VERSION ""

NS_ :

BS_:

BU_: VMCU TECU OBDScanT2 IC3 EMS ECUspare2 ECUspare1 DACU CIOM BBM

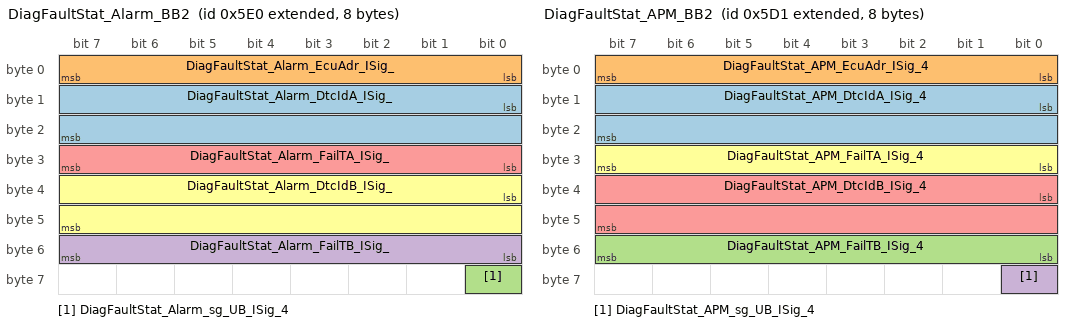
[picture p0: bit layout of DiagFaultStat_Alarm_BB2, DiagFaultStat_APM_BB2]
BO_ 2147485152 DiagFaultStat_Alarm_BB2: 8 CIOM
 SG_ DiagFaultStat_Alarm_DtcIdA_ISig_ : 8|16@1+ (1,0) [0|65535] ""  IC3
 SG_ DiagFaultStat_Alarm_EcuAdr_ISig_ : 0|8@1+ (1,0) [0|255] ""  IC3
 SG_ DiagFaultStat_Alarm_sg_UB_ISig_4 : 56|1@1+ (1,0) [0|0] ""  IC3
 SG_ DiagFaultStat_Alarm_FailTB_ISig_ : 48|8@1+ (1,0) [0|255] ""  IC3
 SG_ DiagFaultStat_Alarm_FailTA_ISig_ : 24|8@1+ (1,0) [0|255] ""  IC3
 SG_ DiagFaultStat_Alarm_DtcIdB_ISig_ : 32|16@1+ (1,0) [0|65535] ""  IC3

BO_ 2147485137 DiagFaultStat_APM_BB2: 8 VMCU
 SG_ DiagFaultStat_APM_DtcIdA_ISig_4 : 8|16@1+ (1,0) [0|65535] ""  IC3
 SG_ DiagFaultStat_APM_EcuAdr_ISig_4 : 0|8@1+ (1,0) [0|255] ""  IC3
 SG_ DiagFaultStat_APM_FailTB_ISig_4 : 48|8@1+ (1,0) [0|255] ""  IC3
 SG_ DiagFaultStat_APM_sg_UB_ISig_4 : 56|1@1+ (1,0) [0|0] ""  IC3
 SG_ DiagFaultStat_APM_DtcIdB_ISig_4 : 32|16@1+ (1,0) [0|65535] ""  IC3
 SG_ DiagFaultStat_APM_FailTA_ISig_4 : 24|8@1+ (1,0) [0|255] ""  IC3

BO_ 2147485567 Debug9_TECU_BB2: 8 TECU
 SG_ Debug_9_TECU : 0|64@1+ (1,0) [0|0] "" Vector__XXX

BO_ 2147485620 Debug9_DACU_BB2: 8 DACU
 SG_ Debug_9_DACU : 0|64@1+ (1,0) [0|0] "" Vector__XXX

BO_ 2147485566 Debug8_TECU_BB2: 8 TECU
 SG_ Debug_8_TECU : 0|64@1+ (1,0) [0|0] "" Vector__XXX

BO_ 2147485619 Debug8_DACU_BB2: 8 DACU
 SG_ Debug_8_DACU : 0|64@1+ (1,0) [0|0] "" Vector__XXX

BO_ 2147485565 Debug7_TECU_BB2: 8 TECU
 SG_ Debug_7_TECU : 0|64@1+ (1,0) [0|0] "" Vector__XXX

BO_ 2147485617 Debug7_DACU_BB2: 8 DACU
 SG_ Debug_7_DACU : 0|64@1+ (1,0) [0|0] "" Vector__XXX

BO_ 2147485618 Debug7_BBM_BB2: 8 BBM
 SG_ Debug_7_BBM : 0|64@1+ (1,0) [0|0] "" Vector__XXX

BO_ 2147485611 Debug6_VMCU_BB2: 8 VMCU
 SG_ Debug_6_VMCU : 0|64@1+ (1,0) [0|0] "" Vector__XXX

BO_ 2147485564 Debug6_TECU_BB2: 8 TECU
 SG_ Debug_6_TECU : 0|64@1+ (1,0) [0|0] "" Vector__XXX

BO_ 2147485614 Debug6_HMIIOM_BB2: 8 IC3
 SG_ Debug_6_HMIIOM : 0|64@1+ (1,0) [0|0] "" Vector__XXX

BO_ 2147485609 Debug6_EMS_BB2: 8 EMS
 SG_ Debug_6_EMS : 0|64@1+ (1,0) [0|0] "" Vector__XXX

BO_ 2147485613 Debug6_DACU_BB2: 8 DACU
 SG_ Debug_6_DACU : 0|64@1+ (1,0) [0|0] "" Vector__XXX

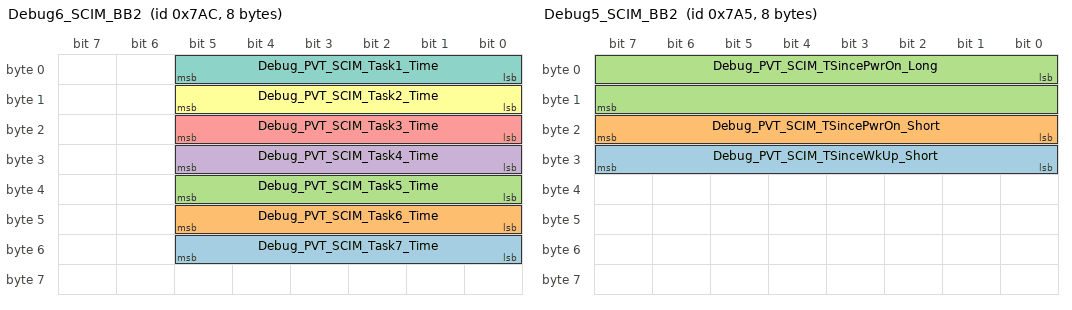
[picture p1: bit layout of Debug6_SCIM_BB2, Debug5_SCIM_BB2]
BO_ 1964 Debug6_SCIM_BB2: 8 CIOM
 SG_ Debug_PVT_SCIM_Task7_Time : 48|6@1+ (0.1,0) [0|6.3] "ms"  ECUspare1
 SG_ Debug_PVT_SCIM_Task6_Time : 40|6@1+ (0.1,0) [0|6.3] "ms"  ECUspare1
 SG_ Debug_PVT_SCIM_Task5_Time : 32|6@1+ (0.1,0) [0|6.3] "ms"  ECUspare1
 SG_ Debug_PVT_SCIM_Task4_Time : 24|6@1+ (0.1,0) [0|6.3] "ms"  ECUspare1
 SG_ Debug_PVT_SCIM_Task3_Time : 16|6@1+ (0.1,0) [0|6.3] "ms"  ECUspare1
 SG_ Debug_PVT_SCIM_Task2_Time : 8|6@1+ (0.1,0) [0|6.3] "ms"  ECUspare1
 SG_ Debug_PVT_SCIM_Task1_Time : 0|6@1+ (0.1,0) [0|6.3] "ms"  ECUspare1

BO_ 2147485615 Debug6_BBM_BB2: 8 BBM
 SG_ Debug_6_BBM : 0|64@1+ (1,0) [0|0] "" Vector__XXX

BO_ 2147485604 Debug5_VMCU_BB2: 8 VMCU
 SG_ Debug_5_VMCU : 0|64@1+ (1,0) [0|0] "" Vector__XXX

BO_ 2147485563 Debug5_TECU_BB2: 8 TECU
 SG_ Debug_5_TECU : 0|64@1+ (1,0) [0|0] "" Vector__XXX

BO_ 2147485607 Debug5_HMIIOM_BB2: 8 IC3
 SG_ Debug_5_HMIIOM : 0|64@1+ (1,0) [0|0] "" Vector__XXX

BO_ 2147485602 Debug5_EMS_BB2: 8 EMS
 SG_ Debug_5_EMS : 0|64@1+ (1,0) [0|0] "" Vector__XXX

BO_ 2147485606 Debug5_DACU_BB2: 8 DACU
 SG_ Debug_5_DACU : 0|64@1+ (1,0) [0|0] "" Vector__XXX

BO_ 1957 Debug5_SCIM_BB2: 8 CIOM
 SG_ Debug_PVT_SCIM_TSinceWkUp_Short : 24|8@1+ (20,0) [0|5100] "ms"  ECUspare1
 SG_ Debug_PVT_SCIM_TSincePwrOn_Short : 16|8@1+ (20,0) [0|5100] "ms"  ECUspare1
 SG_ Debug_PVT_SCIM_TSincePwrOn_Long : 0|16@1+ (1,0) [0|65535] "s"  ECUspare1

BO_ 2147485608 Debug5_BBM_BB2: 8 BBM
 SG_ Debug_5_BBM : 0|64@1+ (1,0) [0|0] "" Vector__XXX

BO_ 2147485597 Debug4_VMCU_BB2: 8 VMCU
 SG_ Debug_4_VMCU : 0|64@1+ (1,0) [0|0] "" Vector__XXX

BO_ 2147485562 Debug4_TECU_BB2: 8 TECU
 SG_ Debug_4_TECU : 0|64@1+ (1,0) [0|0] "" Vector__XXX

BO_ 2147485600 Debug4_HMIIOM_BB2: 8 IC3
 SG_ Debug_4_HMIIOM : 0|64@1+ (1,0) [0|0] "" Vector__XXX

BO_ 2147485595 Debug4_EMS_BB2: 8 EMS
 SG_ Debug_4_EMS : 0|64@1+ (1,0) [0|0] "" Vector__XXX

BO_ 2147485599 Debug4_DACU_BB2: 8 DACU
 SG_ Debug_4_DACU : 0|64@1+ (1,0) [0|0] "" Vector__XXX

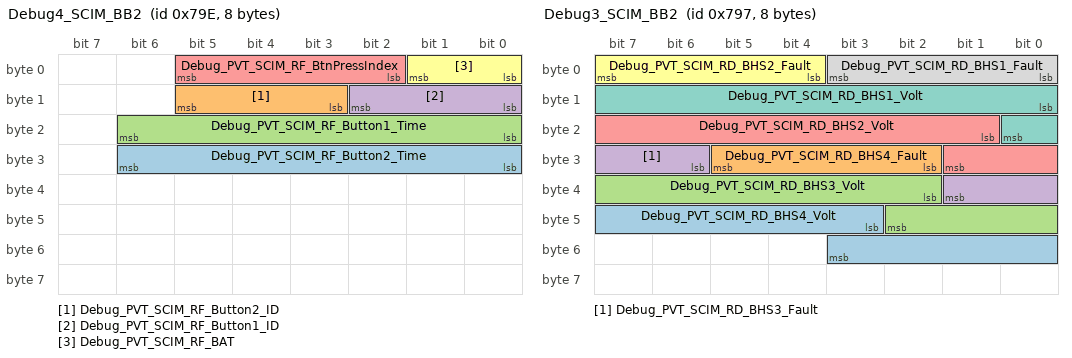
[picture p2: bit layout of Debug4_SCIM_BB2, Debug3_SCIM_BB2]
BO_ 1950 Debug4_SCIM_BB2: 8 CIOM
 SG_ Debug_PVT_SCIM_RF_Button2_Time : 24|7@1+ (1,0) [0|127] ""  ECUspare1
 SG_ Debug_PVT_SCIM_RF_Button2_ID : 11|3@1+ (1,0) [0|7] ""  ECUspare1
 SG_ Debug_PVT_SCIM_RF_Button1_Time : 16|7@1+ (1,0) [0|127] ""  ECUspare1
 SG_ Debug_PVT_SCIM_RF_Button1_ID : 8|3@1+ (1,0) [0|7] ""  ECUspare1
 SG_ Debug_PVT_SCIM_RF_BtnPressIndex : 2|4@1+ (1,0) [0|15] ""  ECUspare1
 SG_ Debug_PVT_SCIM_RF_BAT : 0|2@1+ (1,0) [0|3] ""  ECUspare1

BO_ 2147485601 Debug4_BBM_BB2: 8 BBM
 SG_ Debug_4_BBM : 0|64@1+ (1,0) [0|0] "" Vector__XXX

BO_ 2147485590 Debug3_VMCU_BB2: 8 VMCU
 SG_ Debug_3_VMCU : 0|64@1+ (1,0) [0|0] "" Vector__XXX

BO_ 2147485545 Debug3_TECU_BB2: 8 TECU
 SG_ Debug_3_TECU : 0|64@1+ (1,0) [0|0] "" Vector__XXX

BO_ 2147485593 Debug3_HMIIOM_BB2: 8 IC3
 SG_ Debug_3_HMIIOM : 0|64@1+ (1,0) [0|0] "" Vector__XXX

BO_ 2147485588 Debug3_EMS_BB2: 8 EMS
 SG_ Debug_3_EMS : 0|64@1+ (1,0) [0|0] "" Vector__XXX

BO_ 2147485592 Debug3_DACU_BB2: 8 DACU
 SG_ Debug_3_DACU : 0|64@1+ (1,0) [0|0] "" Vector__XXX

BO_ 1943 Debug3_SCIM_BB2: 8 CIOM
 SG_ Debug_PVT_SCIM_RD_BHS4_Volt : 43|9@1+ (0.1,0) [0|51] "V"  ECUspare1
 SG_ Debug_PVT_SCIM_RD_BHS4_Fault : 26|4@1+ (1,0) [0|15] "0"  ECUspare1
 SG_ Debug_PVT_SCIM_RD_BHS3_Volt : 34|9@1+ (0.1,0) [0|51] "V"  ECUspare1
 SG_ Debug_PVT_SCIM_RD_BHS3_Fault : 30|4@1+ (1,0) [0|15] "0"  ECUspare1
 SG_ Debug_PVT_SCIM_RD_BHS2_Volt : 17|9@1+ (0.1,0) [0|51] "V"  ECUspare1
 SG_ Debug_PVT_SCIM_RD_BHS2_Fault : 4|4@1+ (1,0) [0|15] "0"  ECUspare1
 SG_ Debug_PVT_SCIM_RD_BHS1_Volt : 8|9@1+ (0.1,0) [0|51] "V"  ECUspare1
 SG_ Debug_PVT_SCIM_RD_BHS1_Fault : 0|4@1+ (1,0) [0|15] "0"  ECUspare1

BO_ 2147485594 Debug3_BBM_BB2: 8 BBM
 SG_ Debug_3_BBM : 0|64@1+ (1,0) [0|0] "" Vector__XXX

BO_ 2147485583 Debug2_VMCU_BB2: 8 VMCU
 SG_ Debug_2_VMCU : 0|64@1+ (1,0) [0|0] "" Vector__XXX

BO_ 2147485544 Debug2_TECU_BB2: 8 TECU
 SG_ Debug_2_TECU : 0|64@1+ (1,0) [0|0] "" Vector__XXX

BO_ 2147485586 Debug2_HMIIOM_BB2: 8 IC3
 SG_ Debug_2_HMIIOM : 0|64@1+ (1,0) [0|0] "" Vector__XXX

BO_ 2147485581 Debug2_EMS_BB2: 8 EMS
 SG_ Debug_2_EMS : 0|64@1+ (1,0) [0|0] "" Vector__XXX

BO_ 2147485585 Debug2_DACU_BB2: 8 DACU
 SG_ Debug_2_DACU : 0|64@1+ (1,0) [0|0] "" Vector__XXX

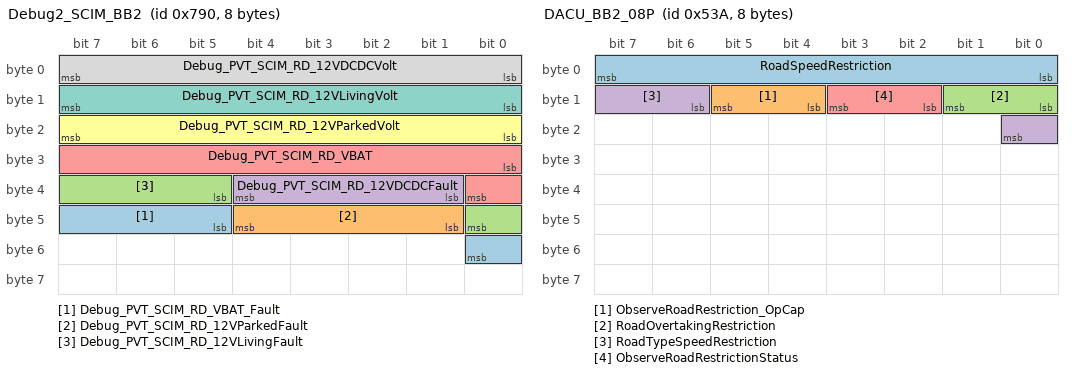
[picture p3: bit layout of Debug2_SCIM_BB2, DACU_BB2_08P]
BO_ 1936 Debug2_SCIM_BB2: 8 CIOM
 SG_ Debug_PVT_SCIM_RD_VBAT_Fault : 45|4@1+ (1,0) [0|15] ""  ECUspare1
 SG_ Debug_PVT_SCIM_RD_12VParkedFault : 41|4@1+ (1,0) [0|15] ""  ECUspare1
 SG_ Debug_PVT_SCIM_RD_12VLivingFault : 37|4@1+ (1,0) [0|15] ""  ECUspare1
 SG_ Debug_PVT_SCIM_RD_12VDCDCFault : 33|4@1+ (1,0) [0|15] ""  ECUspare1
 SG_ Debug_PVT_SCIM_RD_VBAT : 24|9@1+ (0.1,0) [0|51] "V"  ECUspare1
 SG_ Debug_PVT_SCIM_RD_12VParkedVolt : 16|8@1+ (0.25,0) [0|63] "V"  ECUspare1
 SG_ Debug_PVT_SCIM_RD_12VLivingVolt : 8|8@1+ (0.25,0) [0|63] "V"  ECUspare1
 SG_ Debug_PVT_SCIM_RD_12VDCDCVolt : 0|8@1+ (0.25,0) [0|63] "V"  ECUspare1

BO_ 2147485587 Debug2_BBM_BB2: 8 BBM
 SG_ Debug_2_BBM : 0|64@1+ (1,0) [0|0] "" Vector__XXX

BO_ 2147485616 Debug21_TECU_BB2: 8 TECU
 SG_ Debug_21_TECU : 0|64@1+ (1,0) [0|0] "" Vector__XXX

BO_ 2147485610 Debug20_TECU_BB2: 8 TECU
 SG_ Debug_20_TECU : 0|64@1+ (1,0) [0|0] "" Vector__XXX

BO_ 2147485576 Debug1_VMCU_BB2: 8 Vector__XXX
 SG_ Debug_1_VMCU : 0|64@1+ (1,0) [0|0] ""  VMCU

BO_ 2147485575 Debug1_TECU_BB2: 8 Vector__XXX
 SG_ Debug_1_TECU : 0|64@1+ (1,0) [0|0] ""  TECU

BO_ 2147485579 Debug1_HMIIOM_BB2: 8 Vector__XXX
 SG_ Debug_1_HMIIOM : 0|64@1+ (1,0) [0|0] ""  IC3

BO_ 2147485574 Debug1_EMS_BB2: 8 Vector__XXX
 SG_ Debug_1_EMS : 0|64@1+ (1,0) [0|0] ""  EMS

BO_ 2147485578 Debug1_DACU_BB2: 8 Vector__XXX
 SG_ Debug_1_DACU : 0|64@1+ (1,0) [0|0] ""  DACU

BO_ 1929 Debug1_CIOM_BB2: 8 ECUspare1
 SG_ Debug_1_CIOM : 16|64@1+ (1,0) [0|0] "" Vector__XXX

BO_ 2147485580 Debug1_BBM_BB2: 8 Vector__XXX
 SG_ Debug_1_BBM : 0|64@1+ (1,0) [0|0] ""  BBM

BO_ 2147485603 Debug19_TECU_BB2: 8 TECU
 SG_ Debug_19_TECU : 0|64@1+ (1,0) [0|0] "" Vector__XXX

BO_ 2147485596 Debug18_TECU_BB2: 8 TECU
 SG_ Debug_18_TECU : 0|64@1+ (1,0) [0|0] "" Vector__XXX

BO_ 2147485589 Debug17_TECU_BB2: 8 TECU
 SG_ Debug_17_TECU : 0|64@1+ (1,0) [0|0] "" Vector__XXX

BO_ 2147485582 Debug16_TECU_BB2: 8 TECU
 SG_ Debug_16_TECU : 0|64@1+ (1,0) [0|0] "" Vector__XXX

BO_ 2147485573 Debug15_TECU_BB2: 8 TECU
 SG_ Debug_15_TECU : 0|64@1+ (1,0) [0|0] "" Vector__XXX

BO_ 2147485572 Debug14_TECU_BB2: 8 TECU
 SG_ Debug_14_TECU : 0|64@1+ (1,0) [0|0] "" Vector__XXX

BO_ 2147485571 Debug13_TECU_BB2: 8 TECU
 SG_ Debug_13_TECU : 0|64@1+ (1,0) [0|0] "" Vector__XXX

BO_ 2147485570 Debug12_TECU_BB2: 8 TECU
 SG_ Debug_12_TECU : 0|64@1+ (1,0) [0|0] "" Vector__XXX

BO_ 2147485569 Debug11_TECU_BB2: 8 TECU
 SG_ Debug_11_TECU : 0|64@1+ (1,0) [0|0] "" Vector__XXX

BO_ 2147485622 Debug11_DACU_BB2: 8 DACU
 SG_ Debug_11_DACU : 0|64@1+ (1,0) [0|0] "" Vector__XXX

BO_ 2634017304 Debug10_TECU_BB2: 8 TECU
 SG_ Debug_10_TECU : 0|64@1+ (1,0) [0|0] "" Vector__XXX

BO_ 2634021456 Debug10_DACU_BB2: 8 DACU
 SG_ Debug_10_DACU : 0|64@1+ (1,0) [0|0] "" Vector__XXX

BO_ 1338 DACU_BB2_08P: 8 DACU
 SG_ RoadSpeedRestriction : 0|8@1+ (1,0) [0|255] "NotApplicable"  IC3
 SG_ ObserveRoadRestriction_OpCap : 12|2@1+ (1,0) [0|0] ""  IC3
 SG_ RoadOvertakingRestriction : 8|2@1+ (1,0) [0|0] ""  IC3
 SG_ RoadTypeSpeedRestriction : 14|3@1+ (1,0) [0|0] ""  IC3
 SG_ ObserveRoadRestrictionStatus : 10|2@1+ (1,0) [0|0] ""  IC3

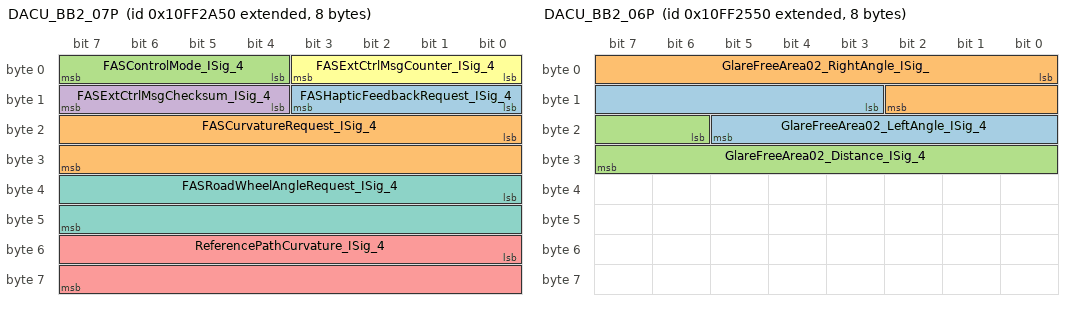
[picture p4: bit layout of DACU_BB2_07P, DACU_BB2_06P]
BO_ 2432641616 DACU_BB2_07P: 8 DACU
 SG_ FASHapticFeedbackRequest_ISig_4 : 8|4@1+ (1,0) [0|0] ""  VMCU
 SG_ FASCurvatureRequest_ISig_4 : 16|16@1+ (7.62939E-006,-0.2472) [-0.2472|0.25279207365] "per_meter"  VMCU
 SG_ FASControlMode_ISig_4 : 4|4@1+ (0.1,0) [0|1.5] ""  VMCU
 SG_ FASExtCtrlMsgChecksum_ISig_4 : 12|4@1+ (1,0) [0|0] ""  VMCU
 SG_ ReferencePathCurvature_ISig_4 : 48|16@1+ (7.62939E-006,-0.2472) [-0.2472|0.25279207365] "per_meter"  VMCU
 SG_ FASExtCtrlMsgCounter_ISig_4 : 0|4@1+ (1,0) [0|0] ""  VMCU
 SG_ FASRoadWheelAngleRequest_ISig_4 : 32|16@1+ (5E-005,-1.6) [-1.6|1.67675] "rad"  VMCU

BO_ 2432640336 DACU_BB2_06P: 8 DACU
 SG_ GlareFreeArea02_LeftAngle_ISig_4 : 11|11@1+ (0.0494,-31.65) [-31.65|69.4718] "deg"  VMCU
 SG_ GlareFreeArea02_RightAngle_ISig_ : 0|11@1+ (0.0494,-31.65) [-31.65|69.4718] "deg"  VMCU
 SG_ GlareFreeArea02_Distance_ISig_4 : 22|10@1+ (0.5,0) [0|511.5] "m"  VMCU

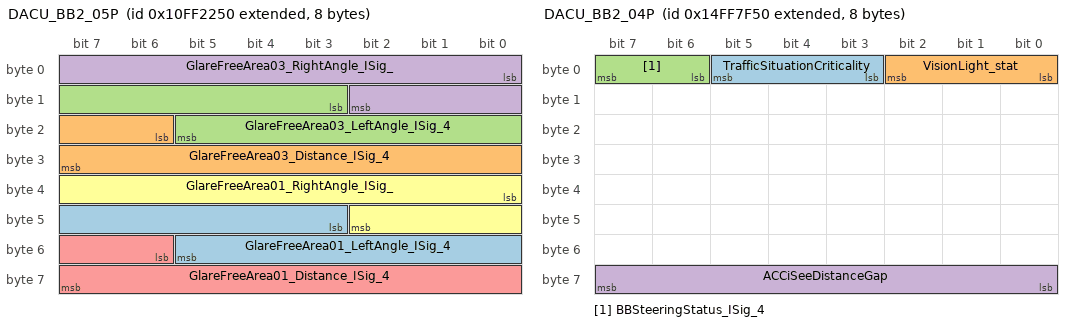
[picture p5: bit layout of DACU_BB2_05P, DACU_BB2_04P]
BO_ 2432639568 DACU_BB2_05P: 8 DACU
 SG_ GlareFreeArea01_LeftAngle_ISig_4 : 43|11@1+ (0.0494,-31.65) [-31.65|69.4718] "deg"  VMCU
 SG_ GlareFreeArea03_Distance_ISig_4 : 22|10@1+ (0.5,0) [0|511.5] "m"  VMCU
 SG_ GlareFreeArea03_LeftAngle_ISig_4 : 11|11@1+ (0.0494,-31.65) [-31.65|69.4718] "deg"  VMCU
 SG_ GlareFreeArea03_RightAngle_ISig_ : 0|11@1+ (0.0494,-31.65) [-31.65|69.4718] "deg"  VMCU
 SG_ GlareFreeArea01_Distance_ISig_4 : 54|10@1+ (0.5,0) [0|511.5] "m"  VMCU
 SG_ GlareFreeArea01_RightAngle_ISig_ : 32|11@1+ (0.0494,-31.65) [-31.65|69.4718] "deg"  VMCU

BO_ 2499772240 DACU_BB2_04P: 8 DACU
 SG_ TrafficSituationCriticality : 3|3@1+ (1,0) [0|7] ""  IC3
 SG_ VisionLight_stat : 0|3@1+ (1,0) [0|0] ""  VMCU
 SG_ BBSteeringStatus_ISig_4 : 6|2@1+ (1,0) [0|0] ""  BBM
 SG_ ACCiSeeDistanceGap : 56|8@1+ (1,-127) [-127|128] "m"  TECU

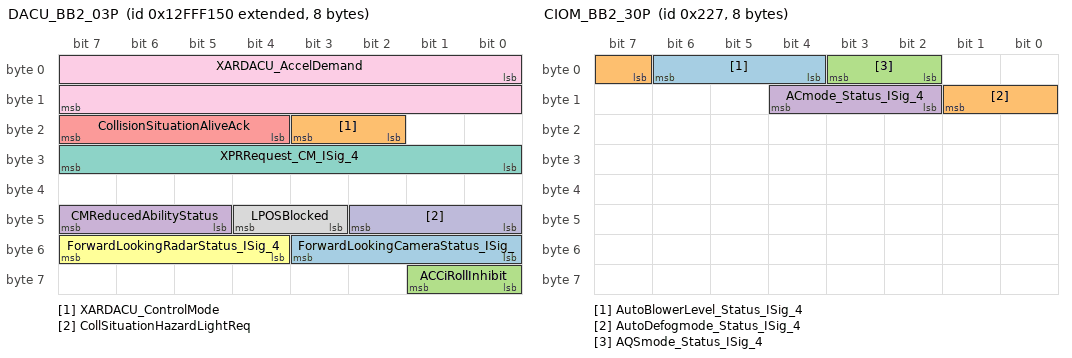
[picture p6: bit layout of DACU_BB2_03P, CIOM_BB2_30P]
BO_ 2466246992 DACU_BB2_03P: 8 DACU
 SG_ ForwardLookingCameraStatus_ISig_ : 48|4@1+ (1,0) [0|0] ""  IC3
 SG_ XARDACU_ControlMode : 18|2@1+ (1,0) [0|0] ""  EMS,TECU
 SG_ ACCiRollInhibit : 56|2@1+ (1,0) [0|0] ""  TECU
 SG_ CMReducedAbilityStatus : 45|3@1+ (1,0) [0|0] ""  IC3
 SG_ CollisionSituationAliveAck : 20|4@1+ (1,0) [0|15] "Count"  VMCU
 SG_ ForwardLookingRadarStatus_ISig_4 : 52|4@1+ (1,0) [0|0] ""  IC3
 SG_ XPRRequest_CM_ISig_4 : 24|8@1+ (1,0) [0|255] "NotApplicable"  VMCU
 SG_ LPOSBlocked : 43|2@1+ (1,0) [0|0] ""  IC3
 SG_ XARDACU_AccelDemand : 0|16@1+ (0.00048828125,-15.687) [-15.687|16.31251171875] "m_per_s_squared"  EMS,TECU
 SG_ CollSituationHazardLightReq : 40|3@1+ (1,0) [0|0] ""  VMCU

BO_ 2432690512 DACU_BB2_02P: 8 DACU
 SG_ PathDeviationDriverAlert : 24|3@1+ (1,0) [0|0] ""  IC3,VMCU
 SG_ CM_DisengageDrivelineRequest : 51|2@1+ (1,0) [0|0] ""  TECU
 SG_ ACCBrakeRequestStatus : 30|2@1+ (1,0) [0|0] ""  VMCU
 SG_ FrontalCollisionDriverAlert_ISig : 19|3@1+ (1,0) [0|0] ""  IC3,VMCU
 SG_ ACC_SGOFaultCondStat_SeatBelt : 59|1@1+ (1,0) [0|0] ""  IC3
 SG_ CM_Status_ISig_4 : 43|3@1+ (1,0) [0|0] ""  CIOM,VMCU,IC3
 SG_ DASApplicationStatus : 40|3@1+ (1,0) [0|0] ""  IC3,VMCU,CIOM
 SG_ ACC_Status : 16|3@1+ (1,0) [0|0] ""  VMCU,IC3,TECU
 SG_ LKSApplicationStatus : 27|3@1+ (1,0) [0|0] ""  CIOM,VMCU,IC3
 SG_ LCSSystemStatus : 48|3@1+ (1,0) [0|0] ""  IC3,CIOM
 SG_ ACC_SGOFaultCondStat_SigStat : 60|1@1+ (1,0) [0|0] ""  IC3
 SG_ ACC_SGOFaultCondStat_Target : 58|1@1+ (1,0) [0|0] ""  IC3
 SG_ FCW_Status : 46|2@1+ (1,0) [0|0] ""  IC3,CIOM,VMCU
 SG_ DriverImpairedDriverAlert : 32|3@1+ (1,0) [0|0] ""  IC3,VMCU
 SG_ DriverVigilanceLevel : 35|3@1+ (1,0) [0|0] ""  IC3,VMCU
 SG_ ACCForwardVehicleSpeed_ISig_4 : 8|8@1+ (1,0) [0|255] "Km_per_h"  TECU,IC3
 SG_ ACC_SGOFaultCondStat_Door : 57|1@1+ (1,0) [0|0] ""  IC3
 SG_ ACCTargetDetected : 22|2@1+ (1,0) [0|0] ""  IC3
 SG_ ACCForwardVehicleDistance_ISig_4 : 0|8@1+ (1,0) [0|255] "m"  IC3,TECU
 SG_ LKSCorrectiveSteeringStatus : 61|3@1+ (1,0) [0|0] ""  CIOM
 SG_ ACC_SGOFaultCondStat_Other : 55|1@1+ (1,0) [0|0] ""  IC3
 SG_ LCSSoundSettingStatus : 53|2@1+ (1,0) [0|0] ""  IC3
 SG_ ACC_SGOFaultCondStat_Speed : 56|1@1+ (1,0) [0|0] ""  IC3

BO_ 936 CIOM_BB2_32S_FCM: 8 TECU
 SG_ CIOM_BB2_32S_FCS : 0|64@1+ (1,0) [0|0] ""  CIOM

BO_ 935 CIOM_BB2_32S: 16 CIOM
 SG_ EncryptedGBUnlockAuth_stat : 0|128@1+ (1,0) [0|0] ""  TECU

BO_ 1369 CIOM_BB2_31S: 8 CIOM
 SG_ ParkClimTimerStat_Tue_ISig_4 : 15|1@1+ (1,0) [0|0] ""  IC3
 SG_ ParkClimTimerStat_Mon_ISig_4 : 17|1@1+ (1,0) [0|0] ""  IC3
 SG_ ParkClimTimerStat_Hrs_ISig_4 : 31|8@1+ (1,0) [0|255] "h"  IC3
 SG_ ParkClimTimerStat_TotalNoTimers_ : 23|8@1+ (1,0) [0|0] ""  IC3
 SG_ ParkClimTimerStat_Thu_ISig_4 : 16|1@1+ (1,0) [0|0] ""  IC3
 SG_ ParkClimTimerStat_MinRes_ISig_4 : 7|3@1+ (1,0) [0|0] ""  IC3
 SG_ ParkClimTimerStat_Status_ISig_4 : 13|2@1+ (1,0) [0|0] ""  IC3
 SG_ ParkClimTimerStat_Sun_ISig_4 : 20|1@1+ (1,0) [0|0] ""  IC3
 SG_ ParkClimTimerStat_sg_UB_ISig_4 : 63|1@1+ (1,0) [0|0] ""  IC3
 SG_ ParkClimTimerStat_TimerNr_ISig_4 : 39|8@1+ (1,0) [0|0] ""  IC3
 SG_ ParkClimTimerStat_Rec_ISig_4 : 19|1@1+ (1,0) [0|0] ""  IC3
 SG_ ParkClimTimerStat_Wed_ISig_4 : 22|1@1+ (1,0) [0|0] ""  IC3
 SG_ ParkClimTimerStat_Min_ISig_4 : 55|8@1+ (1,0) [0|255] "min"  IC3
 SG_ ParkClimTimerStat_Type_ISig_4 : 10|3@1+ (1,0) [0|0] ""  IC3
 SG_ ParkClimTimerStat_Sat_ISig_4 : 21|1@1+ (1,0) [0|0] ""  IC3
 SG_ ParkClimTimerStat_Temp_ISig_4 : 47|8@1+ (0.5,0) [0|127.5] "DegreeC"  IC3
 SG_ ParkClimTimerStat_Dur_ISig_4 : 0|7@1+ (1,0) [0|127] "min"  IC3
 SG_ ParkClimTimerStat_Fri_ISig_4 : 18|1@1+ (1,0) [0|0] ""  IC3

BO_ 551 CIOM_BB2_30P: 8 CIOM
 SG_ AutoBlowerLevel_Status_ISig_4 : 4|3@1+ (1,0) [0|0] ""  IC3
 SG_ AutoDefogmode_Status_ISig_4 : 7|3@1+ (1,0) [0|0] ""  IC3
 SG_ AQSmode_Status_ISig_4 : 2|2@1+ (1,0) [0|0] ""  IC3
 SG_ ACmode_Status_ISig_4 : 10|3@1+ (1,0) [0|0] ""  IC3

BO_ 2432685120 CIOM_BB2_29P: 8 CIOM
 SG_ LKSCSEnableSwitch_rqst : 0|2@1+ (1,0) [0|0] ""  DACU

BO_ 2566078272 CIOM_BB2_28P: 8 CIOM
 SG_ TrafficAccidentHazardLightRqst_I : 4|2@1+ (1,0) [0|0] ""  VMCU
 SG_ GearboxUnlockAuth_stat : 6|3@1+ (1,0) [0|0] ""  TECU

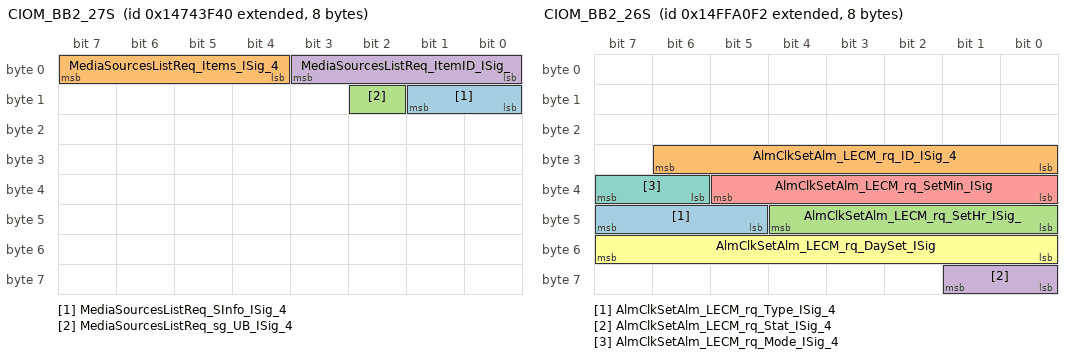
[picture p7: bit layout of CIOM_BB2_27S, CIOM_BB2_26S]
BO_ 2490646336 CIOM_BB2_27S: 8 CIOM
 SG_ MediaSourcesListReq_SInfo_ISig_4 : 8|2@1+ (1,0) [0|0] ""  IC3
 SG_ MediaSourcesListReq_Items_ISig_4 : 4|4@1+ (1,0) [0|0] ""  IC3
 SG_ MediaSourcesListReq_sg_UB_ISig_4 : 10|1@1+ (1,0) [0|0] ""  IC3
 SG_ MediaSourcesListReq_ItemID_ISig_ : 0|4@1+ (1,0) [0|0] ""  IC3

BO_ 2499780850 CIOM_BB2_26S: 8 CIOM
 SG_ AlmClkSetAlm_LECM_rq_Type_ISig_4 : 45|3@1+ (1,0) [0|0] ""  VMCU
 SG_ AlmClkSetAlm_LECM_rq_ID_ISig_4 : 24|7@1+ (1,0) [0|0] ""  VMCU
 SG_ AlmClkSetAlm_LECM_rq_SetHr_ISig_ : 40|5@1+ (1,0) [0|31] "h"  VMCU
 SG_ AlmClkSetAlm_LECM_rq_Stat_ISig_4 : 56|2@1+ (1,0) [0|0] ""  VMCU
 SG_ AlmClkSetAlm_LECM_rq_SetMin_ISig : 32|6@1+ (1,0) [0|63] "min"  VMCU
 SG_ AlmClkSetAlm_LECM_rq_DaySet_ISig : 48|8@1+ (1,0) [0|255] ""  VMCU
 SG_ AlmClkSetAlm_LECM_rq_Mode_ISig_4 : 38|2@1+ (1,0) [0|0] ""  VMCU

BO_ 2482978624 CIOM_BB2_25P: 8 CIOM
 SG_ TipperTailGateRequest_UB_ISig_4 : 23|1@1+ (1,0) [0|0] ""  BBM
 SG_ ExtraHeating_status_ISig_4 : 32|2@1+ (1,0) [0|0] ""  IC3
 SG_ FrontalCollisionAccidentStatus_I : 39|2@1+ (1,0) [0|0] ""  DACU
 SG_ LoadDistributionRequested_UB_ISi : 36|1@1+ (1,0) [0|0] ""  VMCU
 SG_ TipperUpDownRequest_ISig_4 : 17|3@1+ (1,0) [0|0] ""  BBM
 SG_ TipperTarpaulinRequest_UB_ISig_4 : 27|1@1+ (1,0) [0|0] ""  BBM
 SG_ LoadDistributionRequested_ISig_4 : 28|4@1+ (1,0) [0|0] ""  VMCU
 SG_ TipperShakerRequest_UB_ISig_4 : 21|1@1+ (1,0) [0|0] ""  BBM
 SG_ TailLiftMotionRequest_UB_ISig_4 : 20|1@1+ (1,0) [0|0] ""  BBM
 SG_ TipperTailGateRequest_ISig_4 : 8|3@1+ (1,0) [0|0] ""  BBM
 SG_ TipperTippingBodySelection_ISig_ : 6|2@1+ (1,0) [0|0] ""  BBM
 SG_ TipperEmergencyStop_ISig_4 : 0|2@1+ (1,0) [0|0] ""  BBM
 SG_ TipperTippingBodySelection_UB_IS : 26|1@1+ (1,0) [0|0] ""  BBM
 SG_ ExtraBbWrcWatchdog_ISig_4 : 2|2@1+ (1,0) [0|0] ""  BBM
 SG_ TipperEmergencyStop_UB_ISig_4 : 25|1@1+ (1,0) [0|0] ""  BBM
 SG_ AutoFrontWheelDriveDrvReq : 37|2@1+ (1,0) [0|0] ""  VMCU
 SG_ ShortStopHeater_cmd_ISig_4 : 34|2@1+ (1,0) [0|0] ""  VMCU
 SG_ TipperUpDownRequest_UB_ISig_4 : 24|1@1+ (1,0) [0|0] ""  BBM
 SG_ TailLiftMotionRequest_ISig_4 : 14|3@1+ (1,0) [0|0] ""  BBM
 SG_ TipperShakerRequest_ISig_4 : 4|2@1+ (1,0) [0|0] ""  BBM
 SG_ TipperTarpaulinRequest_ISig_4 : 11|3@1+ (1,0) [0|0] ""  BBM
 SG_ ExtraBbWrcWatchdog_UB_ISig_4 : 22|1@1+ (1,0) [0|0] ""  BBM
 SG_ ABSInhibitRqstDenied : 41|2@1+ (1,0) [0|0] ""  IC3

BO_ 2516513011 CIOM_BB2_21S: 8 CIOM
 SG_ DynamicCode_value : 0|32@1+ (1,0) [0|4294967295] "NotApplicable"  IC3

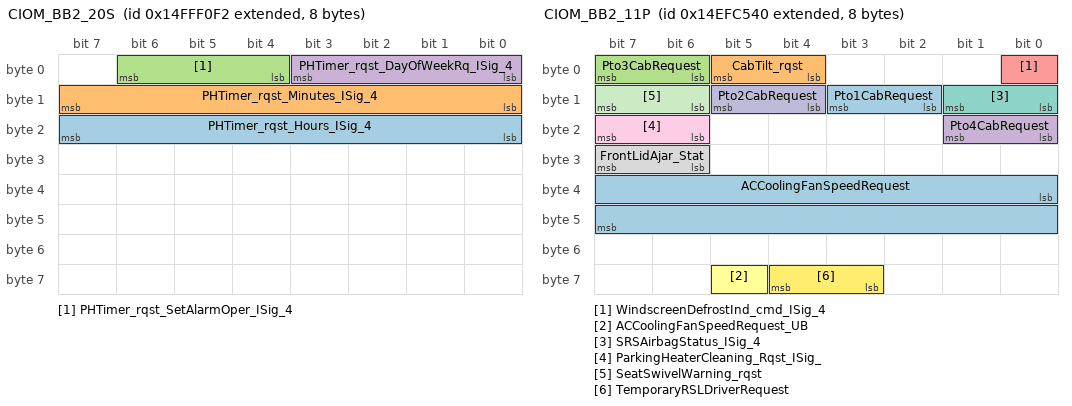
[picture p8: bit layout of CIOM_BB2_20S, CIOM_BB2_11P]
BO_ 2499801330 CIOM_BB2_20S: 8 CIOM
 SG_ PHTimer_rqst_Hours_ISig_4 : 16|8@1+ (1,0) [0|255] "h"  VMCU
 SG_ PHTimer_rqst_Minutes_ISig_4 : 8|8@1+ (1,0) [0|255] "min"  VMCU
 SG_ PHTimer_rqst_SetAlarmOper_ISig_4 : 4|3@1+ (1,0) [0|0] ""  VMCU
 SG_ PHTimer_rqst_DayOfWeekRq_ISig_4 : 0|4@1+ (1,0) [0|0] ""  VMCU

BO_ 2499764033 CIOM_BB2_13S_FCM: 8 EMS
 SG_ CIOM_BB2_13S_FCS : 0|64@1+ (1,0) [0|0] ""  CIOM

BO_ 2499764032 CIOM_BB2_13S: 16 CIOM
 SG_ EngineStartAuth_stat : 0|128@1+ (1,0) [0|0] ""  EMS

BO_ 2499747649 CIOM_BB2_12S_FCM: 8 VMCU
 SG_ CIOM_BB2_12S_FCS : 0|64@1+ (1,0) [0|0] ""  CIOM

BO_ 2499747648 CIOM_BB2_12S: 16 CIOM
 SG_ KeyAuthEncrypted_stat : 0|128@1+ (1,0) [0|0] ""  VMCU

BO_ 2498741568 CIOM_BB2_11P: 8 CIOM
 SG_ ACCoolingFanSpeedRequest : 32|16@1+ (1,0) [0|65535] "rpm"  EMS
 SG_ CabTilt_rqst : 4|2@1+ (1,0) [0|0] ""  VMCU
 SG_ Pto3CabRequest : 6|2@1+ (1,0) [0|0] ""  BBM,VMCU
 SG_ Pto4CabRequest : 16|2@1+ (1,0) [0|0] ""  VMCU,BBM
 SG_ WindscreenDefrostInd_cmd_ISig_4 : 0|1@1+ (1,0) [0|0] ""  BBM
 SG_ ACCoolingFanSpeedRequest_UB : 61|1@1+ (1,0) [0|0] ""  EMS
 SG_ SRSAirbagStatus_ISig_4 : 8|2@1+ (1,0) [0|0] ""  IC3,VMCU
 SG_ FrontLidAjar_Stat : 30|2@1+ (1,0) [0|0] ""  VMCU
 SG_ ParkingHeaterCleaning_Rqst_ISig_ : 22|2@1+ (1,0) [0|0] ""  IC3
 SG_ Pto2CabRequest : 12|2@1+ (1,0) [0|0] ""  BBM,VMCU
 SG_ SeatSwivelWarning_rqst : 14|2@1+ (1,0) [0|0] ""  IC3
 SG_ TemporaryRSLDriverRequest : 59|2@1+ (1,0) [0|0] ""  VMCU
 SG_ Pto1CabRequest : 10|2@1+ (1,0) [0|0] ""  VMCU,BBM

BO_ 2483023936 CIOM_BB2_10P: 8 CIOM
 SG_ LCS_EnableSwitch_rqst : 40|2@1+ (1,0) [0|0] ""  DACU
 SG_ EscCrossCountryActivation_rqst : 52|2@1+ (1,0) [0|0] ""  VMCU
 SG_ StaticCornerLightMode : 54|2@1+ (1,0) [0|0] ""  VMCU
 SG_ SplitBoxDifflockActvnDrvrRqst_IS : 48|2@1+ (1,0) [0|0] ""  EMS,VMCU,TECU
 SG_ ATCFrontWheelDriveRequest : 61|2@1+ (1,0) [0|0] ""  VMCU
 SG_ ConstructionSwitch_stat : 50|2@1+ (1,0) [0|0] ""  TECU
 SG_ EscCabActionRequest : 8|3@1+ (1,0) [0|0] ""  VMCU
 SG_ AdjustRequestForIdle : 58|3@1+ (1,0) [0|0] ""  VMCU
 SG_ SCL_LogicPowerOutput_stat : 36|2@1+ (1,0) [0|0] ""  VMCU
 SG_ PinCode_validity_time : 0|8@1+ (1,1) [1|256] "h"  IC3
 SG_ StatTrailerBrakeSwitchStatus : 14|2@1+ (1,0) [0|0] ""  VMCU
 SG_ SplitBoxDifflockActvnDrvrRqst_UB : 32|1@1+ (1,0) [0|0] ""  EMS,TECU,VMCU,IC3
 SG_ RoofHatch_HMI_rqst : 16|3@1+ (1,0) [0|0] ""  VMCU
 SG_ EscCabEnable : 38|2@1+ (1,0) [0|0] ""  VMCU
 SG_ ExtraSideMarkers_Rqst : 19|2@1+ (1,0) [0|0] ""  VMCU
 SG_ LevelingThumbwheel_stat : 24|5@1+ (1,0) [0|0] ""  VMCU
 SG_ DASActivation_rqst : 44|2@1+ (1,0) [0|0] ""  DACU
 SG_ DriverSeatBeltSwitch_ISig_4 : 22|2@1+ (1,0) [0|0] ""  VMCU,DACU,BBM,IC3
 SG_ PinCode_stat : 29|3@1+ (1,0) [0|0] ""  IC3
 SG_ WarmUp_Request : 56|2@1+ (1,0) [0|0] ""  EMS
 SG_ LKSEnableSwitch_rqst : 46|2@1+ (1,0) [0|0] ""  DACU

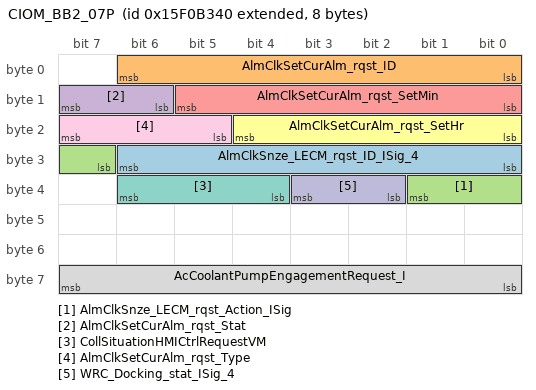
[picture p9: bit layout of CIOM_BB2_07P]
BO_ 2515579712 CIOM_BB2_07P: 8 CIOM
 SG_ AlmClkSnze_LECM_rqst_ID_ISig_4 : 24|7@1+ (1,0) [0|0] ""  VMCU
 SG_ AlmClkSetCurAlm_rqst_ID : 0|7@1+ (1,0) [0|0] ""  VMCU
 SG_ AlmClkSnze_LECM_rqst_Action_ISig : 31|3@1+ (1,0) [0|0] ""  VMCU
 SG_ AlmClkSetCurAlm_rqst_Stat : 14|2@1+ (1,0) [0|0] ""  VMCU
 SG_ AlmClkSetCurAlm_rqst_SetMin : 8|6@1+ (1,0) [0|63] "min"  VMCU
 SG_ AlmClkSetCurAlm_rqst_SetHr : 16|5@1+ (1,0) [0|31] "h"  VMCU
 SG_ CollSituationHMICtrlRequestVM : 36|3@1+ (1,0) [0|0] ""  IC3
 SG_ AcCoolantPumpEngagementRequest_I : 56|8@1+ (0.4,0) [0|102] "Percent"  EMS
 SG_ AlmClkSetCurAlm_rqst_Type : 21|3@1+ (1,0) [0|0] ""  VMCU
 SG_ WRC_Docking_stat_ISig_4 : 34|2@1+ (1,0) [0|0] ""  IC3

BO_ 2482995008 CIOM_BB2_06P: 8 CIOM
 SG_ LiftAxle1DirectControl_UB_ISig_4 : 59|1@1+ (1,0) [0|0] ""  VMCU
 SG_ MirrorSelectRightMainBtn_stat_IS : 30|2@1+ (1,0) [0|0] ""  IC3
 SG_ WRCEngineStopRequest_ISig_4 : 38|2@1+ (1,0) [0|0] ""  BBM
 SG_ LiftAxle1DirectControl_ISig_4 : 56|3@1+ (1,0) [0|0] ""  VMCU
 SG_ MirrorSelectRightWideBtn_stat_IS : 6|2@1+ (1,0) [0|0] ""  IC3
 SG_ PanicAlarmFromKeyfob_rqst : 2|2@1+ (1,0) [0|0] ""  VMCU
 SG_ ParkingClimate_IndicationCmd_ISi : 51|3@1+ (1,0) [0|0] ""  IC3
 SG_ MirrorSelectLeftWideBtn_stat_ISi : 4|2@1+ (1,0) [0|0] ""  IC3
 SG_ WRCEngineStartRequest_ISig_4 : 36|2@1+ (1,0) [0|0] ""  BBM
 SG_ PW_Left_DS_SwStatus_ISig_4 : 19|3@1+ (1,0) [0|0] ""  IC3
 SG_ RegenerationSwitchStatus : 48|3@1+ (1,0) [0|0] ""  IC3
 SG_ PW_Right_DS_SwStatus_ISig_4 : 24|3@1+ (1,0) [0|0] ""  IC3
 SG_ DoorLock_stat_ISig_4 : 8|4@1+ (1,0) [0|0] ""  BBM,IC3
 SG_ WRCEngineStartRequest_UB_ISig_4 : 40|1@1+ (1,0) [0|0] ""  BBM
 SG_ LuggageAjar_stat : 32|3@1+ (1,0) [0|0] ""  IC3
 SG_ AlarmStatus_stat_ISig_4 : 44|4@1+ (1,0) [0|0] ""  IC3
 SG_ AlarmTriggeringCause_stat_ISig_4 : 12|4@1+ (1,0) [0|0] ""  BBM,IC3
 SG_ DoorsAjar_stat_UB_ISig_4 : 35|1@1+ (1,0) [0|0] ""  DACU,VMCU,IC3,BBM
 SG_ DoorsAjar_stat_ISig_4 : 16|3@1+ (1,0) [0|0] ""  IC3,VMCU,DACU,BBM
 SG_ WRCEngineStopRequest_UB_ISig_4 : 41|1@1+ (1,0) [0|0] ""  BBM
 SG_ DoorAutoFunction_rqst : 22|2@1+ (1,0) [0|0] ""  VMCU
 SG_ MirrorSelectLeftMainBtn_stat_ISi : 0|2@1+ (1,0) [0|0] ""  IC3

CM_ SG_ 2466246992 XARDACU_AccelDemand "65024 - 65279 Error ; 65280 - 65535 Not available";
CM_ SG_ 2432690512 ACCForwardVehicleSpeed_ISig_4 "254 Error ; 255 Not available";
CM_ SG_ 2432690512 ACCForwardVehicleDistance_ISig_4 "254 Error ; 255 Not Available";
CM_ SG_ 2499780850 AlmClkSetAlm_LECM_rq_SetHr_ISig_ "30 Error ; 31 Not Available";
CM_ SG_ 2499780850 AlmClkSetAlm_LECM_rq_SetMin_ISig "62 Error ; 63 Not Available";
CM_ SG_ 2499801330 PHTimer_rqst_Hours_ISig_4 "254 Error ; 255 Not available";
CM_ SG_ 2499801330 PHTimer_rqst_Minutes_ISig_4 "254 Error ; 255 Not available";
CM_ SG_ 2498741568 ACCoolingFanSpeedRequest "65024 - 65279 Error ; 65280 - 65535 Not available";
BA_DEF_ BO_  "GenMsgStartDelayTime" INT 0 0;
BA_DEF_ BO_  "GenMsgDelayTime" INT 0 0;
BA_DEF_ BO_  "GenMsgCycleTime" INT 0 0;
BA_DEF_ BO_  "GenMsgSendType" ENUM  "Cyclic","NotUsed","NotUsed","NotUsed","NotUsed","NotUsed","NotUsed","IfActive","NoMsgSendType","NotUsed";
BA_DEF_ SG_  "GenSigStartValue" INT 0 0;
BA_DEF_ SG_  "GenSigCycleTimeActive" INT 0 0;
BA_DEF_ SG_  "GenSigCycleTime" INT 0 0;
BA_DEF_ SG_  "GenSigSendType" ENUM  "Cyclic","OnWrite","OnWriteWithRepetition","OnChange","OnChangeWithRepetition","IfActive","IfActiveWithRepetition","NoSigSendType","NotUsed","NotUsed","NotUsed","NotUsed","NotUsed";
BA_DEF_ BO_  "VFrameFormat" ENUM  "StandardCAN","ExtendedCAN","reserved","J1939PG";
BA_DEF_ SG_  "SigType" ENUM  "Default","Range","RangeSigned","ASCII","Discrete","Control","ReferencePGN","DTC","StringDelimiter","StringLength","StringLengthControl";
BA_DEF_ SG_  "SeToolVersion_SIGNAL" STRING ;
BA_DEF_ SG_  "SeToolUniqueID_SIGNAL" STRING ;
BA_DEF_ SG_  "SeToolOwnerSigGroup_SIGNAL" STRING ;
BA_DEF_ SG_  "SeToolOwnerSigGroupID_SIGNAL" STRING ;
BA_DEF_ SG_  "SeToolName_SIGNAL" STRING ;
BA_DEF_ SG_  "SeToolItemID_SIGNAL" STRING ;
BA_DEF_ SG_  "SeToolAncestorID_SIGNAL" STRING ;
BA_DEF_ SG_  "Platform_VMCU1_Sig" ENUM  "No","Yes";
BA_DEF_ BO_  "NmAsrMessage" ENUM  "No","Yes";
BA_DEF_ SG_  "NeedsUpdateBit" ENUM  "No","Yes";
BA_DEF_ SG_  "MmAnSignal" ENUM  "No","Yes";
BA_DEF_ SG_  "GenSigMaxLatency" INT 0 65535;
BA_DEF_ SG_  "GenSigILSupport" ENUM  "Yes","No";
BA_DEF_ BO_  "GenMsgRequestable" INT 0 1;
BA_DEF_ BO_  "GenMsgILSupport" ENUM  "No","Yes";
BA_DEF_ BO_  "DiagUUDTResponse" ENUM  "No","Yes";
BA_DEF_ BO_  "DiagState" ENUM  "No","Yes";
BA_DEF_ BO_  "DiagResponse" ENUM  "No","Yes";
BA_DEF_ BO_  "DiagRequest" ENUM  "No","Yes";
BA_DEF_ BO_  "DiagConnection" HEX 0 65535;
BA_DEF_ BO_  "CanTpSTmin" INT 0 255;
BA_DEF_ BO_  "CanTpFcFrameId" HEX 0 2147483647;
BA_DEF_ BO_  "CanTpBs" INT 0 255;
BA_DEF_ SG_  "SystemSignalLongSymbol" STRING ;
BA_DEF_REL_ BU_SG_REL_  "GenSigTimeoutTime" INT 0 65535;
BA_DEF_REL_ BU_SG_REL_  "GenSigFirstTimeoutTime" INT 0 65535;
BA_DEF_DEF_  "GenMsgStartDelayTime" 0;
BA_DEF_DEF_  "GenMsgDelayTime" 0;
BA_DEF_DEF_  "GenMsgCycleTime" 0;
BA_DEF_DEF_  "GenMsgSendType" "Cyclic";
BA_DEF_DEF_  "GenSigStartValue" 0;
BA_DEF_DEF_  "GenSigCycleTimeActive" 0;
BA_DEF_DEF_  "GenSigCycleTime" 0;
BA_DEF_DEF_  "GenSigSendType" "Cyclic";
BA_DEF_DEF_  "VFrameFormat" "ExtendedCAN";
BA_DEF_DEF_  "SigType" "Default";
BA_DEF_DEF_  "SeToolVersion_SIGNAL" "";
BA_DEF_DEF_  "SeToolUniqueID_SIGNAL" "";
BA_DEF_DEF_  "SeToolOwnerSigGroup_SIGNAL" "";
BA_DEF_DEF_  "SeToolOwnerSigGroupID_SIGNAL" "";
BA_DEF_DEF_  "SeToolName_SIGNAL" "";
BA_DEF_DEF_  "SeToolItemID_SIGNAL" "";
BA_DEF_DEF_  "SeToolAncestorID_SIGNAL" "";
BA_DEF_DEF_  "Platform_VMCU1_Sig" "No";
BA_DEF_DEF_  "NmAsrMessage" "No";
BA_DEF_DEF_  "NeedsUpdateBit" "No";
BA_DEF_DEF_  "MmAnSignal" "No";
BA_DEF_DEF_  "GenSigMaxLatency" 0;
BA_DEF_DEF_  "GenSigILSupport" "Yes";
BA_DEF_DEF_  "GenMsgRequestable" 1;
BA_DEF_DEF_  "GenMsgILSupport" "Yes";
BA_DEF_DEF_  "DiagUUDTResponse" "No";
BA_DEF_DEF_  "DiagState" "No";
BA_DEF_DEF_  "DiagResponse" "No";
BA_DEF_DEF_  "DiagRequest" "No";
BA_DEF_DEF_  "DiagConnection" 0;
BA_DEF_DEF_  "CanTpSTmin" 0;
BA_DEF_DEF_  "CanTpFcFrameId" 2147483647;
BA_DEF_DEF_  "CanTpBs" 255;
BA_DEF_DEF_REL_ "GenSigTimeoutTime" 0;
BA_DEF_DEF_REL_ "GenSigFirstTimeoutTime" 0;
BA_DEF_DEF_  "SystemSignalLongSymbol" "";
BA_ "GenMsgSendType" BO_ 2147485152 8;
BA_ "GenMsgDelayTime" BO_ 2147485152 75;
BA_ "GenMsgSendType" BO_ 2147485137 8;
BA_ "GenMsgDelayTime" BO_ 2147485137 75;
BA_ "GenMsgSendType" BO_ 2147485567 8;
BA_ "GenMsgDelayTime" BO_ 2147485567 15;
BA_ "GenMsgStartDelayTime" BO_ 2147485567 50;
BA_ "GenMsgSendType" BO_ 2147485620 8;
BA_ "GenMsgDelayTime" BO_ 2147485620 20;
BA_ "GenMsgStartDelayTime" BO_ 2147485620 50;
BA_ "GenMsgSendType" BO_ 2147485566 8;
BA_ "GenMsgDelayTime" BO_ 2147485566 15;
BA_ "GenMsgStartDelayTime" BO_ 2147485566 50;
BA_ "GenMsgSendType" BO_ 2147485619 8;
BA_ "GenMsgDelayTime" BO_ 2147485619 20;
BA_ "GenMsgStartDelayTime" BO_ 2147485619 50;
BA_ "GenMsgSendType" BO_ 2147485565 8;
BA_ "GenMsgDelayTime" BO_ 2147485565 15;
BA_ "GenMsgStartDelayTime" BO_ 2147485565 50;
BA_ "GenMsgSendType" BO_ 2147485617 8;
BA_ "GenMsgDelayTime" BO_ 2147485617 20;
BA_ "GenMsgStartDelayTime" BO_ 2147485617 50;
BA_ "GenMsgSendType" BO_ 2147485618 8;
BA_ "GenMsgDelayTime" BO_ 2147485618 50;
BA_ "GenMsgSendType" BO_ 2147485611 8;
BA_ "GenMsgDelayTime" BO_ 2147485611 40;
BA_ "GenMsgStartDelayTime" BO_ 2147485611 50;
BA_ "GenMsgSendType" BO_ 2147485564 8;
BA_ "GenMsgDelayTime" BO_ 2147485564 15;
BA_ "GenMsgStartDelayTime" BO_ 2147485564 50;
BA_ "GenMsgSendType" BO_ 2147485614 8;
BA_ "GenMsgDelayTime" BO_ 2147485614 40;
BA_ "GenMsgStartDelayTime" BO_ 2147485614 50;
BA_ "GenMsgSendType" BO_ 2147485609 8;
BA_ "GenMsgDelayTime" BO_ 2147485609 40;
BA_ "GenMsgStartDelayTime" BO_ 2147485609 50;
BA_ "GenMsgSendType" BO_ 2147485613 8;
BA_ "GenMsgDelayTime" BO_ 2147485613 20;
BA_ "GenMsgStartDelayTime" BO_ 2147485613 50;
BA_ "GenMsgCycleTime" BO_ 1964 20;
BA_ "VFrameFormat" BO_ 1964 0;
BA_ "GenMsgDelayTime" BO_ 1964 50;
BA_ "GenMsgStartDelayTime" BO_ 1964 50;
BA_ "GenMsgSendType" BO_ 2147485615 8;
BA_ "GenMsgDelayTime" BO_ 2147485615 50;
BA_ "GenMsgStartDelayTime" BO_ 2147485615 50;
BA_ "GenMsgSendType" BO_ 2147485604 8;
BA_ "GenMsgDelayTime" BO_ 2147485604 40;
BA_ "GenMsgStartDelayTime" BO_ 2147485604 50;
BA_ "GenMsgSendType" BO_ 2147485563 8;
BA_ "GenMsgDelayTime" BO_ 2147485563 15;
BA_ "GenMsgStartDelayTime" BO_ 2147485563 50;
BA_ "GenMsgSendType" BO_ 2147485607 8;
BA_ "GenMsgDelayTime" BO_ 2147485607 40;
BA_ "GenMsgStartDelayTime" BO_ 2147485607 50;
BA_ "GenMsgSendType" BO_ 2147485602 8;
BA_ "GenMsgDelayTime" BO_ 2147485602 40;
BA_ "GenMsgStartDelayTime" BO_ 2147485602 50;
BA_ "GenMsgSendType" BO_ 2147485606 8;
BA_ "GenMsgDelayTime" BO_ 2147485606 20;
BA_ "GenMsgStartDelayTime" BO_ 2147485606 50;
BA_ "GenMsgCycleTime" BO_ 1957 20;
BA_ "VFrameFormat" BO_ 1957 0;
BA_ "GenMsgDelayTime" BO_ 1957 50;
BA_ "GenMsgStartDelayTime" BO_ 1957 50;
BA_ "GenMsgSendType" BO_ 2147485608 8;
BA_ "GenMsgDelayTime" BO_ 2147485608 50;
BA_ "GenMsgStartDelayTime" BO_ 2147485608 50;
BA_ "GenMsgSendType" BO_ 2147485597 8;
BA_ "GenMsgDelayTime" BO_ 2147485597 40;
BA_ "GenMsgStartDelayTime" BO_ 2147485597 50;
BA_ "GenMsgSendType" BO_ 2147485562 8;
BA_ "GenMsgDelayTime" BO_ 2147485562 15;
BA_ "GenMsgStartDelayTime" BO_ 2147485562 50;
BA_ "GenMsgSendType" BO_ 2147485600 8;
BA_ "GenMsgDelayTime" BO_ 2147485600 40;
BA_ "GenMsgStartDelayTime" BO_ 2147485600 50;
BA_ "GenMsgSendType" BO_ 2147485595 8;
BA_ "GenMsgDelayTime" BO_ 2147485595 40;
BA_ "GenMsgStartDelayTime" BO_ 2147485595 50;
BA_ "GenMsgSendType" BO_ 2147485599 8;
BA_ "GenMsgDelayTime" BO_ 2147485599 20;
BA_ "GenMsgStartDelayTime" BO_ 2147485599 50;
BA_ "GenMsgCycleTime" BO_ 1950 20;
BA_ "VFrameFormat" BO_ 1950 0;
BA_ "GenMsgDelayTime" BO_ 1950 50;
BA_ "GenMsgStartDelayTime" BO_ 1950 50;
BA_ "GenMsgSendType" BO_ 2147485601 8;
BA_ "GenMsgDelayTime" BO_ 2147485601 50;
BA_ "GenMsgStartDelayTime" BO_ 2147485601 50;
BA_ "GenMsgSendType" BO_ 2147485590 8;
BA_ "GenMsgDelayTime" BO_ 2147485590 40;
BA_ "GenMsgStartDelayTime" BO_ 2147485590 50;
BA_ "GenMsgSendType" BO_ 2147485545 8;
BA_ "GenMsgDelayTime" BO_ 2147485545 15;
BA_ "GenMsgStartDelayTime" BO_ 2147485545 50;
BA_ "GenMsgSendType" BO_ 2147485593 8;
BA_ "GenMsgDelayTime" BO_ 2147485593 40;
BA_ "GenMsgStartDelayTime" BO_ 2147485593 50;
BA_ "GenMsgSendType" BO_ 2147485588 8;
BA_ "GenMsgDelayTime" BO_ 2147485588 50;
BA_ "GenMsgStartDelayTime" BO_ 2147485588 50;
BA_ "GenMsgSendType" BO_ 2147485592 8;
BA_ "GenMsgDelayTime" BO_ 2147485592 10;
BA_ "GenMsgCycleTime" BO_ 1943 20;
BA_ "VFrameFormat" BO_ 1943 0;
BA_ "GenMsgDelayTime" BO_ 1943 50;
BA_ "GenMsgStartDelayTime" BO_ 1943 50;
BA_ "GenMsgSendType" BO_ 2147485594 8;
BA_ "GenMsgDelayTime" BO_ 2147485594 50;
BA_ "GenMsgStartDelayTime" BO_ 2147485594 50;
BA_ "GenMsgSendType" BO_ 2147485583 8;
BA_ "GenMsgDelayTime" BO_ 2147485583 40;
BA_ "GenMsgStartDelayTime" BO_ 2147485583 50;
BA_ "GenMsgSendType" BO_ 2147485544 8;
BA_ "GenMsgDelayTime" BO_ 2147485544 15;
BA_ "GenMsgStartDelayTime" BO_ 2147485544 50;
BA_ "GenMsgSendType" BO_ 2147485586 8;
BA_ "GenMsgDelayTime" BO_ 2147485586 40;
BA_ "GenMsgStartDelayTime" BO_ 2147485586 50;
BA_ "GenMsgSendType" BO_ 2147485581 8;
BA_ "GenMsgDelayTime" BO_ 2147485581 50;
BA_ "GenMsgStartDelayTime" BO_ 2147485581 50;
BA_ "GenMsgSendType" BO_ 2147485585 8;
BA_ "GenMsgDelayTime" BO_ 2147485585 10;
BA_ "GenMsgCycleTime" BO_ 1936 20;
BA_ "VFrameFormat" BO_ 1936 0;
BA_ "GenMsgDelayTime" BO_ 1936 50;
BA_ "GenMsgStartDelayTime" BO_ 1936 50;
BA_ "GenMsgSendType" BO_ 2147485587 8;
BA_ "GenMsgDelayTime" BO_ 2147485587 50;
BA_ "GenMsgStartDelayTime" BO_ 2147485587 50;
BA_ "GenMsgSendType" BO_ 2147485616 8;
BA_ "GenMsgDelayTime" BO_ 2147485616 15;
BA_ "GenMsgStartDelayTime" BO_ 2147485616 50;
BA_ "GenMsgSendType" BO_ 2147485610 8;
BA_ "GenMsgDelayTime" BO_ 2147485610 15;
BA_ "GenMsgStartDelayTime" BO_ 2147485610 50;
BA_ "VFrameFormat" BO_ 1929 0;
BA_ "GenMsgSendType" BO_ 2147485603 8;
BA_ "GenMsgDelayTime" BO_ 2147485603 4995;
BA_ "GenMsgStartDelayTime" BO_ 2147485603 50;
BA_ "GenMsgSendType" BO_ 2147485596 8;
BA_ "GenMsgDelayTime" BO_ 2147485596 995;
BA_ "GenMsgStartDelayTime" BO_ 2147485596 50;
BA_ "GenMsgSendType" BO_ 2147485589 8;
BA_ "GenMsgDelayTime" BO_ 2147485589 195;
BA_ "GenMsgStartDelayTime" BO_ 2147485589 50;
BA_ "GenMsgSendType" BO_ 2147485582 8;
BA_ "GenMsgDelayTime" BO_ 2147485582 195;
BA_ "GenMsgStartDelayTime" BO_ 2147485582 50;
BA_ "GenMsgSendType" BO_ 2147485573 8;
BA_ "GenMsgDelayTime" BO_ 2147485573 195;
BA_ "GenMsgStartDelayTime" BO_ 2147485573 50;
BA_ "GenMsgSendType" BO_ 2147485572 8;
BA_ "GenMsgDelayTime" BO_ 2147485572 195;
BA_ "GenMsgStartDelayTime" BO_ 2147485572 50;
BA_ "GenMsgSendType" BO_ 2147485571 8;
BA_ "GenMsgDelayTime" BO_ 2147485571 195;
BA_ "GenMsgStartDelayTime" BO_ 2147485571 50;
BA_ "GenMsgSendType" BO_ 2147485570 8;
BA_ "GenMsgDelayTime" BO_ 2147485570 195;
BA_ "GenMsgStartDelayTime" BO_ 2147485570 50;
BA_ "GenMsgSendType" BO_ 2147485569 8;
BA_ "GenMsgDelayTime" BO_ 2147485569 195;
BA_ "GenMsgStartDelayTime" BO_ 2147485569 50;
BA_ "GenMsgSendType" BO_ 2147485622 8;
BA_ "GenMsgDelayTime" BO_ 2147485622 20;
BA_ "GenMsgStartDelayTime" BO_ 2147485622 50;
BA_ "GenMsgSendType" BO_ 2634017304 8;
BA_ "GenMsgDelayTime" BO_ 2634017304 15;
BA_ "GenMsgStartDelayTime" BO_ 2634017304 50;
BA_ "GenMsgSendType" BO_ 2634021456 8;
BA_ "GenMsgDelayTime" BO_ 2634021456 20;
BA_ "GenMsgStartDelayTime" BO_ 2634021456 50;
BA_ "VFrameFormat" BO_ 1338 0;
BA_ "GenMsgCycleTime" BO_ 1338 500;
BA_ "GenMsgStartDelayTime" BO_ 1338 35;
BA_ "GenMsgCycleTime" BO_ 2432641616 20;
BA_ "GenMsgStartDelayTime" BO_ 2432641616 5;
BA_ "GenMsgCycleTime" BO_ 2432640336 20;
BA_ "GenMsgStartDelayTime" BO_ 2432640336 10;
BA_ "GenMsgCycleTime" BO_ 2432639568 20;
BA_ "GenMsgStartDelayTime" BO_ 2432639568 10;
BA_ "GenMsgCycleTime" BO_ 2499772240 100;
BA_ "GenMsgStartDelayTime" BO_ 2499772240 15;
BA_ "GenMsgCycleTime" BO_ 2466246992 40;
BA_ "GenMsgStartDelayTime" BO_ 2466246992 5;
BA_ "GenMsgCycleTime" BO_ 2432690512 20;
BA_ "GenMsgILSupport" BO_ 936 0;
BA_ "VFrameFormat" BO_ 936 0;
BA_ "GenMsgSendType" BO_ 936 8;
BA_ "CanTpFcFrameId" BO_ 935 936;
BA_ "VFrameFormat" BO_ 935 0;
BA_ "GenMsgSendType" BO_ 935 8;
BA_ "GenMsgDelayTime" BO_ 935 20;
BA_ "VFrameFormat" BO_ 1369 0;
BA_ "GenMsgSendType" BO_ 1369 8;
BA_ "GenMsgDelayTime" BO_ 1369 20;
BA_ "GenMsgStartDelayTime" BO_ 1369 20;
BA_ "VFrameFormat" BO_ 551 0;
BA_ "GenMsgCycleTime" BO_ 551 40;
BA_ "GenMsgStartDelayTime" BO_ 551 30;
BA_ "GenMsgCycleTime" BO_ 2432685120 40;
BA_ "GenMsgStartDelayTime" BO_ 2432685120 10;
BA_ "GenMsgCycleTime" BO_ 2566078272 100;
BA_ "GenMsgStartDelayTime" BO_ 2566078272 50;
BA_ "GenMsgSendType" BO_ 2490646336 8;
BA_ "GenMsgDelayTime" BO_ 2490646336 50;
BA_ "GenMsgSendType" BO_ 2499780850 8;
BA_ "GenMsgDelayTime" BO_ 2499780850 75;
BA_ "GenMsgCycleTime" BO_ 2482978624 50;
BA_ "GenMsgStartDelayTime" BO_ 2482978624 50;
BA_ "GenMsgSendType" BO_ 2516513011 8;
BA_ "GenMsgDelayTime" BO_ 2516513011 100;
BA_ "GenMsgStartDelayTime" BO_ 2516513011 15;
BA_ "GenMsgSendType" BO_ 2499801330 8;
BA_ "GenMsgDelayTime" BO_ 2499801330 75;
BA_ "GenMsgILSupport" BO_ 2499764033 0;
BA_ "GenMsgSendType" BO_ 2499764033 8;
BA_ "CanTpFcFrameId" BO_ 2499764032 943;
BA_ "GenMsgSendType" BO_ 2499764032 8;
BA_ "GenMsgDelayTime" BO_ 2499764032 20;
BA_ "GenMsgILSupport" BO_ 2499747649 0;
BA_ "GenMsgSendType" BO_ 2499747649 8;
BA_ "CanTpFcFrameId" BO_ 2499747648 937;
BA_ "GenMsgSendType" BO_ 2499747648 8;
BA_ "GenMsgDelayTime" BO_ 2499747648 20;
BA_ "GenMsgCycleTime" BO_ 2498741568 95;
BA_ "GenMsgStartDelayTime" BO_ 2498741568 40;
BA_ "GenMsgCycleTime" BO_ 2483023936 55;
BA_ "GenMsgStartDelayTime" BO_ 2483023936 10;
BA_ "GenMsgCycleTime" BO_ 2515579712 100;
BA_ "GenMsgStartDelayTime" BO_ 2515579712 15;
BA_ "GenMsgCycleTime" BO_ 2482995008 50;
BA_ "GenMsgStartDelayTime" BO_ 2482995008 25;
BA_ "GenSigSendType" SG_ 2147485152 DiagFaultStat_Alarm_DtcIdA_ISig_ 1;
BA_ "NeedsUpdateBit" SG_ 2147485152 DiagFaultStat_Alarm_DtcIdA_ISig_ 1;
BA_ "Platform_VMCU1_Sig" SG_ 2147485152 DiagFaultStat_Alarm_DtcIdA_ISig_ 1;
BA_ "SystemSignalLongSymbol" SG_ 2147485152 DiagFaultStat_Alarm_DtcIdA_ISig_ "DiagFaultStat_Alarm_DtcIdA_ISig_4";
BA_ "GenSigSendType" SG_ 2147485152 DiagFaultStat_Alarm_EcuAdr_ISig_ 1;
BA_ "GenSigStartValue" SG_ 2147485152 DiagFaultStat_Alarm_EcuAdr_ISig_ 255;
BA_ "NeedsUpdateBit" SG_ 2147485152 DiagFaultStat_Alarm_EcuAdr_ISig_ 1;
BA_ "Platform_VMCU1_Sig" SG_ 2147485152 DiagFaultStat_Alarm_EcuAdr_ISig_ 1;
BA_ "SystemSignalLongSymbol" SG_ 2147485152 DiagFaultStat_Alarm_EcuAdr_ISig_ "DiagFaultStat_Alarm_EcuAdr_ISig_4";
BA_ "GenSigSendType" SG_ 2147485152 DiagFaultStat_Alarm_sg_UB_ISig_4 7;
BA_ "Platform_VMCU1_Sig" SG_ 2147485152 DiagFaultStat_Alarm_sg_UB_ISig_4 1;
BA_ "GenSigSendType" SG_ 2147485152 DiagFaultStat_Alarm_FailTB_ISig_ 1;
BA_ "NeedsUpdateBit" SG_ 2147485152 DiagFaultStat_Alarm_FailTB_ISig_ 1;
BA_ "Platform_VMCU1_Sig" SG_ 2147485152 DiagFaultStat_Alarm_FailTB_ISig_ 1;
BA_ "SystemSignalLongSymbol" SG_ 2147485152 DiagFaultStat_Alarm_FailTB_ISig_ "DiagFaultStat_Alarm_FailTB_ISig_4";
BA_ "GenSigSendType" SG_ 2147485152 DiagFaultStat_Alarm_FailTA_ISig_ 1;
BA_ "NeedsUpdateBit" SG_ 2147485152 DiagFaultStat_Alarm_FailTA_ISig_ 1;
BA_ "Platform_VMCU1_Sig" SG_ 2147485152 DiagFaultStat_Alarm_FailTA_ISig_ 1;
BA_ "SystemSignalLongSymbol" SG_ 2147485152 DiagFaultStat_Alarm_FailTA_ISig_ "DiagFaultStat_Alarm_FailTA_ISig_4";
BA_ "GenSigSendType" SG_ 2147485152 DiagFaultStat_Alarm_DtcIdB_ISig_ 1;
BA_ "NeedsUpdateBit" SG_ 2147485152 DiagFaultStat_Alarm_DtcIdB_ISig_ 1;
BA_ "Platform_VMCU1_Sig" SG_ 2147485152 DiagFaultStat_Alarm_DtcIdB_ISig_ 1;
BA_ "SystemSignalLongSymbol" SG_ 2147485152 DiagFaultStat_Alarm_DtcIdB_ISig_ "DiagFaultStat_Alarm_DtcIdB_ISig_4";
BA_ "GenSigSendType" SG_ 2147485137 DiagFaultStat_APM_DtcIdA_ISig_4 1;
BA_ "NeedsUpdateBit" SG_ 2147485137 DiagFaultStat_APM_DtcIdA_ISig_4 1;
BA_ "Platform_VMCU1_Sig" SG_ 2147485137 DiagFaultStat_APM_DtcIdA_ISig_4 1;
BA_ "GenSigSendType" SG_ 2147485137 DiagFaultStat_APM_EcuAdr_ISig_4 1;
BA_ "GenSigStartValue" SG_ 2147485137 DiagFaultStat_APM_EcuAdr_ISig_4 255;
BA_ "NeedsUpdateBit" SG_ 2147485137 DiagFaultStat_APM_EcuAdr_ISig_4 1;
BA_ "Platform_VMCU1_Sig" SG_ 2147485137 DiagFaultStat_APM_EcuAdr_ISig_4 1;
BA_ "GenSigSendType" SG_ 2147485137 DiagFaultStat_APM_FailTB_ISig_4 1;
BA_ "NeedsUpdateBit" SG_ 2147485137 DiagFaultStat_APM_FailTB_ISig_4 1;
BA_ "Platform_VMCU1_Sig" SG_ 2147485137 DiagFaultStat_APM_FailTB_ISig_4 1;
BA_ "GenSigSendType" SG_ 2147485137 DiagFaultStat_APM_sg_UB_ISig_4 7;
BA_ "Platform_VMCU1_Sig" SG_ 2147485137 DiagFaultStat_APM_sg_UB_ISig_4 1;
BA_ "GenSigSendType" SG_ 2147485137 DiagFaultStat_APM_DtcIdB_ISig_4 1;
BA_ "NeedsUpdateBit" SG_ 2147485137 DiagFaultStat_APM_DtcIdB_ISig_4 1;
BA_ "Platform_VMCU1_Sig" SG_ 2147485137 DiagFaultStat_APM_DtcIdB_ISig_4 1;
BA_ "GenSigSendType" SG_ 2147485137 DiagFaultStat_APM_FailTA_ISig_4 1;
BA_ "NeedsUpdateBit" SG_ 2147485137 DiagFaultStat_APM_FailTA_ISig_4 1;
BA_ "Platform_VMCU1_Sig" SG_ 2147485137 DiagFaultStat_APM_FailTA_ISig_4 1;
BA_ "GenSigSendType" SG_ 2147485567 Debug_9_TECU 1;
BA_ "GenSigMaxLatency" SG_ 2147485567 Debug_9_TECU 55;
BA_ "Platform_VMCU1_Sig" SG_ 2147485567 Debug_9_TECU 1;
BA_ "GenSigSendType" SG_ 2147485620 Debug_9_DACU 1;
BA_ "GenSigMaxLatency" SG_ 2147485620 Debug_9_DACU 25;
BA_ "Platform_VMCU1_Sig" SG_ 2147485620 Debug_9_DACU 1;
BA_ "GenSigSendType" SG_ 2147485566 Debug_8_TECU 1;
BA_ "GenSigMaxLatency" SG_ 2147485566 Debug_8_TECU 55;
BA_ "Platform_VMCU1_Sig" SG_ 2147485566 Debug_8_TECU 1;
BA_ "GenSigSendType" SG_ 2147485619 Debug_8_DACU 1;
BA_ "GenSigMaxLatency" SG_ 2147485619 Debug_8_DACU 25;
BA_ "Platform_VMCU1_Sig" SG_ 2147485619 Debug_8_DACU 1;
BA_ "GenSigSendType" SG_ 2147485565 Debug_7_TECU 1;
BA_ "GenSigMaxLatency" SG_ 2147485565 Debug_7_TECU 55;
BA_ "Platform_VMCU1_Sig" SG_ 2147485565 Debug_7_TECU 1;
BA_ "GenSigSendType" SG_ 2147485617 Debug_7_DACU 1;
BA_ "GenSigMaxLatency" SG_ 2147485617 Debug_7_DACU 25;
BA_ "Platform_VMCU1_Sig" SG_ 2147485617 Debug_7_DACU 1;
BA_ "GenSigSendType" SG_ 2147485618 Debug_7_BBM 1;
BA_ "Platform_VMCU1_Sig" SG_ 2147485618 Debug_7_BBM 1;
BA_ "GenSigSendType" SG_ 2147485611 Debug_6_VMCU 1;
BA_ "GenSigMaxLatency" SG_ 2147485611 Debug_6_VMCU 55;
BA_ "Platform_VMCU1_Sig" SG_ 2147485611 Debug_6_VMCU 1;
BA_ "GenSigSendType" SG_ 2147485564 Debug_6_TECU 1;
BA_ "GenSigMaxLatency" SG_ 2147485564 Debug_6_TECU 55;
BA_ "Platform_VMCU1_Sig" SG_ 2147485564 Debug_6_TECU 1;
BA_ "GenSigSendType" SG_ 2147485614 Debug_6_HMIIOM 1;
BA_ "GenSigMaxLatency" SG_ 2147485614 Debug_6_HMIIOM 55;
BA_ "Platform_VMCU1_Sig" SG_ 2147485614 Debug_6_HMIIOM 1;
BA_ "GenSigSendType" SG_ 2147485609 Debug_6_EMS 1;
BA_ "GenSigMaxLatency" SG_ 2147485609 Debug_6_EMS 55;
BA_ "Platform_VMCU1_Sig" SG_ 2147485609 Debug_6_EMS 1;
BA_ "GenSigSendType" SG_ 2147485613 Debug_6_DACU 1;
BA_ "GenSigMaxLatency" SG_ 2147485613 Debug_6_DACU 25;
BA_ "Platform_VMCU1_Sig" SG_ 2147485613 Debug_6_DACU 1;
BA_ "GenSigCycleTimeActive" SG_ 1964 Debug_PVT_SCIM_Task7_Time 100;
BA_ "GenSigCycleTime" SG_ 1964 Debug_PVT_SCIM_Task7_Time 100;
BA_ "GenSigCycleTimeActive" SG_ 1964 Debug_PVT_SCIM_Task6_Time 100;
BA_ "GenSigCycleTime" SG_ 1964 Debug_PVT_SCIM_Task6_Time 100;
BA_ "GenSigCycleTimeActive" SG_ 1964 Debug_PVT_SCIM_Task5_Time 100;
BA_ "GenSigCycleTime" SG_ 1964 Debug_PVT_SCIM_Task5_Time 100;
BA_ "GenSigCycleTimeActive" SG_ 1964 Debug_PVT_SCIM_Task4_Time 100;
BA_ "GenSigCycleTime" SG_ 1964 Debug_PVT_SCIM_Task4_Time 100;
BA_ "GenSigCycleTimeActive" SG_ 1964 Debug_PVT_SCIM_Task3_Time 100;
BA_ "GenSigCycleTime" SG_ 1964 Debug_PVT_SCIM_Task3_Time 100;
BA_ "GenSigCycleTimeActive" SG_ 1964 Debug_PVT_SCIM_Task2_Time 100;
BA_ "GenSigCycleTime" SG_ 1964 Debug_PVT_SCIM_Task2_Time 100;
BA_ "GenSigCycleTimeActive" SG_ 1964 Debug_PVT_SCIM_Task1_Time 100;
BA_ "GenSigCycleTime" SG_ 1964 Debug_PVT_SCIM_Task1_Time 100;
BA_ "GenSigSendType" SG_ 2147485615 Debug_6_BBM 1;
BA_ "GenSigMaxLatency" SG_ 2147485615 Debug_6_BBM 59;
BA_ "Platform_VMCU1_Sig" SG_ 2147485615 Debug_6_BBM 1;
BA_ "GenSigSendType" SG_ 2147485604 Debug_5_VMCU 1;
BA_ "GenSigMaxLatency" SG_ 2147485604 Debug_5_VMCU 55;
BA_ "Platform_VMCU1_Sig" SG_ 2147485604 Debug_5_VMCU 1;
BA_ "GenSigSendType" SG_ 2147485563 Debug_5_TECU 1;
BA_ "GenSigMaxLatency" SG_ 2147485563 Debug_5_TECU 55;
BA_ "Platform_VMCU1_Sig" SG_ 2147485563 Debug_5_TECU 1;
BA_ "GenSigSendType" SG_ 2147485607 Debug_5_HMIIOM 1;
BA_ "GenSigMaxLatency" SG_ 2147485607 Debug_5_HMIIOM 55;
BA_ "Platform_VMCU1_Sig" SG_ 2147485607 Debug_5_HMIIOM 1;
BA_ "GenSigSendType" SG_ 2147485602 Debug_5_EMS 1;
BA_ "GenSigMaxLatency" SG_ 2147485602 Debug_5_EMS 55;
BA_ "Platform_VMCU1_Sig" SG_ 2147485602 Debug_5_EMS 1;
BA_ "GenSigSendType" SG_ 2147485606 Debug_5_DACU 1;
BA_ "GenSigMaxLatency" SG_ 2147485606 Debug_5_DACU 25;
BA_ "Platform_VMCU1_Sig" SG_ 2147485606 Debug_5_DACU 1;
BA_ "GenSigCycleTimeActive" SG_ 1957 Debug_PVT_SCIM_TSinceWkUp_Short 100;
BA_ "GenSigCycleTime" SG_ 1957 Debug_PVT_SCIM_TSinceWkUp_Short 100;
BA_ "GenSigCycleTimeActive" SG_ 1957 Debug_PVT_SCIM_TSincePwrOn_Short 100;
BA_ "GenSigCycleTime" SG_ 1957 Debug_PVT_SCIM_TSincePwrOn_Short 100;
BA_ "GenSigCycleTimeActive" SG_ 1957 Debug_PVT_SCIM_TSincePwrOn_Long 100;
BA_ "GenSigCycleTime" SG_ 1957 Debug_PVT_SCIM_TSincePwrOn_Long 100;
BA_ "GenSigSendType" SG_ 2147485608 Debug_5_BBM 1;
BA_ "GenSigMaxLatency" SG_ 2147485608 Debug_5_BBM 59;
BA_ "Platform_VMCU1_Sig" SG_ 2147485608 Debug_5_BBM 1;
BA_ "GenSigSendType" SG_ 2147485597 Debug_4_VMCU 1;
BA_ "GenSigMaxLatency" SG_ 2147485597 Debug_4_VMCU 55;
BA_ "Platform_VMCU1_Sig" SG_ 2147485597 Debug_4_VMCU 1;
BA_ "GenSigSendType" SG_ 2147485562 Debug_4_TECU 1;
BA_ "GenSigMaxLatency" SG_ 2147485562 Debug_4_TECU 55;
BA_ "Platform_VMCU1_Sig" SG_ 2147485562 Debug_4_TECU 1;
BA_ "GenSigSendType" SG_ 2147485600 Debug_4_HMIIOM 1;
BA_ "GenSigMaxLatency" SG_ 2147485600 Debug_4_HMIIOM 55;
BA_ "Platform_VMCU1_Sig" SG_ 2147485600 Debug_4_HMIIOM 1;
BA_ "GenSigSendType" SG_ 2147485595 Debug_4_EMS 1;
BA_ "GenSigMaxLatency" SG_ 2147485595 Debug_4_EMS 55;
BA_ "Platform_VMCU1_Sig" SG_ 2147485595 Debug_4_EMS 1;
BA_ "GenSigSendType" SG_ 2147485599 Debug_4_DACU 1;
BA_ "GenSigMaxLatency" SG_ 2147485599 Debug_4_DACU 25;
BA_ "Platform_VMCU1_Sig" SG_ 2147485599 Debug_4_DACU 1;
BA_ "GenSigCycleTimeActive" SG_ 1950 Debug_PVT_SCIM_RF_Button2_Time 100;
BA_ "GenSigCycleTime" SG_ 1950 Debug_PVT_SCIM_RF_Button2_Time 100;
BA_ "GenSigCycleTimeActive" SG_ 1950 Debug_PVT_SCIM_RF_Button2_ID 100;
BA_ "GenSigCycleTime" SG_ 1950 Debug_PVT_SCIM_RF_Button2_ID 100;
BA_ "GenSigCycleTimeActive" SG_ 1950 Debug_PVT_SCIM_RF_Button1_Time 100;
BA_ "GenSigCycleTime" SG_ 1950 Debug_PVT_SCIM_RF_Button1_Time 100;
BA_ "GenSigCycleTimeActive" SG_ 1950 Debug_PVT_SCIM_RF_Button1_ID 100;
BA_ "GenSigCycleTime" SG_ 1950 Debug_PVT_SCIM_RF_Button1_ID 100;
BA_ "GenSigCycleTimeActive" SG_ 1950 Debug_PVT_SCIM_RF_BtnPressIndex 100;
BA_ "GenSigCycleTime" SG_ 1950 Debug_PVT_SCIM_RF_BtnPressIndex 100;
BA_ "GenSigCycleTimeActive" SG_ 1950 Debug_PVT_SCIM_RF_BAT 100;
BA_ "GenSigCycleTime" SG_ 1950 Debug_PVT_SCIM_RF_BAT 100;
BA_ "GenSigSendType" SG_ 2147485601 Debug_4_BBM 1;
BA_ "GenSigMaxLatency" SG_ 2147485601 Debug_4_BBM 59;
BA_ "Platform_VMCU1_Sig" SG_ 2147485601 Debug_4_BBM 1;
BA_ "GenSigSendType" SG_ 2147485590 Debug_3_VMCU 1;
BA_ "GenSigMaxLatency" SG_ 2147485590 Debug_3_VMCU 55;
BA_ "Platform_VMCU1_Sig" SG_ 2147485590 Debug_3_VMCU 1;
BA_ "GenSigSendType" SG_ 2147485545 Debug_3_TECU 1;
BA_ "GenSigMaxLatency" SG_ 2147485545 Debug_3_TECU 55;
BA_ "Platform_VMCU1_Sig" SG_ 2147485545 Debug_3_TECU 1;
BA_ "GenSigSendType" SG_ 2147485593 Debug_3_HMIIOM 1;
BA_ "GenSigMaxLatency" SG_ 2147485593 Debug_3_HMIIOM 55;
BA_ "Platform_VMCU1_Sig" SG_ 2147485593 Debug_3_HMIIOM 1;
BA_ "GenSigSendType" SG_ 2147485588 Debug_3_EMS 1;
BA_ "GenSigMaxLatency" SG_ 2147485588 Debug_3_EMS 55;
BA_ "Platform_VMCU1_Sig" SG_ 2147485588 Debug_3_EMS 1;
BA_ "GenSigSendType" SG_ 2147485592 Debug_3_DACU 1;
BA_ "GenSigMaxLatency" SG_ 2147485592 Debug_3_DACU 25;
BA_ "Platform_VMCU1_Sig" SG_ 2147485592 Debug_3_DACU 1;
BA_ "GenSigCycleTime" SG_ 1943 Debug_PVT_SCIM_RD_BHS4_Volt 100;
BA_ "GenSigCycleTimeActive" SG_ 1943 Debug_PVT_SCIM_RD_BHS4_Volt 100;
BA_ "GenSigCycleTime" SG_ 1943 Debug_PVT_SCIM_RD_BHS4_Fault 100;
BA_ "GenSigCycleTimeActive" SG_ 1943 Debug_PVT_SCIM_RD_BHS4_Fault 100;
BA_ "GenSigCycleTime" SG_ 1943 Debug_PVT_SCIM_RD_BHS3_Volt 100;
BA_ "GenSigCycleTimeActive" SG_ 1943 Debug_PVT_SCIM_RD_BHS3_Volt 100;
BA_ "GenSigCycleTime" SG_ 1943 Debug_PVT_SCIM_RD_BHS3_Fault 100;
BA_ "GenSigCycleTimeActive" SG_ 1943 Debug_PVT_SCIM_RD_BHS3_Fault 100;
BA_ "GenSigCycleTime" SG_ 1943 Debug_PVT_SCIM_RD_BHS2_Volt 100;
BA_ "GenSigCycleTimeActive" SG_ 1943 Debug_PVT_SCIM_RD_BHS2_Volt 100;
BA_ "GenSigCycleTime" SG_ 1943 Debug_PVT_SCIM_RD_BHS2_Fault 100;
BA_ "GenSigCycleTimeActive" SG_ 1943 Debug_PVT_SCIM_RD_BHS2_Fault 100;
BA_ "GenSigCycleTime" SG_ 1943 Debug_PVT_SCIM_RD_BHS1_Volt 100;
BA_ "GenSigCycleTimeActive" SG_ 1943 Debug_PVT_SCIM_RD_BHS1_Volt 100;
BA_ "GenSigCycleTime" SG_ 1943 Debug_PVT_SCIM_RD_BHS1_Fault 100;
BA_ "GenSigCycleTimeActive" SG_ 1943 Debug_PVT_SCIM_RD_BHS1_Fault 100;
BA_ "GenSigSendType" SG_ 2147485594 Debug_3_BBM 1;
BA_ "GenSigMaxLatency" SG_ 2147485594 Debug_3_BBM 59;
BA_ "Platform_VMCU1_Sig" SG_ 2147485594 Debug_3_BBM 1;
BA_ "GenSigSendType" SG_ 2147485583 Debug_2_VMCU 1;
BA_ "GenSigMaxLatency" SG_ 2147485583 Debug_2_VMCU 55;
BA_ "Platform_VMCU1_Sig" SG_ 2147485583 Debug_2_VMCU 1;
BA_ "GenSigSendType" SG_ 2147485544 Debug_2_TECU 1;
BA_ "GenSigMaxLatency" SG_ 2147485544 Debug_2_TECU 55;
BA_ "Platform_VMCU1_Sig" SG_ 2147485544 Debug_2_TECU 1;
BA_ "GenSigSendType" SG_ 2147485586 Debug_2_HMIIOM 1;
BA_ "GenSigMaxLatency" SG_ 2147485586 Debug_2_HMIIOM 55;
BA_ "Platform_VMCU1_Sig" SG_ 2147485586 Debug_2_HMIIOM 1;
BA_ "GenSigSendType" SG_ 2147485581 Debug_2_EMS 1;
BA_ "GenSigMaxLatency" SG_ 2147485581 Debug_2_EMS 55;
BA_ "Platform_VMCU1_Sig" SG_ 2147485581 Debug_2_EMS 1;
BA_ "GenSigSendType" SG_ 2147485585 Debug_2_DACU 1;
BA_ "GenSigMaxLatency" SG_ 2147485585 Debug_2_DACU 25;
BA_ "Platform_VMCU1_Sig" SG_ 2147485585 Debug_2_DACU 1;
BA_ "GenSigCycleTime" SG_ 1936 Debug_PVT_SCIM_RD_VBAT_Fault 100;
BA_ "GenSigCycleTimeActive" SG_ 1936 Debug_PVT_SCIM_RD_VBAT_Fault 100;
BA_ "GenSigCycleTimeActive" SG_ 1936 Debug_PVT_SCIM_RD_12VParkedFault 100;
BA_ "GenSigCycleTime" SG_ 1936 Debug_PVT_SCIM_RD_12VParkedFault 100;
BA_ "GenSigCycleTimeActive" SG_ 1936 Debug_PVT_SCIM_RD_12VLivingFault 100;
BA_ "GenSigCycleTime" SG_ 1936 Debug_PVT_SCIM_RD_12VLivingFault 100;
BA_ "GenSigCycleTimeActive" SG_ 1936 Debug_PVT_SCIM_RD_12VDCDCFault 100;
BA_ "GenSigCycleTime" SG_ 1936 Debug_PVT_SCIM_RD_12VDCDCFault 100;
BA_ "GenSigCycleTime" SG_ 1936 Debug_PVT_SCIM_RD_VBAT 100;
BA_ "GenSigCycleTimeActive" SG_ 1936 Debug_PVT_SCIM_RD_VBAT 100;
BA_ "GenSigCycleTimeActive" SG_ 1936 Debug_PVT_SCIM_RD_12VParkedVolt 100;
BA_ "GenSigCycleTime" SG_ 1936 Debug_PVT_SCIM_RD_12VParkedVolt 100;
BA_ "GenSigCycleTimeActive" SG_ 1936 Debug_PVT_SCIM_RD_12VLivingVolt 100;
BA_ "GenSigCycleTime" SG_ 1936 Debug_PVT_SCIM_RD_12VLivingVolt 100;
BA_ "GenSigCycleTimeActive" SG_ 1936 Debug_PVT_SCIM_RD_12VDCDCVolt 100;
BA_ "GenSigCycleTime" SG_ 1936 Debug_PVT_SCIM_RD_12VDCDCVolt 100;
BA_ "GenSigSendType" SG_ 2147485587 Debug_2_BBM 1;
BA_ "GenSigMaxLatency" SG_ 2147485587 Debug_2_BBM 59;
BA_ "Platform_VMCU1_Sig" SG_ 2147485587 Debug_2_BBM 1;
BA_ "GenSigSendType" SG_ 2147485616 Debug_21_TECU 1;
BA_ "Platform_VMCU1_Sig" SG_ 2147485616 Debug_21_TECU 1;
BA_ "GenSigSendType" SG_ 2147485610 Debug_20_TECU 1;
BA_ "Platform_VMCU1_Sig" SG_ 2147485610 Debug_20_TECU 1;
BA_ "GenSigSendType" SG_ 2147485576 Debug_1_VMCU 1;
BA_ "Platform_VMCU1_Sig" SG_ 2147485576 Debug_1_VMCU 1;
BA_ "GenSigSendType" SG_ 2147485575 Debug_1_TECU 1;
BA_ "Platform_VMCU1_Sig" SG_ 2147485575 Debug_1_TECU 1;
BA_ "GenSigSendType" SG_ 2147485579 Debug_1_HMIIOM 1;
BA_ "Platform_VMCU1_Sig" SG_ 2147485579 Debug_1_HMIIOM 1;
BA_ "GenSigSendType" SG_ 2147485574 Debug_1_EMS 1;
BA_ "Platform_VMCU1_Sig" SG_ 2147485574 Debug_1_EMS 1;
BA_ "GenSigSendType" SG_ 2147485578 Debug_1_DACU 1;
BA_ "Platform_VMCU1_Sig" SG_ 2147485578 Debug_1_DACU 1;
BA_ "GenSigSendType" SG_ 1929 Debug_1_CIOM 1;
BA_ "Platform_VMCU1_Sig" SG_ 1929 Debug_1_CIOM 1;
BA_ "GenSigSendType" SG_ 2147485580 Debug_1_BBM 1;
BA_ "Platform_VMCU1_Sig" SG_ 2147485580 Debug_1_BBM 1;
BA_ "GenSigSendType" SG_ 2147485603 Debug_19_TECU 1;
BA_ "Platform_VMCU1_Sig" SG_ 2147485603 Debug_19_TECU 1;
BA_ "GenSigSendType" SG_ 2147485596 Debug_18_TECU 1;
BA_ "Platform_VMCU1_Sig" SG_ 2147485596 Debug_18_TECU 1;
BA_ "GenSigSendType" SG_ 2147485589 Debug_17_TECU 1;
BA_ "Platform_VMCU1_Sig" SG_ 2147485589 Debug_17_TECU 1;
BA_ "GenSigSendType" SG_ 2147485582 Debug_16_TECU 1;
BA_ "Platform_VMCU1_Sig" SG_ 2147485582 Debug_16_TECU 1;
BA_ "GenSigSendType" SG_ 2147485573 Debug_15_TECU 1;
BA_ "Platform_VMCU1_Sig" SG_ 2147485573 Debug_15_TECU 1;
BA_ "GenSigSendType" SG_ 2147485572 Debug_14_TECU 1;
BA_ "Platform_VMCU1_Sig" SG_ 2147485572 Debug_14_TECU 1;
BA_ "GenSigSendType" SG_ 2147485571 Debug_13_TECU 1;
BA_ "GenSigMaxLatency" SG_ 2147485571 Debug_13_TECU 55;
BA_ "Platform_VMCU1_Sig" SG_ 2147485571 Debug_13_TECU 1;
BA_ "GenSigSendType" SG_ 2147485570 Debug_12_TECU 1;
BA_ "GenSigMaxLatency" SG_ 2147485570 Debug_12_TECU 55;
BA_ "Platform_VMCU1_Sig" SG_ 2147485570 Debug_12_TECU 1;
BA_ "GenSigSendType" SG_ 2147485569 Debug_11_TECU 1;
BA_ "GenSigMaxLatency" SG_ 2147485569 Debug_11_TECU 55;
BA_ "Platform_VMCU1_Sig" SG_ 2147485569 Debug_11_TECU 1;
BA_ "GenSigSendType" SG_ 2147485622 Debug_11_DACU 1;
BA_ "GenSigCycleTime" SG_ 2147485622 Debug_11_DACU 100;
BA_ "GenSigCycleTimeActive" SG_ 2147485622 Debug_11_DACU 100;
BA_ "Platform_VMCU1_Sig" SG_ 2147485622 Debug_11_DACU 1;
BA_ "GenSigSendType" SG_ 2634017304 Debug_10_TECU 1;
BA_ "GenSigMaxLatency" SG_ 2634017304 Debug_10_TECU 55;
BA_ "Platform_VMCU1_Sig" SG_ 2634017304 Debug_10_TECU 1;
BA_ "GenSigSendType" SG_ 2634021456 Debug_10_DACU 1;
BA_ "GenSigMaxLatency" SG_ 2634021456 Debug_10_DACU 25;
BA_ "Platform_VMCU1_Sig" SG_ 2634021456 Debug_10_DACU 1;
BA_ "GenSigCycleTime" SG_ 1338 RoadSpeedRestriction 100;
BA_ "GenSigCycleTimeActive" SG_ 1338 RoadSpeedRestriction 100;
BA_ "GenSigStartValue" SG_ 1338 RoadSpeedRestriction 255;
BA_ "GenSigCycleTime" SG_ 1338 ObserveRoadRestriction_OpCap 100;
BA_ "GenSigCycleTimeActive" SG_ 1338 ObserveRoadRestriction_OpCap 100;
BA_ "GenSigStartValue" SG_ 1338 ObserveRoadRestriction_OpCap 3;
BA_ "GenSigCycleTime" SG_ 1338 RoadOvertakingRestriction 100;
BA_ "GenSigCycleTimeActive" SG_ 1338 RoadOvertakingRestriction 100;
BA_ "GenSigStartValue" SG_ 1338 RoadOvertakingRestriction 3;
BA_ "GenSigCycleTime" SG_ 1338 RoadTypeSpeedRestriction 100;
BA_ "GenSigCycleTimeActive" SG_ 1338 RoadTypeSpeedRestriction 100;
BA_ "GenSigStartValue" SG_ 1338 RoadTypeSpeedRestriction 7;
BA_ "GenSigCycleTime" SG_ 1338 ObserveRoadRestrictionStatus 100;
BA_ "GenSigCycleTimeActive" SG_ 1338 ObserveRoadRestrictionStatus 100;
BA_ "GenSigStartValue" SG_ 1338 ObserveRoadRestrictionStatus 3;
BA_ "GenSigCycleTime" SG_ 2432641616 FASHapticFeedbackRequest_ISig_4 100;
BA_ "GenSigCycleTimeActive" SG_ 2432641616 FASHapticFeedbackRequest_ISig_4 100;
BA_ "GenSigStartValue" SG_ 2432641616 FASHapticFeedbackRequest_ISig_4 15;
BA_ "GenSigMaxLatency" SG_ 2432641616 FASHapticFeedbackRequest_ISig_4 25;
BA_ "GenSigCycleTime" SG_ 2432641616 FASCurvatureRequest_ISig_4 100;
BA_ "GenSigCycleTimeActive" SG_ 2432641616 FASCurvatureRequest_ISig_4 100;
BA_ "GenSigStartValue" SG_ 2432641616 FASCurvatureRequest_ISig_4 65535;
BA_ "GenSigMaxLatency" SG_ 2432641616 FASCurvatureRequest_ISig_4 25;
BA_ "GenSigCycleTime" SG_ 2432641616 FASControlMode_ISig_4 100;
BA_ "GenSigCycleTimeActive" SG_ 2432641616 FASControlMode_ISig_4 100;
BA_ "GenSigStartValue" SG_ 2432641616 FASControlMode_ISig_4 15;
BA_ "GenSigMaxLatency" SG_ 2432641616 FASControlMode_ISig_4 25;
BA_ "GenSigCycleTime" SG_ 2432641616 FASExtCtrlMsgChecksum_ISig_4 100;
BA_ "GenSigCycleTimeActive" SG_ 2432641616 FASExtCtrlMsgChecksum_ISig_4 100;
BA_ "GenSigMaxLatency" SG_ 2432641616 FASExtCtrlMsgChecksum_ISig_4 25;
BA_ "GenSigCycleTime" SG_ 2432641616 ReferencePathCurvature_ISig_4 100;
BA_ "GenSigCycleTimeActive" SG_ 2432641616 ReferencePathCurvature_ISig_4 100;
BA_ "GenSigStartValue" SG_ 2432641616 ReferencePathCurvature_ISig_4 65535;
BA_ "GenSigMaxLatency" SG_ 2432641616 ReferencePathCurvature_ISig_4 25;
BA_ "GenSigCycleTime" SG_ 2432641616 FASExtCtrlMsgCounter_ISig_4 100;
BA_ "GenSigCycleTimeActive" SG_ 2432641616 FASExtCtrlMsgCounter_ISig_4 100;
BA_ "GenSigMaxLatency" SG_ 2432641616 FASExtCtrlMsgCounter_ISig_4 25;
BA_ "GenSigCycleTime" SG_ 2432641616 FASRoadWheelAngleRequest_ISig_4 100;
BA_ "GenSigCycleTimeActive" SG_ 2432641616 FASRoadWheelAngleRequest_ISig_4 100;
BA_ "GenSigStartValue" SG_ 2432641616 FASRoadWheelAngleRequest_ISig_4 65535;
BA_ "GenSigMaxLatency" SG_ 2432641616 FASRoadWheelAngleRequest_ISig_4 25;
BA_ "GenSigCycleTime" SG_ 2432640336 GlareFreeArea02_LeftAngle_ISig_4 100;
BA_ "GenSigCycleTimeActive" SG_ 2432640336 GlareFreeArea02_LeftAngle_ISig_4 100;
BA_ "GenSigStartValue" SG_ 2432640336 GlareFreeArea02_LeftAngle_ISig_4 2047;
BA_ "GenSigMaxLatency" SG_ 2432640336 GlareFreeArea02_LeftAngle_ISig_4 26;
BA_ "Platform_VMCU1_Sig" SG_ 2432640336 GlareFreeArea02_LeftAngle_ISig_4 1;
BA_ "GenSigCycleTime" SG_ 2432640336 GlareFreeArea02_RightAngle_ISig_ 100;
BA_ "GenSigCycleTimeActive" SG_ 2432640336 GlareFreeArea02_RightAngle_ISig_ 100;
BA_ "GenSigStartValue" SG_ 2432640336 GlareFreeArea02_RightAngle_ISig_ 2047;
BA_ "GenSigMaxLatency" SG_ 2432640336 GlareFreeArea02_RightAngle_ISig_ 26;
BA_ "Platform_VMCU1_Sig" SG_ 2432640336 GlareFreeArea02_RightAngle_ISig_ 1;
BA_ "SystemSignalLongSymbol" SG_ 2432640336 GlareFreeArea02_RightAngle_ISig_ "GlareFreeArea02_RightAngle_ISig_4";
BA_ "GenSigCycleTime" SG_ 2432640336 GlareFreeArea02_Distance_ISig_4 100;
BA_ "GenSigCycleTimeActive" SG_ 2432640336 GlareFreeArea02_Distance_ISig_4 100;
BA_ "GenSigStartValue" SG_ 2432640336 GlareFreeArea02_Distance_ISig_4 1023;
BA_ "GenSigMaxLatency" SG_ 2432640336 GlareFreeArea02_Distance_ISig_4 26;
BA_ "Platform_VMCU1_Sig" SG_ 2432640336 GlareFreeArea02_Distance_ISig_4 1;
BA_ "GenSigCycleTime" SG_ 2432639568 GlareFreeArea01_LeftAngle_ISig_4 100;
BA_ "GenSigCycleTimeActive" SG_ 2432639568 GlareFreeArea01_LeftAngle_ISig_4 100;
BA_ "GenSigStartValue" SG_ 2432639568 GlareFreeArea01_LeftAngle_ISig_4 2047;
BA_ "GenSigMaxLatency" SG_ 2432639568 GlareFreeArea01_LeftAngle_ISig_4 25;
BA_ "Platform_VMCU1_Sig" SG_ 2432639568 GlareFreeArea01_LeftAngle_ISig_4 1;
BA_ "GenSigCycleTime" SG_ 2432639568 GlareFreeArea03_Distance_ISig_4 100;
BA_ "GenSigCycleTimeActive" SG_ 2432639568 GlareFreeArea03_Distance_ISig_4 100;
BA_ "GenSigStartValue" SG_ 2432639568 GlareFreeArea03_Distance_ISig_4 1023;
BA_ "GenSigMaxLatency" SG_ 2432639568 GlareFreeArea03_Distance_ISig_4 25;
BA_ "Platform_VMCU1_Sig" SG_ 2432639568 GlareFreeArea03_Distance_ISig_4 1;
BA_ "GenSigCycleTime" SG_ 2432639568 GlareFreeArea03_LeftAngle_ISig_4 100;
BA_ "GenSigCycleTimeActive" SG_ 2432639568 GlareFreeArea03_LeftAngle_ISig_4 100;
BA_ "GenSigStartValue" SG_ 2432639568 GlareFreeArea03_LeftAngle_ISig_4 2047;
BA_ "GenSigMaxLatency" SG_ 2432639568 GlareFreeArea03_LeftAngle_ISig_4 25;
BA_ "Platform_VMCU1_Sig" SG_ 2432639568 GlareFreeArea03_LeftAngle_ISig_4 1;
BA_ "GenSigCycleTime" SG_ 2432639568 GlareFreeArea03_RightAngle_ISig_ 100;
BA_ "GenSigCycleTimeActive" SG_ 2432639568 GlareFreeArea03_RightAngle_ISig_ 100;
BA_ "GenSigStartValue" SG_ 2432639568 GlareFreeArea03_RightAngle_ISig_ 2047;
BA_ "GenSigMaxLatency" SG_ 2432639568 GlareFreeArea03_RightAngle_ISig_ 25;
BA_ "Platform_VMCU1_Sig" SG_ 2432639568 GlareFreeArea03_RightAngle_ISig_ 1;
BA_ "SystemSignalLongSymbol" SG_ 2432639568 GlareFreeArea03_RightAngle_ISig_ "GlareFreeArea03_RightAngle_ISig_4";
BA_ "GenSigCycleTime" SG_ 2432639568 GlareFreeArea01_Distance_ISig_4 100;
BA_ "GenSigCycleTimeActive" SG_ 2432639568 GlareFreeArea01_Distance_ISig_4 100;
BA_ "GenSigStartValue" SG_ 2432639568 GlareFreeArea01_Distance_ISig_4 1023;
BA_ "GenSigMaxLatency" SG_ 2432639568 GlareFreeArea01_Distance_ISig_4 25;
BA_ "Platform_VMCU1_Sig" SG_ 2432639568 GlareFreeArea01_Distance_ISig_4 1;
BA_ "GenSigCycleTime" SG_ 2432639568 GlareFreeArea01_RightAngle_ISig_ 100;
BA_ "GenSigCycleTimeActive" SG_ 2432639568 GlareFreeArea01_RightAngle_ISig_ 100;
BA_ "GenSigStartValue" SG_ 2432639568 GlareFreeArea01_RightAngle_ISig_ 2047;
BA_ "GenSigMaxLatency" SG_ 2432639568 GlareFreeArea01_RightAngle_ISig_ 25;
BA_ "Platform_VMCU1_Sig" SG_ 2432639568 GlareFreeArea01_RightAngle_ISig_ 1;
BA_ "SystemSignalLongSymbol" SG_ 2432639568 GlareFreeArea01_RightAngle_ISig_ "GlareFreeArea01_RightAngle_ISig_4";
BA_ "GenSigCycleTime" SG_ 2499772240 TrafficSituationCriticality 100;
BA_ "GenSigCycleTimeActive" SG_ 2499772240 TrafficSituationCriticality 100;
BA_ "GenSigStartValue" SG_ 2499772240 TrafficSituationCriticality 7;
BA_ "GenSigCycleTime" SG_ 2499772240 VisionLight_stat 100;
BA_ "GenSigCycleTimeActive" SG_ 2499772240 VisionLight_stat 100;
BA_ "GenSigStartValue" SG_ 2499772240 VisionLight_stat 7;
BA_ "Platform_VMCU1_Sig" SG_ 2499772240 VisionLight_stat 1;
BA_ "GenSigCycleTime" SG_ 2499772240 BBSteeringStatus_ISig_4 100;
BA_ "GenSigCycleTimeActive" SG_ 2499772240 BBSteeringStatus_ISig_4 100;
BA_ "GenSigStartValue" SG_ 2499772240 BBSteeringStatus_ISig_4 3;
BA_ "GenSigCycleTime" SG_ 2499772240 ACCiSeeDistanceGap 100;
BA_ "GenSigCycleTimeActive" SG_ 2499772240 ACCiSeeDistanceGap 100;
BA_ "GenSigStartValue" SG_ 2499772240 ACCiSeeDistanceGap 255;
BA_ "Platform_VMCU1_Sig" SG_ 2499772240 ACCiSeeDistanceGap 1;
BA_ "GenSigCycleTime" SG_ 2466246992 ForwardLookingCameraStatus_ISig_ 100;
BA_ "GenSigCycleTimeActive" SG_ 2466246992 ForwardLookingCameraStatus_ISig_ 100;
BA_ "GenSigStartValue" SG_ 2466246992 ForwardLookingCameraStatus_ISig_ 15;
BA_ "GenSigMaxLatency" SG_ 2466246992 ForwardLookingCameraStatus_ISig_ 40;
BA_ "Platform_VMCU1_Sig" SG_ 2466246992 ForwardLookingCameraStatus_ISig_ 1;
BA_ "SystemSignalLongSymbol" SG_ 2466246992 ForwardLookingCameraStatus_ISig_ "ForwardLookingCameraStatus_ISig_4";
BA_ "GenSigCycleTime" SG_ 2466246992 XARDACU_ControlMode 100;
BA_ "GenSigCycleTimeActive" SG_ 2466246992 XARDACU_ControlMode 100;
BA_ "GenSigStartValue" SG_ 2466246992 XARDACU_ControlMode 3;
BA_ "GenSigMaxLatency" SG_ 2466246992 XARDACU_ControlMode 50;
BA_ "Platform_VMCU1_Sig" SG_ 2466246992 XARDACU_ControlMode 1;
BA_ "SeToolAncestorID_SIGNAL" SG_ 2466246992 XARDACU_ControlMode "x0000001D0425403E";
BA_ "SeToolItemID_SIGNAL" SG_ 2466246992 XARDACU_ControlMode "x0000001D0425403E";
BA_ "SeToolName_SIGNAL" SG_ 2466246992 XARDACU_ControlMode "ControlMode";
BA_ "SeToolOwnerSigGroupID_SIGNAL" SG_ 2466246992 XARDACU_ControlMode "x0000001D043FB722";
BA_ "SeToolOwnerSigGroup_SIGNAL" SG_ 2466246992 XARDACU_ControlMode "XARDACU";
BA_ "SeToolVersion_SIGNAL" SG_ 2466246992 XARDACU_ControlMode "1";
BA_ "GenSigCycleTime" SG_ 2466246992 ACCiRollInhibit 100;
BA_ "GenSigCycleTimeActive" SG_ 2466246992 ACCiRollInhibit 100;
BA_ "GenSigStartValue" SG_ 2466246992 ACCiRollInhibit 3;
BA_ "Platform_VMCU1_Sig" SG_ 2466246992 ACCiRollInhibit 1;
BA_ "GenSigCycleTime" SG_ 2466246992 CMReducedAbilityStatus 100;
BA_ "GenSigCycleTimeActive" SG_ 2466246992 CMReducedAbilityStatus 100;
BA_ "GenSigStartValue" SG_ 2466246992 CMReducedAbilityStatus 7;
BA_ "Platform_VMCU1_Sig" SG_ 2466246992 CMReducedAbilityStatus 1;
BA_ "GenSigCycleTime" SG_ 2466246992 CollisionSituationAliveAck 100;
BA_ "GenSigCycleTimeActive" SG_ 2466246992 CollisionSituationAliveAck 100;
BA_ "GenSigStartValue" SG_ 2466246992 CollisionSituationAliveAck 15;
BA_ "Platform_VMCU1_Sig" SG_ 2466246992 CollisionSituationAliveAck 1;
BA_ "GenSigCycleTime" SG_ 2466246992 ForwardLookingRadarStatus_ISig_4 100;
BA_ "GenSigCycleTimeActive" SG_ 2466246992 ForwardLookingRadarStatus_ISig_4 100;
BA_ "GenSigStartValue" SG_ 2466246992 ForwardLookingRadarStatus_ISig_4 15;
BA_ "GenSigMaxLatency" SG_ 2466246992 ForwardLookingRadarStatus_ISig_4 40;
BA_ "Platform_VMCU1_Sig" SG_ 2466246992 ForwardLookingRadarStatus_ISig_4 1;
BA_ "GenSigCycleTime" SG_ 2466246992 XPRRequest_CM_ISig_4 100;
BA_ "GenSigCycleTimeActive" SG_ 2466246992 XPRRequest_CM_ISig_4 100;
BA_ "GenSigStartValue" SG_ 2466246992 XPRRequest_CM_ISig_4 255;
BA_ "Platform_VMCU1_Sig" SG_ 2466246992 XPRRequest_CM_ISig_4 1;
BA_ "GenSigCycleTime" SG_ 2466246992 LPOSBlocked 100;
BA_ "GenSigCycleTimeActive" SG_ 2466246992 LPOSBlocked 100;
BA_ "GenSigStartValue" SG_ 2466246992 LPOSBlocked 3;
BA_ "GenSigCycleTime" SG_ 2466246992 XARDACU_AccelDemand 100;
BA_ "GenSigCycleTimeActive" SG_ 2466246992 XARDACU_AccelDemand 100;
BA_ "GenSigStartValue" SG_ 2466246992 XARDACU_AccelDemand 65535;
BA_ "GenSigMaxLatency" SG_ 2466246992 XARDACU_AccelDemand 50;
BA_ "Platform_VMCU1_Sig" SG_ 2466246992 XARDACU_AccelDemand 1;
BA_ "SeToolAncestorID_SIGNAL" SG_ 2466246992 XARDACU_AccelDemand "x0000001D04254042";
BA_ "SeToolItemID_SIGNAL" SG_ 2466246992 XARDACU_AccelDemand "x0000001D04254042";
BA_ "SeToolName_SIGNAL" SG_ 2466246992 XARDACU_AccelDemand "AccelDemand";
BA_ "SeToolOwnerSigGroupID_SIGNAL" SG_ 2466246992 XARDACU_AccelDemand "x0000001D043FB722";
BA_ "SeToolOwnerSigGroup_SIGNAL" SG_ 2466246992 XARDACU_AccelDemand "XARDACU";
BA_ "SeToolVersion_SIGNAL" SG_ 2466246992 XARDACU_AccelDemand "1";
BA_ "GenSigCycleTime" SG_ 2466246992 CollSituationHazardLightReq 100;
BA_ "GenSigCycleTimeActive" SG_ 2466246992 CollSituationHazardLightReq 100;
BA_ "GenSigStartValue" SG_ 2466246992 CollSituationHazardLightReq 7;
BA_ "Platform_VMCU1_Sig" SG_ 2466246992 CollSituationHazardLightReq 1;
BA_ "GenSigCycleTime" SG_ 2432690512 PathDeviationDriverAlert 100;
BA_ "GenSigCycleTimeActive" SG_ 2432690512 PathDeviationDriverAlert 100;
BA_ "GenSigStartValue" SG_ 2432690512 PathDeviationDriverAlert 7;
BA_ "GenSigMaxLatency" SG_ 2432690512 PathDeviationDriverAlert 48;
BA_ "Platform_VMCU1_Sig" SG_ 2432690512 PathDeviationDriverAlert 1;
BA_ "SeToolAncestorID_SIGNAL" SG_ 2432690512 PathDeviationDriverAlert "x0000001D04168B9E";
BA_ "SeToolItemID_SIGNAL" SG_ 2432690512 PathDeviationDriverAlert "x0000001D043EF492";
BA_ "SeToolName_SIGNAL" SG_ 2432690512 PathDeviationDriverAlert "LKSDepartureWarningStatus";
BA_ "SeToolVersion_SIGNAL" SG_ 2432690512 PathDeviationDriverAlert "2";
BA_ "GenSigCycleTime" SG_ 2432690512 CM_DisengageDrivelineRequest 100;
BA_ "GenSigCycleTimeActive" SG_ 2432690512 CM_DisengageDrivelineRequest 100;
BA_ "GenSigStartValue" SG_ 2432690512 CM_DisengageDrivelineRequest 3;
BA_ "GenSigMaxLatency" SG_ 2432690512 CM_DisengageDrivelineRequest 48;
BA_ "Platform_VMCU1_Sig" SG_ 2432690512 CM_DisengageDrivelineRequest 1;
BA_ "SeToolAncestorID_SIGNAL" SG_ 2432690512 CM_DisengageDrivelineRequest "x0000001D0417E893";
BA_ "SeToolItemID_SIGNAL" SG_ 2432690512 CM_DisengageDrivelineRequest "x0000001D0435A0FF";
BA_ "SeToolName_SIGNAL" SG_ 2432690512 CM_DisengageDrivelineRequest "CM_DisengageDrivelineRequest";
BA_ "SeToolVersion_SIGNAL" SG_ 2432690512 CM_DisengageDrivelineRequest "2";
BA_ "GenSigCycleTime" SG_ 2432690512 ACCBrakeRequestStatus 100;
BA_ "GenSigCycleTimeActive" SG_ 2432690512 ACCBrakeRequestStatus 100;
BA_ "GenSigStartValue" SG_ 2432690512 ACCBrakeRequestStatus 3;
BA_ "GenSigMaxLatency" SG_ 2432690512 ACCBrakeRequestStatus 48;
BA_ "Platform_VMCU1_Sig" SG_ 2432690512 ACCBrakeRequestStatus 1;
BA_ "GenSigCycleTime" SG_ 2432690512 FrontalCollisionDriverAlert_ISig 100;
BA_ "GenSigCycleTimeActive" SG_ 2432690512 FrontalCollisionDriverAlert_ISig 100;
BA_ "GenSigStartValue" SG_ 2432690512 FrontalCollisionDriverAlert_ISig 7;
BA_ "GenSigMaxLatency" SG_ 2432690512 FrontalCollisionDriverAlert_ISig 48;
BA_ "Platform_VMCU1_Sig" SG_ 2432690512 FrontalCollisionDriverAlert_ISig 1;
BA_ "SeToolAncestorID_SIGNAL" SG_ 2432690512 FrontalCollisionDriverAlert_ISig "x0000001D0416642E";
BA_ "SeToolItemID_SIGNAL" SG_ 2432690512 FrontalCollisionDriverAlert_ISig "x0000001D0428BE70";
BA_ "SeToolName_SIGNAL" SG_ 2432690512 FrontalCollisionDriverAlert_ISig "FCW_Warning";
BA_ "SeToolVersion_SIGNAL" SG_ 2432690512 FrontalCollisionDriverAlert_ISig "2";
BA_ "SystemSignalLongSymbol" SG_ 2432690512 FrontalCollisionDriverAlert_ISig "FrontalCollisionDriverAlert_ISig_4";
BA_ "GenSigCycleTime" SG_ 2432690512 ACC_SGOFaultCondStat_SeatBelt 100;
BA_ "GenSigCycleTimeActive" SG_ 2432690512 ACC_SGOFaultCondStat_SeatBelt 100;
BA_ "Platform_VMCU1_Sig" SG_ 2432690512 ACC_SGOFaultCondStat_SeatBelt 1;
BA_ "GenSigCycleTime" SG_ 2432690512 CM_Status_ISig_4 100;
BA_ "GenSigCycleTimeActive" SG_ 2432690512 CM_Status_ISig_4 100;
BA_ "GenSigStartValue" SG_ 2432690512 CM_Status_ISig_4 7;
BA_ "GenSigMaxLatency" SG_ 2432690512 CM_Status_ISig_4 48;
BA_ "Platform_VMCU1_Sig" SG_ 2432690512 CM_Status_ISig_4 1;
BA_ "SeToolAncestorID_SIGNAL" SG_ 2432690512 CM_Status_ISig_4 "x0000001D0417D4DA";
BA_ "SeToolItemID_SIGNAL" SG_ 2432690512 CM_Status_ISig_4 "x0000001D0428BE35";
BA_ "SeToolName_SIGNAL" SG_ 2432690512 CM_Status_ISig_4 "CM_Status";
BA_ "SeToolVersion_SIGNAL" SG_ 2432690512 CM_Status_ISig_4 "2";
BA_ "GenSigCycleTime" SG_ 2432690512 DASApplicationStatus 100;
BA_ "GenSigCycleTimeActive" SG_ 2432690512 DASApplicationStatus 100;
BA_ "GenSigStartValue" SG_ 2432690512 DASApplicationStatus 7;
BA_ "GenSigMaxLatency" SG_ 2432690512 DASApplicationStatus 48;
BA_ "Platform_VMCU1_Sig" SG_ 2432690512 DASApplicationStatus 1;
BA_ "SeToolAncestorID_SIGNAL" SG_ 2432690512 DASApplicationStatus "x0000001D04169A83";
BA_ "SeToolItemID_SIGNAL" SG_ 2432690512 DASApplicationStatus "x0000001D04253A46";
BA_ "SeToolName_SIGNAL" SG_ 2432690512 DASApplicationStatus "DASSystemStatus";
BA_ "SeToolVersion_SIGNAL" SG_ 2432690512 DASApplicationStatus "2";
BA_ "GenSigCycleTime" SG_ 2432690512 ACC_Status 100;
BA_ "GenSigCycleTimeActive" SG_ 2432690512 ACC_Status 100;
BA_ "GenSigStartValue" SG_ 2432690512 ACC_Status 7;
BA_ "GenSigMaxLatency" SG_ 2432690512 ACC_Status 48;
BA_ "Platform_VMCU1_Sig" SG_ 2432690512 ACC_Status 1;
BA_ "SeToolAncestorID_SIGNAL" SG_ 2432690512 ACC_Status "x0000001D041F8BDE";
BA_ "SeToolItemID_SIGNAL" SG_ 2432690512 ACC_Status "x0000001D0427537B";
BA_ "SeToolName_SIGNAL" SG_ 2432690512 ACC_Status "ACC_Status";
BA_ "SeToolVersion_SIGNAL" SG_ 2432690512 ACC_Status "2";
BA_ "GenSigCycleTime" SG_ 2432690512 LKSApplicationStatus 100;
BA_ "GenSigCycleTimeActive" SG_ 2432690512 LKSApplicationStatus 100;
BA_ "GenSigStartValue" SG_ 2432690512 LKSApplicationStatus 7;
BA_ "GenSigMaxLatency" SG_ 2432690512 LKSApplicationStatus 48;
BA_ "Platform_VMCU1_Sig" SG_ 2432690512 LKSApplicationStatus 1;
BA_ "SeToolAncestorID_SIGNAL" SG_ 2432690512 LKSApplicationStatus "x0000001D04168BAE";
BA_ "SeToolItemID_SIGNAL" SG_ 2432690512 LKSApplicationStatus "x0000001D043BCC5C";
BA_ "SeToolName_SIGNAL" SG_ 2432690512 LKSApplicationStatus "LKSStatus";
BA_ "SeToolVersion_SIGNAL" SG_ 2432690512 LKSApplicationStatus "3";
BA_ "GenSigCycleTime" SG_ 2432690512 LCSSystemStatus 100;
BA_ "GenSigCycleTimeActive" SG_ 2432690512 LCSSystemStatus 100;
BA_ "GenSigStartValue" SG_ 2432690512 LCSSystemStatus 7;
BA_ "GenSigMaxLatency" SG_ 2432690512 LCSSystemStatus 48;
BA_ "Platform_VMCU1_Sig" SG_ 2432690512 LCSSystemStatus 1;
BA_ "SeToolAncestorID_SIGNAL" SG_ 2432690512 LCSSystemStatus "x0000001D043A89E4";
BA_ "SeToolItemID_SIGNAL" SG_ 2432690512 LCSSystemStatus "x0000001D043A89E4";
BA_ "SeToolName_SIGNAL" SG_ 2432690512 LCSSystemStatus "LCSSystemStatus";
BA_ "SeToolVersion_SIGNAL" SG_ 2432690512 LCSSystemStatus "1";
BA_ "GenSigCycleTime" SG_ 2432690512 ACC_SGOFaultCondStat_SigStat 100;
BA_ "GenSigCycleTimeActive" SG_ 2432690512 ACC_SGOFaultCondStat_SigStat 100;
BA_ "Platform_VMCU1_Sig" SG_ 2432690512 ACC_SGOFaultCondStat_SigStat 1;
BA_ "GenSigCycleTime" SG_ 2432690512 ACC_SGOFaultCondStat_Target 100;
BA_ "GenSigCycleTimeActive" SG_ 2432690512 ACC_SGOFaultCondStat_Target 100;
BA_ "Platform_VMCU1_Sig" SG_ 2432690512 ACC_SGOFaultCondStat_Target 1;
BA_ "GenSigCycleTime" SG_ 2432690512 FCW_Status 100;
BA_ "GenSigCycleTimeActive" SG_ 2432690512 FCW_Status 100;
BA_ "GenSigStartValue" SG_ 2432690512 FCW_Status 3;
BA_ "GenSigMaxLatency" SG_ 2432690512 FCW_Status 48;
BA_ "Platform_VMCU1_Sig" SG_ 2432690512 FCW_Status 1;
BA_ "SeToolAncestorID_SIGNAL" SG_ 2432690512 FCW_Status "x0000001D04166451";
BA_ "SeToolItemID_SIGNAL" SG_ 2432690512 FCW_Status "x0000001D04166451";
BA_ "SeToolName_SIGNAL" SG_ 2432690512 FCW_Status "FCW_Status";
BA_ "SeToolVersion_SIGNAL" SG_ 2432690512 FCW_Status "1";
BA_ "GenSigCycleTime" SG_ 2432690512 DriverImpairedDriverAlert 100;
BA_ "GenSigCycleTimeActive" SG_ 2432690512 DriverImpairedDriverAlert 100;
BA_ "GenSigStartValue" SG_ 2432690512 DriverImpairedDriverAlert 7;
BA_ "GenSigMaxLatency" SG_ 2432690512 DriverImpairedDriverAlert 48;
BA_ "Platform_VMCU1_Sig" SG_ 2432690512 DriverImpairedDriverAlert 1;
BA_ "SeToolAncestorID_SIGNAL" SG_ 2432690512 DriverImpairedDriverAlert "x0000001D04169AB3";
BA_ "SeToolItemID_SIGNAL" SG_ 2432690512 DriverImpairedDriverAlert "x0000001D04169AB3";
BA_ "SeToolName_SIGNAL" SG_ 2432690512 DriverImpairedDriverAlert "DASImpairmentWarningStatus";
BA_ "SeToolVersion_SIGNAL" SG_ 2432690512 DriverImpairedDriverAlert "1";
BA_ "GenSigCycleTime" SG_ 2432690512 DriverVigilanceLevel 100;
BA_ "GenSigCycleTimeActive" SG_ 2432690512 DriverVigilanceLevel 100;
BA_ "GenSigStartValue" SG_ 2432690512 DriverVigilanceLevel 7;
BA_ "GenSigMaxLatency" SG_ 2432690512 DriverVigilanceLevel 48;
BA_ "Platform_VMCU1_Sig" SG_ 2432690512 DriverVigilanceLevel 1;
BA_ "SeToolAncestorID_SIGNAL" SG_ 2432690512 DriverVigilanceLevel "x0000001D04169ABA";
BA_ "SeToolItemID_SIGNAL" SG_ 2432690512 DriverVigilanceLevel "x0000001D043EBF2F";
BA_ "SeToolName_SIGNAL" SG_ 2432690512 DriverVigilanceLevel "DASVigilanceLevelStatus";
BA_ "SeToolVersion_SIGNAL" SG_ 2432690512 DriverVigilanceLevel "2";
BA_ "GenSigCycleTime" SG_ 2432690512 ACCForwardVehicleSpeed_ISig_4 100;
BA_ "GenSigCycleTimeActive" SG_ 2432690512 ACCForwardVehicleSpeed_ISig_4 100;
BA_ "GenSigStartValue" SG_ 2432690512 ACCForwardVehicleSpeed_ISig_4 255;
BA_ "GenSigMaxLatency" SG_ 2432690512 ACCForwardVehicleSpeed_ISig_4 48;
BA_ "Platform_VMCU1_Sig" SG_ 2432690512 ACCForwardVehicleSpeed_ISig_4 1;
BA_ "SeToolAncestorID_SIGNAL" SG_ 2432690512 ACCForwardVehicleSpeed_ISig_4 "x0000001D04147192";
BA_ "SeToolItemID_SIGNAL" SG_ 2432690512 ACCForwardVehicleSpeed_ISig_4 "x0000001D04147192";
BA_ "SeToolName_SIGNAL" SG_ 2432690512 ACCForwardVehicleSpeed_ISig_4 "ACCForwardVehicleSpeed";
BA_ "SeToolVersion_SIGNAL" SG_ 2432690512 ACCForwardVehicleSpeed_ISig_4 "1";
BA_ "GenSigCycleTime" SG_ 2432690512 ACC_SGOFaultCondStat_Door 100;
BA_ "GenSigCycleTimeActive" SG_ 2432690512 ACC_SGOFaultCondStat_Door 100;
BA_ "Platform_VMCU1_Sig" SG_ 2432690512 ACC_SGOFaultCondStat_Door 1;
BA_ "GenSigCycleTime" SG_ 2432690512 ACCTargetDetected 100;
BA_ "GenSigCycleTimeActive" SG_ 2432690512 ACCTargetDetected 100;
BA_ "GenSigStartValue" SG_ 2432690512 ACCTargetDetected 3;
BA_ "GenSigMaxLatency" SG_ 2432690512 ACCTargetDetected 48;
BA_ "Platform_VMCU1_Sig" SG_ 2432690512 ACCTargetDetected 1;
BA_ "SeToolAncestorID_SIGNAL" SG_ 2432690512 ACCTargetDetected "x0000001D04146FC9";
BA_ "SeToolItemID_SIGNAL" SG_ 2432690512 ACCTargetDetected "x0000001D04146FC9";
BA_ "SeToolName_SIGNAL" SG_ 2432690512 ACCTargetDetected "ACCTargetDetected";
BA_ "SeToolVersion_SIGNAL" SG_ 2432690512 ACCTargetDetected "1";
BA_ "GenSigCycleTime" SG_ 2432690512 ACCForwardVehicleDistance_ISig_4 100;
BA_ "GenSigCycleTimeActive" SG_ 2432690512 ACCForwardVehicleDistance_ISig_4 100;
BA_ "GenSigStartValue" SG_ 2432690512 ACCForwardVehicleDistance_ISig_4 255;
BA_ "GenSigMaxLatency" SG_ 2432690512 ACCForwardVehicleDistance_ISig_4 48;
BA_ "Platform_VMCU1_Sig" SG_ 2432690512 ACCForwardVehicleDistance_ISig_4 1;
BA_ "SeToolAncestorID_SIGNAL" SG_ 2432690512 ACCForwardVehicleDistance_ISig_4 "x0000001D04147189";
BA_ "SeToolItemID_SIGNAL" SG_ 2432690512 ACCForwardVehicleDistance_ISig_4 "x0000001D04147189";
BA_ "SeToolName_SIGNAL" SG_ 2432690512 ACCForwardVehicleDistance_ISig_4 "ACCForwardVehicleDistance";
BA_ "SeToolVersion_SIGNAL" SG_ 2432690512 ACCForwardVehicleDistance_ISig_4 "1";
BA_ "GenSigCycleTime" SG_ 2432690512 LKSCorrectiveSteeringStatus 100;
BA_ "GenSigCycleTimeActive" SG_ 2432690512 LKSCorrectiveSteeringStatus 100;
BA_ "GenSigStartValue" SG_ 2432690512 LKSCorrectiveSteeringStatus 7;
BA_ "GenSigMaxLatency" SG_ 2432690512 LKSCorrectiveSteeringStatus 48;
BA_ "GenSigCycleTime" SG_ 2432690512 ACC_SGOFaultCondStat_Other 100;
BA_ "GenSigCycleTimeActive" SG_ 2432690512 ACC_SGOFaultCondStat_Other 100;
BA_ "Platform_VMCU1_Sig" SG_ 2432690512 ACC_SGOFaultCondStat_Other 1;
BA_ "GenSigCycleTime" SG_ 2432690512 LCSSoundSettingStatus 100;
BA_ "GenSigCycleTimeActive" SG_ 2432690512 LCSSoundSettingStatus 100;
BA_ "GenSigStartValue" SG_ 2432690512 LCSSoundSettingStatus 3;
BA_ "Platform_VMCU1_Sig" SG_ 2432690512 LCSSoundSettingStatus 1;
BA_ "GenSigCycleTime" SG_ 2432690512 ACC_SGOFaultCondStat_Speed 100;
BA_ "GenSigCycleTimeActive" SG_ 2432690512 ACC_SGOFaultCondStat_Speed 100;
BA_ "Platform_VMCU1_Sig" SG_ 2432690512 ACC_SGOFaultCondStat_Speed 1;
BA_ "GenSigSendType" SG_ 936 CIOM_BB2_32S_FCS 7;
BA_ "GenSigSendType" SG_ 935 EncryptedGBUnlockAuth_stat 1;
BA_ "GenSigMaxLatency" SG_ 935 EncryptedGBUnlockAuth_stat 1000;
BA_ "GenSigSendType" SG_ 1369 ParkClimTimerStat_Tue_ISig_4 1;
BA_ "NeedsUpdateBit" SG_ 1369 ParkClimTimerStat_Tue_ISig_4 1;
BA_ "GenSigSendType" SG_ 1369 ParkClimTimerStat_Mon_ISig_4 1;
BA_ "NeedsUpdateBit" SG_ 1369 ParkClimTimerStat_Mon_ISig_4 1;
BA_ "GenSigSendType" SG_ 1369 ParkClimTimerStat_Hrs_ISig_4 1;
BA_ "GenSigStartValue" SG_ 1369 ParkClimTimerStat_Hrs_ISig_4 255;
BA_ "NeedsUpdateBit" SG_ 1369 ParkClimTimerStat_Hrs_ISig_4 1;
BA_ "GenSigSendType" SG_ 1369 ParkClimTimerStat_TotalNoTimers_ 1;
BA_ "GenSigStartValue" SG_ 1369 ParkClimTimerStat_TotalNoTimers_ 255;
BA_ "NeedsUpdateBit" SG_ 1369 ParkClimTimerStat_TotalNoTimers_ 1;
BA_ "SystemSignalLongSymbol" SG_ 1369 ParkClimTimerStat_TotalNoTimers_ "ParkClimTimerStat_TotalNoTimers_ISig_4";
BA_ "GenSigSendType" SG_ 1369 ParkClimTimerStat_Thu_ISig_4 1;
BA_ "NeedsUpdateBit" SG_ 1369 ParkClimTimerStat_Thu_ISig_4 1;
BA_ "GenSigSendType" SG_ 1369 ParkClimTimerStat_MinRes_ISig_4 1;
BA_ "GenSigStartValue" SG_ 1369 ParkClimTimerStat_MinRes_ISig_4 7;
BA_ "NeedsUpdateBit" SG_ 1369 ParkClimTimerStat_MinRes_ISig_4 1;
BA_ "GenSigSendType" SG_ 1369 ParkClimTimerStat_Status_ISig_4 1;
BA_ "GenSigStartValue" SG_ 1369 ParkClimTimerStat_Status_ISig_4 3;
BA_ "NeedsUpdateBit" SG_ 1369 ParkClimTimerStat_Status_ISig_4 1;
BA_ "GenSigSendType" SG_ 1369 ParkClimTimerStat_Sun_ISig_4 1;
BA_ "NeedsUpdateBit" SG_ 1369 ParkClimTimerStat_Sun_ISig_4 1;
BA_ "GenSigSendType" SG_ 1369 ParkClimTimerStat_sg_UB_ISig_4 7;
BA_ "GenSigSendType" SG_ 1369 ParkClimTimerStat_TimerNr_ISig_4 1;
BA_ "GenSigStartValue" SG_ 1369 ParkClimTimerStat_TimerNr_ISig_4 255;
BA_ "NeedsUpdateBit" SG_ 1369 ParkClimTimerStat_TimerNr_ISig_4 1;
BA_ "GenSigSendType" SG_ 1369 ParkClimTimerStat_Rec_ISig_4 1;
BA_ "NeedsUpdateBit" SG_ 1369 ParkClimTimerStat_Rec_ISig_4 1;
BA_ "GenSigSendType" SG_ 1369 ParkClimTimerStat_Wed_ISig_4 1;
BA_ "NeedsUpdateBit" SG_ 1369 ParkClimTimerStat_Wed_ISig_4 1;
BA_ "GenSigSendType" SG_ 1369 ParkClimTimerStat_Min_ISig_4 1;
BA_ "GenSigStartValue" SG_ 1369 ParkClimTimerStat_Min_ISig_4 255;
BA_ "NeedsUpdateBit" SG_ 1369 ParkClimTimerStat_Min_ISig_4 1;
BA_ "GenSigSendType" SG_ 1369 ParkClimTimerStat_Type_ISig_4 1;
BA_ "GenSigStartValue" SG_ 1369 ParkClimTimerStat_Type_ISig_4 7;
BA_ "NeedsUpdateBit" SG_ 1369 ParkClimTimerStat_Type_ISig_4 1;
BA_ "GenSigSendType" SG_ 1369 ParkClimTimerStat_Sat_ISig_4 1;
BA_ "NeedsUpdateBit" SG_ 1369 ParkClimTimerStat_Sat_ISig_4 1;
BA_ "GenSigSendType" SG_ 1369 ParkClimTimerStat_Temp_ISig_4 1;
BA_ "GenSigStartValue" SG_ 1369 ParkClimTimerStat_Temp_ISig_4 255;
BA_ "NeedsUpdateBit" SG_ 1369 ParkClimTimerStat_Temp_ISig_4 1;
BA_ "GenSigSendType" SG_ 1369 ParkClimTimerStat_Dur_ISig_4 1;
BA_ "GenSigStartValue" SG_ 1369 ParkClimTimerStat_Dur_ISig_4 127;
BA_ "NeedsUpdateBit" SG_ 1369 ParkClimTimerStat_Dur_ISig_4 1;
BA_ "GenSigSendType" SG_ 1369 ParkClimTimerStat_Fri_ISig_4 1;
BA_ "NeedsUpdateBit" SG_ 1369 ParkClimTimerStat_Fri_ISig_4 1;
BA_ "GenSigCycleTime" SG_ 551 AutoBlowerLevel_Status_ISig_4 100;
BA_ "GenSigCycleTimeActive" SG_ 551 AutoBlowerLevel_Status_ISig_4 100;
BA_ "GenSigStartValue" SG_ 551 AutoBlowerLevel_Status_ISig_4 7;
BA_ "GenSigCycleTime" SG_ 551 AutoDefogmode_Status_ISig_4 100;
BA_ "GenSigCycleTimeActive" SG_ 551 AutoDefogmode_Status_ISig_4 100;
BA_ "GenSigStartValue" SG_ 551 AutoDefogmode_Status_ISig_4 7;
BA_ "GenSigCycleTime" SG_ 551 AQSmode_Status_ISig_4 100;
BA_ "GenSigCycleTimeActive" SG_ 551 AQSmode_Status_ISig_4 100;
BA_ "GenSigStartValue" SG_ 551 AQSmode_Status_ISig_4 3;
BA_ "GenSigCycleTime" SG_ 551 ACmode_Status_ISig_4 100;
BA_ "GenSigCycleTimeActive" SG_ 551 ACmode_Status_ISig_4 100;
BA_ "GenSigStartValue" SG_ 551 ACmode_Status_ISig_4 7;
BA_ "GenSigCycleTime" SG_ 2432685120 LKSCSEnableSwitch_rqst 100;
BA_ "GenSigCycleTimeActive" SG_ 2432685120 LKSCSEnableSwitch_rqst 100;
BA_ "GenSigStartValue" SG_ 2432685120 LKSCSEnableSwitch_rqst 3;
BA_ "GenSigMaxLatency" SG_ 2432685120 LKSCSEnableSwitch_rqst 48;
BA_ "GenSigCycleTime" SG_ 2566078272 TrafficAccidentHazardLightRqst_I 100;
BA_ "GenSigCycleTimeActive" SG_ 2566078272 TrafficAccidentHazardLightRqst_I 100;
BA_ "GenSigStartValue" SG_ 2566078272 TrafficAccidentHazardLightRqst_I 3;
BA_ "SystemSignalLongSymbol" SG_ 2566078272 TrafficAccidentHazardLightRqst_I "TrafficAccidentHazardLightRqst_ISig_4";
BA_ "GenSigCycleTime" SG_ 2566078272 GearboxUnlockAuth_stat 100;
BA_ "GenSigCycleTimeActive" SG_ 2566078272 GearboxUnlockAuth_stat 100;
BA_ "GenSigStartValue" SG_ 2566078272 GearboxUnlockAuth_stat 7;
BA_ "GenSigSendType" SG_ 2490646336 MediaSourcesListReq_SInfo_ISig_4 1;
BA_ "GenSigStartValue" SG_ 2490646336 MediaSourcesListReq_SInfo_ISig_4 3;
BA_ "GenSigMaxLatency" SG_ 2490646336 MediaSourcesListReq_SInfo_ISig_4 50;
BA_ "NeedsUpdateBit" SG_ 2490646336 MediaSourcesListReq_SInfo_ISig_4 1;
BA_ "Platform_VMCU1_Sig" SG_ 2490646336 MediaSourcesListReq_SInfo_ISig_4 1;
BA_ "GenSigSendType" SG_ 2490646336 MediaSourcesListReq_Items_ISig_4 1;
BA_ "GenSigMaxLatency" SG_ 2490646336 MediaSourcesListReq_Items_ISig_4 50;
BA_ "NeedsUpdateBit" SG_ 2490646336 MediaSourcesListReq_Items_ISig_4 1;
BA_ "Platform_VMCU1_Sig" SG_ 2490646336 MediaSourcesListReq_Items_ISig_4 1;
BA_ "GenSigSendType" SG_ 2490646336 MediaSourcesListReq_sg_UB_ISig_4 7;
BA_ "Platform_VMCU1_Sig" SG_ 2490646336 MediaSourcesListReq_sg_UB_ISig_4 1;
BA_ "GenSigSendType" SG_ 2490646336 MediaSourcesListReq_ItemID_ISig_ 1;
BA_ "GenSigMaxLatency" SG_ 2490646336 MediaSourcesListReq_ItemID_ISig_ 50;
BA_ "NeedsUpdateBit" SG_ 2490646336 MediaSourcesListReq_ItemID_ISig_ 1;
BA_ "Platform_VMCU1_Sig" SG_ 2490646336 MediaSourcesListReq_ItemID_ISig_ 1;
BA_ "SystemSignalLongSymbol" SG_ 2490646336 MediaSourcesListReq_ItemID_ISig_ "MediaSourcesListReq_ItemID_ISig_4";
BA_ "GenSigSendType" SG_ 2499780850 AlmClkSetAlm_LECM_rq_Type_ISig_4 1;
BA_ "GenSigStartValue" SG_ 2499780850 AlmClkSetAlm_LECM_rq_Type_ISig_4 7;
BA_ "GenSigMaxLatency" SG_ 2499780850 AlmClkSetAlm_LECM_rq_Type_ISig_4 126;
BA_ "Platform_VMCU1_Sig" SG_ 2499780850 AlmClkSetAlm_LECM_rq_Type_ISig_4 1;
BA_ "GenSigSendType" SG_ 2499780850 AlmClkSetAlm_LECM_rq_ID_ISig_4 1;
BA_ "GenSigStartValue" SG_ 2499780850 AlmClkSetAlm_LECM_rq_ID_ISig_4 127;
BA_ "GenSigMaxLatency" SG_ 2499780850 AlmClkSetAlm_LECM_rq_ID_ISig_4 126;
BA_ "Platform_VMCU1_Sig" SG_ 2499780850 AlmClkSetAlm_LECM_rq_ID_ISig_4 1;
BA_ "GenSigSendType" SG_ 2499780850 AlmClkSetAlm_LECM_rq_SetHr_ISig_ 1;
BA_ "GenSigStartValue" SG_ 2499780850 AlmClkSetAlm_LECM_rq_SetHr_ISig_ 31;
BA_ "GenSigMaxLatency" SG_ 2499780850 AlmClkSetAlm_LECM_rq_SetHr_ISig_ 126;
BA_ "Platform_VMCU1_Sig" SG_ 2499780850 AlmClkSetAlm_LECM_rq_SetHr_ISig_ 1;
BA_ "SystemSignalLongSymbol" SG_ 2499780850 AlmClkSetAlm_LECM_rq_SetHr_ISig_ "AlmClkSetAlm_LECM_rq_SetHr_ISig_4";
BA_ "GenSigSendType" SG_ 2499780850 AlmClkSetAlm_LECM_rq_Stat_ISig_4 1;
BA_ "GenSigMaxLatency" SG_ 2499780850 AlmClkSetAlm_LECM_rq_Stat_ISig_4 126;
BA_ "Platform_VMCU1_Sig" SG_ 2499780850 AlmClkSetAlm_LECM_rq_Stat_ISig_4 1;
BA_ "GenSigSendType" SG_ 2499780850 AlmClkSetAlm_LECM_rq_SetMin_ISig 1;
BA_ "GenSigStartValue" SG_ 2499780850 AlmClkSetAlm_LECM_rq_SetMin_ISig 63;
BA_ "GenSigMaxLatency" SG_ 2499780850 AlmClkSetAlm_LECM_rq_SetMin_ISig 126;
BA_ "Platform_VMCU1_Sig" SG_ 2499780850 AlmClkSetAlm_LECM_rq_SetMin_ISig 1;
BA_ "SystemSignalLongSymbol" SG_ 2499780850 AlmClkSetAlm_LECM_rq_SetMin_ISig "AlmClkSetAlm_LECM_rq_SetMin_ISig_4";
BA_ "GenSigSendType" SG_ 2499780850 AlmClkSetAlm_LECM_rq_DaySet_ISig 1;
BA_ "GenSigMaxLatency" SG_ 2499780850 AlmClkSetAlm_LECM_rq_DaySet_ISig 126;
BA_ "Platform_VMCU1_Sig" SG_ 2499780850 AlmClkSetAlm_LECM_rq_DaySet_ISig 1;
BA_ "SystemSignalLongSymbol" SG_ 2499780850 AlmClkSetAlm_LECM_rq_DaySet_ISig "AlmClkSetAlm_LECM_rq_DaySet_ISig_4";
BA_ "GenSigSendType" SG_ 2499780850 AlmClkSetAlm_LECM_rq_Mode_ISig_4 1;
BA_ "GenSigMaxLatency" SG_ 2499780850 AlmClkSetAlm_LECM_rq_Mode_ISig_4 126;
BA_ "Platform_VMCU1_Sig" SG_ 2499780850 AlmClkSetAlm_LECM_rq_Mode_ISig_4 1;
BA_ "GenSigSendType" SG_ 2482978624 TipperTailGateRequest_UB_ISig_4 7;
BA_ "Platform_VMCU1_Sig" SG_ 2482978624 TipperTailGateRequest_UB_ISig_4 1;
BA_ "GenSigCycleTime" SG_ 2482978624 ExtraHeating_status_ISig_4 100;
BA_ "GenSigCycleTimeActive" SG_ 2482978624 ExtraHeating_status_ISig_4 100;
BA_ "GenSigStartValue" SG_ 2482978624 ExtraHeating_status_ISig_4 3;
BA_ "GenSigCycleTime" SG_ 2482978624 FrontalCollisionAccidentStatus_I 100;
BA_ "GenSigCycleTimeActive" SG_ 2482978624 FrontalCollisionAccidentStatus_I 100;
BA_ "GenSigStartValue" SG_ 2482978624 FrontalCollisionAccidentStatus_I 3;
BA_ "SystemSignalLongSymbol" SG_ 2482978624 FrontalCollisionAccidentStatus_I "FrontalCollisionAccidentStatus_ISig_4";
BA_ "GenSigSendType" SG_ 2482978624 LoadDistributionRequested_UB_ISi 7;
BA_ "Platform_VMCU1_Sig" SG_ 2482978624 LoadDistributionRequested_UB_ISi 1;
BA_ "SystemSignalLongSymbol" SG_ 2482978624 LoadDistributionRequested_UB_ISi "LoadDistributionRequested_UB_ISig_4";
BA_ "GenSigCycleTime" SG_ 2482978624 TipperUpDownRequest_ISig_4 100;
BA_ "GenSigCycleTimeActive" SG_ 2482978624 TipperUpDownRequest_ISig_4 100;
BA_ "GenSigStartValue" SG_ 2482978624 TipperUpDownRequest_ISig_4 7;
BA_ "GenSigMaxLatency" SG_ 2482978624 TipperUpDownRequest_ISig_4 75;
BA_ "NeedsUpdateBit" SG_ 2482978624 TipperUpDownRequest_ISig_4 1;
BA_ "Platform_VMCU1_Sig" SG_ 2482978624 TipperUpDownRequest_ISig_4 1;
BA_ "GenSigSendType" SG_ 2482978624 TipperTarpaulinRequest_UB_ISig_4 7;
BA_ "Platform_VMCU1_Sig" SG_ 2482978624 TipperTarpaulinRequest_UB_ISig_4 1;
BA_ "GenSigCycleTime" SG_ 2482978624 LoadDistributionRequested_ISig_4 100;
BA_ "GenSigCycleTimeActive" SG_ 2482978624 LoadDistributionRequested_ISig_4 100;
BA_ "GenSigStartValue" SG_ 2482978624 LoadDistributionRequested_ISig_4 15;
BA_ "NeedsUpdateBit" SG_ 2482978624 LoadDistributionRequested_ISig_4 1;
BA_ "Platform_VMCU1_Sig" SG_ 2482978624 LoadDistributionRequested_ISig_4 1;
BA_ "GenSigSendType" SG_ 2482978624 TipperShakerRequest_UB_ISig_4 7;
BA_ "Platform_VMCU1_Sig" SG_ 2482978624 TipperShakerRequest_UB_ISig_4 1;
BA_ "GenSigSendType" SG_ 2482978624 TailLiftMotionRequest_UB_ISig_4 7;
BA_ "Platform_VMCU1_Sig" SG_ 2482978624 TailLiftMotionRequest_UB_ISig_4 1;
BA_ "GenSigCycleTime" SG_ 2482978624 TipperTailGateRequest_ISig_4 100;
BA_ "GenSigCycleTimeActive" SG_ 2482978624 TipperTailGateRequest_ISig_4 100;
BA_ "GenSigStartValue" SG_ 2482978624 TipperTailGateRequest_ISig_4 7;
BA_ "GenSigMaxLatency" SG_ 2482978624 TipperTailGateRequest_ISig_4 75;
BA_ "NeedsUpdateBit" SG_ 2482978624 TipperTailGateRequest_ISig_4 1;
BA_ "Platform_VMCU1_Sig" SG_ 2482978624 TipperTailGateRequest_ISig_4 1;
BA_ "GenSigCycleTime" SG_ 2482978624 TipperTippingBodySelection_ISig_ 100;
BA_ "GenSigCycleTimeActive" SG_ 2482978624 TipperTippingBodySelection_ISig_ 100;
BA_ "GenSigStartValue" SG_ 2482978624 TipperTippingBodySelection_ISig_ 3;
BA_ "GenSigMaxLatency" SG_ 2482978624 TipperTippingBodySelection_ISig_ 75;
BA_ "NeedsUpdateBit" SG_ 2482978624 TipperTippingBodySelection_ISig_ 1;
BA_ "Platform_VMCU1_Sig" SG_ 2482978624 TipperTippingBodySelection_ISig_ 1;
BA_ "SystemSignalLongSymbol" SG_ 2482978624 TipperTippingBodySelection_ISig_ "TipperTippingBodySelection_ISig_4";
BA_ "GenSigCycleTime" SG_ 2482978624 TipperEmergencyStop_ISig_4 100;
BA_ "GenSigCycleTimeActive" SG_ 2482978624 TipperEmergencyStop_ISig_4 100;
BA_ "GenSigStartValue" SG_ 2482978624 TipperEmergencyStop_ISig_4 3;
BA_ "GenSigMaxLatency" SG_ 2482978624 TipperEmergencyStop_ISig_4 75;
BA_ "NeedsUpdateBit" SG_ 2482978624 TipperEmergencyStop_ISig_4 1;
BA_ "Platform_VMCU1_Sig" SG_ 2482978624 TipperEmergencyStop_ISig_4 1;
BA_ "GenSigSendType" SG_ 2482978624 TipperTippingBodySelection_UB_IS 7;
BA_ "Platform_VMCU1_Sig" SG_ 2482978624 TipperTippingBodySelection_UB_IS 1;
BA_ "SystemSignalLongSymbol" SG_ 2482978624 TipperTippingBodySelection_UB_IS "TipperTippingBodySelection_UB_ISig_4";
BA_ "GenSigCycleTime" SG_ 2482978624 ExtraBbWrcWatchdog_ISig_4 100;
BA_ "GenSigCycleTimeActive" SG_ 2482978624 ExtraBbWrcWatchdog_ISig_4 100;
BA_ "GenSigStartValue" SG_ 2482978624 ExtraBbWrcWatchdog_ISig_4 3;
BA_ "GenSigMaxLatency" SG_ 2482978624 ExtraBbWrcWatchdog_ISig_4 75;
BA_ "NeedsUpdateBit" SG_ 2482978624 ExtraBbWrcWatchdog_ISig_4 1;
BA_ "Platform_VMCU1_Sig" SG_ 2482978624 ExtraBbWrcWatchdog_ISig_4 1;
BA_ "GenSigSendType" SG_ 2482978624 TipperEmergencyStop_UB_ISig_4 7;
BA_ "Platform_VMCU1_Sig" SG_ 2482978624 TipperEmergencyStop_UB_ISig_4 1;
BA_ "GenSigCycleTime" SG_ 2482978624 AutoFrontWheelDriveDrvReq 100;
BA_ "GenSigCycleTimeActive" SG_ 2482978624 AutoFrontWheelDriveDrvReq 100;
BA_ "GenSigStartValue" SG_ 2482978624 AutoFrontWheelDriveDrvReq 3;
BA_ "Platform_VMCU1_Sig" SG_ 2482978624 AutoFrontWheelDriveDrvReq 1;
BA_ "GenSigCycleTime" SG_ 2482978624 ShortStopHeater_cmd_ISig_4 100;
BA_ "GenSigCycleTimeActive" SG_ 2482978624 ShortStopHeater_cmd_ISig_4 100;
BA_ "GenSigStartValue" SG_ 2482978624 ShortStopHeater_cmd_ISig_4 3;
BA_ "Platform_VMCU1_Sig" SG_ 2482978624 ShortStopHeater_cmd_ISig_4 1;
BA_ "GenSigSendType" SG_ 2482978624 TipperUpDownRequest_UB_ISig_4 7;
BA_ "Platform_VMCU1_Sig" SG_ 2482978624 TipperUpDownRequest_UB_ISig_4 1;
BA_ "GenSigCycleTime" SG_ 2482978624 TailLiftMotionRequest_ISig_4 100;
BA_ "GenSigCycleTimeActive" SG_ 2482978624 TailLiftMotionRequest_ISig_4 100;
BA_ "GenSigStartValue" SG_ 2482978624 TailLiftMotionRequest_ISig_4 7;
BA_ "GenSigMaxLatency" SG_ 2482978624 TailLiftMotionRequest_ISig_4 75;
BA_ "NeedsUpdateBit" SG_ 2482978624 TailLiftMotionRequest_ISig_4 1;
BA_ "Platform_VMCU1_Sig" SG_ 2482978624 TailLiftMotionRequest_ISig_4 1;
BA_ "GenSigCycleTime" SG_ 2482978624 TipperShakerRequest_ISig_4 100;
BA_ "GenSigCycleTimeActive" SG_ 2482978624 TipperShakerRequest_ISig_4 100;
BA_ "GenSigStartValue" SG_ 2482978624 TipperShakerRequest_ISig_4 3;
BA_ "GenSigMaxLatency" SG_ 2482978624 TipperShakerRequest_ISig_4 75;
BA_ "NeedsUpdateBit" SG_ 2482978624 TipperShakerRequest_ISig_4 1;
BA_ "Platform_VMCU1_Sig" SG_ 2482978624 TipperShakerRequest_ISig_4 1;
BA_ "GenSigCycleTime" SG_ 2482978624 TipperTarpaulinRequest_ISig_4 100;
BA_ "GenSigCycleTimeActive" SG_ 2482978624 TipperTarpaulinRequest_ISig_4 100;
BA_ "GenSigStartValue" SG_ 2482978624 TipperTarpaulinRequest_ISig_4 7;
BA_ "GenSigMaxLatency" SG_ 2482978624 TipperTarpaulinRequest_ISig_4 75;
BA_ "NeedsUpdateBit" SG_ 2482978624 TipperTarpaulinRequest_ISig_4 1;
BA_ "Platform_VMCU1_Sig" SG_ 2482978624 TipperTarpaulinRequest_ISig_4 1;
BA_ "GenSigSendType" SG_ 2482978624 ExtraBbWrcWatchdog_UB_ISig_4 7;
BA_ "Platform_VMCU1_Sig" SG_ 2482978624 ExtraBbWrcWatchdog_UB_ISig_4 1;
BA_ "GenSigCycleTime" SG_ 2482978624 ABSInhibitRqstDenied 100;
BA_ "GenSigCycleTimeActive" SG_ 2482978624 ABSInhibitRqstDenied 100;
BA_ "GenSigStartValue" SG_ 2482978624 ABSInhibitRqstDenied 3;
BA_ "GenSigSendType" SG_ 2516513011 DynamicCode_value 1;
BA_ "GenSigStartValue" SG_ 2516513011 DynamicCode_value 4294967295;
BA_ "Platform_VMCU1_Sig" SG_ 2516513011 DynamicCode_value 1;
BA_ "GenSigSendType" SG_ 2499801330 PHTimer_rqst_Hours_ISig_4 1;
BA_ "GenSigCycleTime" SG_ 2499801330 PHTimer_rqst_Hours_ISig_4 100;
BA_ "GenSigCycleTimeActive" SG_ 2499801330 PHTimer_rqst_Hours_ISig_4 100;
BA_ "GenSigStartValue" SG_ 2499801330 PHTimer_rqst_Hours_ISig_4 255;
BA_ "Platform_VMCU1_Sig" SG_ 2499801330 PHTimer_rqst_Hours_ISig_4 1;
BA_ "GenSigSendType" SG_ 2499801330 PHTimer_rqst_Minutes_ISig_4 1;
BA_ "GenSigCycleTime" SG_ 2499801330 PHTimer_rqst_Minutes_ISig_4 100;
BA_ "GenSigCycleTimeActive" SG_ 2499801330 PHTimer_rqst_Minutes_ISig_4 100;
BA_ "GenSigStartValue" SG_ 2499801330 PHTimer_rqst_Minutes_ISig_4 255;
BA_ "Platform_VMCU1_Sig" SG_ 2499801330 PHTimer_rqst_Minutes_ISig_4 1;
BA_ "GenSigSendType" SG_ 2499801330 PHTimer_rqst_SetAlarmOper_ISig_4 1;
BA_ "GenSigCycleTime" SG_ 2499801330 PHTimer_rqst_SetAlarmOper_ISig_4 100;
BA_ "GenSigCycleTimeActive" SG_ 2499801330 PHTimer_rqst_SetAlarmOper_ISig_4 100;
BA_ "GenSigStartValue" SG_ 2499801330 PHTimer_rqst_SetAlarmOper_ISig_4 7;
BA_ "Platform_VMCU1_Sig" SG_ 2499801330 PHTimer_rqst_SetAlarmOper_ISig_4 1;
BA_ "GenSigSendType" SG_ 2499801330 PHTimer_rqst_DayOfWeekRq_ISig_4 1;
BA_ "GenSigCycleTime" SG_ 2499801330 PHTimer_rqst_DayOfWeekRq_ISig_4 100;
BA_ "GenSigCycleTimeActive" SG_ 2499801330 PHTimer_rqst_DayOfWeekRq_ISig_4 100;
BA_ "GenSigStartValue" SG_ 2499801330 PHTimer_rqst_DayOfWeekRq_ISig_4 15;
BA_ "Platform_VMCU1_Sig" SG_ 2499801330 PHTimer_rqst_DayOfWeekRq_ISig_4 1;
BA_ "GenSigSendType" SG_ 2499764033 CIOM_BB2_13S_FCS 7;
BA_ "Platform_VMCU1_Sig" SG_ 2499764033 CIOM_BB2_13S_FCS 1;
BA_ "GenSigSendType" SG_ 2499764032 EngineStartAuth_stat 1;
BA_ "GenSigMaxLatency" SG_ 2499764032 EngineStartAuth_stat 100;
BA_ "Platform_VMCU1_Sig" SG_ 2499764032 EngineStartAuth_stat 1;
BA_ "GenSigSendType" SG_ 2499747649 CIOM_BB2_12S_FCS 7;
BA_ "Platform_VMCU1_Sig" SG_ 2499747649 CIOM_BB2_12S_FCS 1;
BA_ "GenSigSendType" SG_ 2499747648 KeyAuthEncrypted_stat 1;
BA_ "GenSigMaxLatency" SG_ 2499747648 KeyAuthEncrypted_stat 100;
BA_ "Platform_VMCU1_Sig" SG_ 2499747648 KeyAuthEncrypted_stat 1;
BA_ "GenSigCycleTime" SG_ 2498741568 ACCoolingFanSpeedRequest 100;
BA_ "GenSigCycleTimeActive" SG_ 2498741568 ACCoolingFanSpeedRequest 100;
BA_ "GenSigStartValue" SG_ 2498741568 ACCoolingFanSpeedRequest 65535;
BA_ "GenSigMaxLatency" SG_ 2498741568 ACCoolingFanSpeedRequest 110;
BA_ "NeedsUpdateBit" SG_ 2498741568 ACCoolingFanSpeedRequest 1;
BA_ "Platform_VMCU1_Sig" SG_ 2498741568 ACCoolingFanSpeedRequest 1;
BA_ "SeToolAncestorID_SIGNAL" SG_ 2498741568 ACCoolingFanSpeedRequest "x0000001D0425B656";
BA_ "SeToolItemID_SIGNAL" SG_ 2498741568 ACCoolingFanSpeedRequest "x0000001D043C814A";
BA_ "SeToolName_SIGNAL" SG_ 2498741568 ACCoolingFanSpeedRequest "ACCoolingFanSpeedRequest";
BA_ "SeToolVersion_SIGNAL" SG_ 2498741568 ACCoolingFanSpeedRequest "2";
BA_ "GenSigCycleTime" SG_ 2498741568 CabTilt_rqst 100;
BA_ "GenSigCycleTimeActive" SG_ 2498741568 CabTilt_rqst 100;
BA_ "GenSigStartValue" SG_ 2498741568 CabTilt_rqst 3;
BA_ "GenSigMaxLatency" SG_ 2498741568 CabTilt_rqst 110;
BA_ "Platform_VMCU1_Sig" SG_ 2498741568 CabTilt_rqst 1;
BA_ "SeToolAncestorID_SIGNAL" SG_ 2498741568 CabTilt_rqst "x0000001D0416FC9A";
BA_ "SeToolItemID_SIGNAL" SG_ 2498741568 CabTilt_rqst "x0000001D0416FC9A";
BA_ "SeToolName_SIGNAL" SG_ 2498741568 CabTilt_rqst "CabTilt_rqst";
BA_ "SeToolVersion_SIGNAL" SG_ 2498741568 CabTilt_rqst "1";
BA_ "GenSigCycleTime" SG_ 2498741568 Pto3CabRequest 100;
BA_ "GenSigCycleTimeActive" SG_ 2498741568 Pto3CabRequest 100;
BA_ "GenSigStartValue" SG_ 2498741568 Pto3CabRequest 3;
BA_ "GenSigMaxLatency" SG_ 2498741568 Pto3CabRequest 110;
BA_ "Platform_VMCU1_Sig" SG_ 2498741568 Pto3CabRequest 1;
BA_ "SeToolAncestorID_SIGNAL" SG_ 2498741568 Pto3CabRequest "x0000001D0439DD78";
BA_ "SeToolItemID_SIGNAL" SG_ 2498741568 Pto3CabRequest "x0000001D0439DD78";
BA_ "SeToolName_SIGNAL" SG_ 2498741568 Pto3CabRequest "Pto3CabRequest";
BA_ "SeToolVersion_SIGNAL" SG_ 2498741568 Pto3CabRequest "1";
BA_ "GenSigCycleTime" SG_ 2498741568 Pto4CabRequest 100;
BA_ "GenSigCycleTimeActive" SG_ 2498741568 Pto4CabRequest 100;
BA_ "GenSigStartValue" SG_ 2498741568 Pto4CabRequest 3;
BA_ "GenSigMaxLatency" SG_ 2498741568 Pto4CabRequest 110;
BA_ "Platform_VMCU1_Sig" SG_ 2498741568 Pto4CabRequest 1;
BA_ "SeToolAncestorID_SIGNAL" SG_ 2498741568 Pto4CabRequest "x0000001D0439DD7A";
BA_ "SeToolItemID_SIGNAL" SG_ 2498741568 Pto4CabRequest "x0000001D0439DD7A";
BA_ "SeToolName_SIGNAL" SG_ 2498741568 Pto4CabRequest "Pto4CabRequest";
BA_ "SeToolVersion_SIGNAL" SG_ 2498741568 Pto4CabRequest "1";
BA_ "GenSigCycleTime" SG_ 2498741568 WindscreenDefrostInd_cmd_ISig_4 100;
BA_ "GenSigCycleTimeActive" SG_ 2498741568 WindscreenDefrostInd_cmd_ISig_4 100;
BA_ "SeToolAncestorID_SIGNAL" SG_ 2498741568 WindscreenDefrostInd_cmd_ISig_4 "x0000001D04405ABB";
BA_ "SeToolItemID_SIGNAL" SG_ 2498741568 WindscreenDefrostInd_cmd_ISig_4 "x0000001D04405ABB";
BA_ "SeToolName_SIGNAL" SG_ 2498741568 WindscreenDefrostInd_cmd_ISig_4 "WindscreenDefrost_IndicationCmd";
BA_ "SeToolVersion_SIGNAL" SG_ 2498741568 WindscreenDefrostInd_cmd_ISig_4 "1";
BA_ "GenSigSendType" SG_ 2498741568 ACCoolingFanSpeedRequest_UB 7;
BA_ "Platform_VMCU1_Sig" SG_ 2498741568 ACCoolingFanSpeedRequest_UB 1;
BA_ "GenSigCycleTime" SG_ 2498741568 SRSAirbagStatus_ISig_4 100;
BA_ "GenSigCycleTimeActive" SG_ 2498741568 SRSAirbagStatus_ISig_4 100;
BA_ "GenSigStartValue" SG_ 2498741568 SRSAirbagStatus_ISig_4 3;
BA_ "GenSigMaxLatency" SG_ 2498741568 SRSAirbagStatus_ISig_4 110;
BA_ "Platform_VMCU1_Sig" SG_ 2498741568 SRSAirbagStatus_ISig_4 1;
BA_ "SeToolAncestorID_SIGNAL" SG_ 2498741568 SRSAirbagStatus_ISig_4 "x0000001D04147207";
BA_ "SeToolItemID_SIGNAL" SG_ 2498741568 SRSAirbagStatus_ISig_4 "x0000001D042F372C";
BA_ "SeToolName_SIGNAL" SG_ 2498741568 SRSAirbagStatus_ISig_4 "SRSAirbagStatus";
BA_ "SeToolVersion_SIGNAL" SG_ 2498741568 SRSAirbagStatus_ISig_4 "2";
BA_ "GenSigCycleTime" SG_ 2498741568 FrontLidAjar_Stat 100;
BA_ "GenSigCycleTimeActive" SG_ 2498741568 FrontLidAjar_Stat 100;
BA_ "GenSigStartValue" SG_ 2498741568 FrontLidAjar_Stat 3;
BA_ "Platform_VMCU1_Sig" SG_ 2498741568 FrontLidAjar_Stat 1;
BA_ "GenSigCycleTime" SG_ 2498741568 ParkingHeaterCleaning_Rqst_ISig_ 100;
BA_ "GenSigCycleTimeActive" SG_ 2498741568 ParkingHeaterCleaning_Rqst_ISig_ 100;
BA_ "GenSigStartValue" SG_ 2498741568 ParkingHeaterCleaning_Rqst_ISig_ 3;
BA_ "Platform_VMCU1_Sig" SG_ 2498741568 ParkingHeaterCleaning_Rqst_ISig_ 1;
BA_ "SystemSignalLongSymbol" SG_ 2498741568 ParkingHeaterCleaning_Rqst_ISig_ "ParkingHeaterCleaning_Rqst_ISig_4";
BA_ "GenSigCycleTime" SG_ 2498741568 Pto2CabRequest 100;
BA_ "GenSigCycleTimeActive" SG_ 2498741568 Pto2CabRequest 100;
BA_ "GenSigStartValue" SG_ 2498741568 Pto2CabRequest 3;
BA_ "GenSigMaxLatency" SG_ 2498741568 Pto2CabRequest 110;
BA_ "Platform_VMCU1_Sig" SG_ 2498741568 Pto2CabRequest 1;
BA_ "SeToolAncestorID_SIGNAL" SG_ 2498741568 Pto2CabRequest "x0000001D0439DD75";
BA_ "SeToolItemID_SIGNAL" SG_ 2498741568 Pto2CabRequest "x0000001D0439DD75";
BA_ "SeToolName_SIGNAL" SG_ 2498741568 Pto2CabRequest "Pto2CabRequest";
BA_ "SeToolVersion_SIGNAL" SG_ 2498741568 Pto2CabRequest "1";
BA_ "GenSigCycleTime" SG_ 2498741568 SeatSwivelWarning_rqst 100;
BA_ "GenSigCycleTimeActive" SG_ 2498741568 SeatSwivelWarning_rqst 100;
BA_ "GenSigStartValue" SG_ 2498741568 SeatSwivelWarning_rqst 3;
BA_ "GenSigMaxLatency" SG_ 2498741568 SeatSwivelWarning_rqst 110;
BA_ "Platform_VMCU1_Sig" SG_ 2498741568 SeatSwivelWarning_rqst 1;
BA_ "SeToolAncestorID_SIGNAL" SG_ 2498741568 SeatSwivelWarning_rqst "x0000001D0418D487";
BA_ "SeToolItemID_SIGNAL" SG_ 2498741568 SeatSwivelWarning_rqst "x0000001D0418D487";
BA_ "SeToolName_SIGNAL" SG_ 2498741568 SeatSwivelWarning_rqst "SeatSwivelWarning_rqst";
BA_ "SeToolVersion_SIGNAL" SG_ 2498741568 SeatSwivelWarning_rqst "1";
BA_ "GenSigCycleTime" SG_ 2498741568 TemporaryRSLDriverRequest 100;
BA_ "GenSigCycleTimeActive" SG_ 2498741568 TemporaryRSLDriverRequest 100;
BA_ "GenSigStartValue" SG_ 2498741568 TemporaryRSLDriverRequest 3;
BA_ "Platform_VMCU1_Sig" SG_ 2498741568 TemporaryRSLDriverRequest 1;
BA_ "GenSigCycleTime" SG_ 2498741568 Pto1CabRequest 100;
BA_ "GenSigCycleTimeActive" SG_ 2498741568 Pto1CabRequest 100;
BA_ "GenSigStartValue" SG_ 2498741568 Pto1CabRequest 3;
BA_ "GenSigMaxLatency" SG_ 2498741568 Pto1CabRequest 110;
BA_ "Platform_VMCU1_Sig" SG_ 2498741568 Pto1CabRequest 1;
BA_ "SeToolAncestorID_SIGNAL" SG_ 2498741568 Pto1CabRequest "x0000001D0439DD73";
BA_ "SeToolItemID_SIGNAL" SG_ 2498741568 Pto1CabRequest "x0000001D0439DD73";
BA_ "SeToolName_SIGNAL" SG_ 2498741568 Pto1CabRequest "Pto1CabRequest";
BA_ "SeToolVersion_SIGNAL" SG_ 2498741568 Pto1CabRequest "1";
BA_ "GenSigCycleTime" SG_ 2483023936 LCS_EnableSwitch_rqst 100;
BA_ "GenSigCycleTimeActive" SG_ 2483023936 LCS_EnableSwitch_rqst 100;
BA_ "GenSigStartValue" SG_ 2483023936 LCS_EnableSwitch_rqst 3;
BA_ "GenSigMaxLatency" SG_ 2483023936 LCS_EnableSwitch_rqst 68;
BA_ "Platform_VMCU1_Sig" SG_ 2483023936 LCS_EnableSwitch_rqst 1;
BA_ "SeToolAncestorID_SIGNAL" SG_ 2483023936 LCS_EnableSwitch_rqst "x0000001D041691AD";
BA_ "SeToolItemID_SIGNAL" SG_ 2483023936 LCS_EnableSwitch_rqst "x0000001D041691AD";
BA_ "SeToolName_SIGNAL" SG_ 2483023936 LCS_EnableSwitch_rqst "LCS_EnableSwitch_rqst";
BA_ "SeToolVersion_SIGNAL" SG_ 2483023936 LCS_EnableSwitch_rqst "1";
BA_ "GenSigCycleTime" SG_ 2483023936 EscCrossCountryActivation_rqst 100;
BA_ "GenSigCycleTimeActive" SG_ 2483023936 EscCrossCountryActivation_rqst 100;
BA_ "GenSigStartValue" SG_ 2483023936 EscCrossCountryActivation_rqst 3;
BA_ "GenSigMaxLatency" SG_ 2483023936 EscCrossCountryActivation_rqst 68;
BA_ "Platform_VMCU1_Sig" SG_ 2483023936 EscCrossCountryActivation_rqst 1;
BA_ "SeToolAncestorID_SIGNAL" SG_ 2483023936 EscCrossCountryActivation_rqst "x0000001D041B2E58";
BA_ "SeToolItemID_SIGNAL" SG_ 2483023936 EscCrossCountryActivation_rqst "x0000001D041B2E58";
BA_ "SeToolName_SIGNAL" SG_ 2483023936 EscCrossCountryActivation_rqst "EscCrossCountryActivationRequest";
BA_ "SeToolVersion_SIGNAL" SG_ 2483023936 EscCrossCountryActivation_rqst "1";
BA_ "GenSigCycleTime" SG_ 2483023936 StaticCornerLightMode 100;
BA_ "GenSigCycleTimeActive" SG_ 2483023936 StaticCornerLightMode 100;
BA_ "GenSigStartValue" SG_ 2483023936 StaticCornerLightMode 3;
BA_ "Platform_VMCU1_Sig" SG_ 2483023936 StaticCornerLightMode 1;
BA_ "GenSigCycleTime" SG_ 2483023936 SplitBoxDifflockActvnDrvrRqst_IS 100;
BA_ "GenSigCycleTimeActive" SG_ 2483023936 SplitBoxDifflockActvnDrvrRqst_IS 100;
BA_ "GenSigStartValue" SG_ 2483023936 SplitBoxDifflockActvnDrvrRqst_IS 3;
BA_ "NeedsUpdateBit" SG_ 2483023936 SplitBoxDifflockActvnDrvrRqst_IS 1;
BA_ "Platform_VMCU1_Sig" SG_ 2483023936 SplitBoxDifflockActvnDrvrRqst_IS 1;
BA_ "SystemSignalLongSymbol" SG_ 2483023936 SplitBoxDifflockActvnDrvrRqst_IS "SplitBoxDifflockActvnDrvrRqst_ISig_4";
BA_ "GenSigCycleTime" SG_ 2483023936 ATCFrontWheelDriveRequest 100;
BA_ "GenSigCycleTimeActive" SG_ 2483023936 ATCFrontWheelDriveRequest 100;
BA_ "GenSigStartValue" SG_ 2483023936 ATCFrontWheelDriveRequest 3;
BA_ "GenSigCycleTime" SG_ 2483023936 ConstructionSwitch_stat 100;
BA_ "GenSigCycleTimeActive" SG_ 2483023936 ConstructionSwitch_stat 100;
BA_ "GenSigStartValue" SG_ 2483023936 ConstructionSwitch_stat 3;
BA_ "GenSigMaxLatency" SG_ 2483023936 ConstructionSwitch_stat 26;
BA_ "Platform_VMCU1_Sig" SG_ 2483023936 ConstructionSwitch_stat 1;
BA_ "SeToolAncestorID_SIGNAL" SG_ 2483023936 ConstructionSwitch_stat "x0000001D0423C42C";
BA_ "SeToolItemID_SIGNAL" SG_ 2483023936 ConstructionSwitch_stat "x0000001D0423C42C";
BA_ "SeToolName_SIGNAL" SG_ 2483023936 ConstructionSwitch_stat "ConstructionSwitch_stat";
BA_ "SeToolVersion_SIGNAL" SG_ 2483023936 ConstructionSwitch_stat "1";
BA_ "GenSigCycleTime" SG_ 2483023936 EscCabActionRequest 100;
BA_ "GenSigCycleTimeActive" SG_ 2483023936 EscCabActionRequest 100;
BA_ "GenSigStartValue" SG_ 2483023936 EscCabActionRequest 7;
BA_ "GenSigMaxLatency" SG_ 2483023936 EscCabActionRequest 68;
BA_ "Platform_VMCU1_Sig" SG_ 2483023936 EscCabActionRequest 1;
BA_ "SeToolAncestorID_SIGNAL" SG_ 2483023936 EscCabActionRequest "x0000001D044050FA";
BA_ "SeToolItemID_SIGNAL" SG_ 2483023936 EscCabActionRequest "x0000001D044050FA";
BA_ "SeToolName_SIGNAL" SG_ 2483023936 EscCabActionRequest "EscCabActionRequest";
BA_ "SeToolVersion_SIGNAL" SG_ 2483023936 EscCabActionRequest "1";
BA_ "GenSigCycleTime" SG_ 2483023936 AdjustRequestForIdle 100;
BA_ "GenSigCycleTimeActive" SG_ 2483023936 AdjustRequestForIdle 100;
BA_ "GenSigStartValue" SG_ 2483023936 AdjustRequestForIdle 7;
BA_ "GenSigCycleTime" SG_ 2483023936 SCL_LogicPowerOutput_stat 100;
BA_ "GenSigCycleTimeActive" SG_ 2483023936 SCL_LogicPowerOutput_stat 100;
BA_ "GenSigStartValue" SG_ 2483023936 SCL_LogicPowerOutput_stat 3;
BA_ "GenSigMaxLatency" SG_ 2483023936 SCL_LogicPowerOutput_stat 68;
BA_ "Platform_VMCU1_Sig" SG_ 2483023936 SCL_LogicPowerOutput_stat 1;
BA_ "SeToolAncestorID_SIGNAL" SG_ 2483023936 SCL_LogicPowerOutput_stat "x0000001D04184530";
BA_ "SeToolItemID_SIGNAL" SG_ 2483023936 SCL_LogicPowerOutput_stat "x0000001D04184530";
BA_ "SeToolName_SIGNAL" SG_ 2483023936 SCL_LogicPowerOutput_stat "SCL_LogicPowerOutput_stat";
BA_ "SeToolVersion_SIGNAL" SG_ 2483023936 SCL_LogicPowerOutput_stat "1";
BA_ "GenSigCycleTime" SG_ 2483023936 PinCode_validity_time 100;
BA_ "GenSigCycleTimeActive" SG_ 2483023936 PinCode_validity_time 100;
BA_ "GenSigStartValue" SG_ 2483023936 PinCode_validity_time 255;
BA_ "Platform_VMCU1_Sig" SG_ 2483023936 PinCode_validity_time 1;
BA_ "GenSigCycleTime" SG_ 2483023936 StatTrailerBrakeSwitchStatus 100;
BA_ "GenSigCycleTimeActive" SG_ 2483023936 StatTrailerBrakeSwitchStatus 100;
BA_ "GenSigStartValue" SG_ 2483023936 StatTrailerBrakeSwitchStatus 3;
BA_ "Platform_VMCU1_Sig" SG_ 2483023936 StatTrailerBrakeSwitchStatus 1;
BA_ "GenSigSendType" SG_ 2483023936 SplitBoxDifflockActvnDrvrRqst_UB 7;
BA_ "Platform_VMCU1_Sig" SG_ 2483023936 SplitBoxDifflockActvnDrvrRqst_UB 1;
BA_ "SystemSignalLongSymbol" SG_ 2483023936 SplitBoxDifflockActvnDrvrRqst_UB "SplitBoxDifflockActvnDrvrRqst_UB_ISig_4";
BA_ "GenSigCycleTime" SG_ 2483023936 RoofHatch_HMI_rqst 100;
BA_ "GenSigCycleTimeActive" SG_ 2483023936 RoofHatch_HMI_rqst 100;
BA_ "GenSigStartValue" SG_ 2483023936 RoofHatch_HMI_rqst 7;
BA_ "Platform_VMCU1_Sig" SG_ 2483023936 RoofHatch_HMI_rqst 1;
BA_ "GenSigCycleTime" SG_ 2483023936 EscCabEnable 100;
BA_ "GenSigCycleTimeActive" SG_ 2483023936 EscCabEnable 100;
BA_ "GenSigStartValue" SG_ 2483023936 EscCabEnable 3;
BA_ "GenSigMaxLatency" SG_ 2483023936 EscCabEnable 68;
BA_ "Platform_VMCU1_Sig" SG_ 2483023936 EscCabEnable 1;
BA_ "SeToolAncestorID_SIGNAL" SG_ 2483023936 EscCabEnable "x0000001D043DFB25";
BA_ "SeToolItemID_SIGNAL" SG_ 2483023936 EscCabEnable "x0000001D043DFB25";
BA_ "SeToolName_SIGNAL" SG_ 2483023936 EscCabEnable "EscCabEnable";
BA_ "SeToolVersion_SIGNAL" SG_ 2483023936 EscCabEnable "1";
BA_ "GenSigCycleTime" SG_ 2483023936 ExtraSideMarkers_Rqst 100;
BA_ "GenSigCycleTimeActive" SG_ 2483023936 ExtraSideMarkers_Rqst 100;
BA_ "GenSigStartValue" SG_ 2483023936 ExtraSideMarkers_Rqst 3;
BA_ "Platform_VMCU1_Sig" SG_ 2483023936 ExtraSideMarkers_Rqst 1;
BA_ "GenSigCycleTime" SG_ 2483023936 LevelingThumbwheel_stat 100;
BA_ "GenSigCycleTimeActive" SG_ 2483023936 LevelingThumbwheel_stat 100;
BA_ "GenSigStartValue" SG_ 2483023936 LevelingThumbwheel_stat 31;
BA_ "Platform_VMCU1_Sig" SG_ 2483023936 LevelingThumbwheel_stat 1;
BA_ "GenSigCycleTime" SG_ 2483023936 DASActivation_rqst 100;
BA_ "GenSigCycleTimeActive" SG_ 2483023936 DASActivation_rqst 100;
BA_ "GenSigStartValue" SG_ 2483023936 DASActivation_rqst 3;
BA_ "GenSigMaxLatency" SG_ 2483023936 DASActivation_rqst 68;
BA_ "Platform_VMCU1_Sig" SG_ 2483023936 DASActivation_rqst 1;
BA_ "SeToolAncestorID_SIGNAL" SG_ 2483023936 DASActivation_rqst "x0000001D04169A8A";
BA_ "SeToolItemID_SIGNAL" SG_ 2483023936 DASActivation_rqst "x0000001D04290712";
BA_ "SeToolName_SIGNAL" SG_ 2483023936 DASActivation_rqst "DASActivation_rqst";
BA_ "SeToolVersion_SIGNAL" SG_ 2483023936 DASActivation_rqst "2";
BA_ "GenSigCycleTime" SG_ 2483023936 DriverSeatBeltSwitch_ISig_4 100;
BA_ "GenSigCycleTimeActive" SG_ 2483023936 DriverSeatBeltSwitch_ISig_4 100;
BA_ "GenSigStartValue" SG_ 2483023936 DriverSeatBeltSwitch_ISig_4 3;
BA_ "GenSigMaxLatency" SG_ 2483023936 DriverSeatBeltSwitch_ISig_4 68;
BA_ "Platform_VMCU1_Sig" SG_ 2483023936 DriverSeatBeltSwitch_ISig_4 1;
BA_ "SeToolAncestorID_SIGNAL" SG_ 2483023936 DriverSeatBeltSwitch_ISig_4 "x0000001D0412FE94";
BA_ "SeToolItemID_SIGNAL" SG_ 2483023936 DriverSeatBeltSwitch_ISig_4 "x0000001D0412FE94";
BA_ "SeToolName_SIGNAL" SG_ 2483023936 DriverSeatBeltSwitch_ISig_4 "DriverSeatBeltSwitch";
BA_ "SeToolVersion_SIGNAL" SG_ 2483023936 DriverSeatBeltSwitch_ISig_4 "1";
BA_ "GenSigCycleTime" SG_ 2483023936 PinCode_stat 100;
BA_ "GenSigCycleTimeActive" SG_ 2483023936 PinCode_stat 100;
BA_ "GenSigStartValue" SG_ 2483023936 PinCode_stat 7;
BA_ "Platform_VMCU1_Sig" SG_ 2483023936 PinCode_stat 1;
BA_ "GenSigCycleTime" SG_ 2483023936 WarmUp_Request 100;
BA_ "GenSigCycleTimeActive" SG_ 2483023936 WarmUp_Request 100;
BA_ "GenSigStartValue" SG_ 2483023936 WarmUp_Request 3;
BA_ "Platform_VMCU1_Sig" SG_ 2483023936 WarmUp_Request 1;
BA_ "GenSigCycleTime" SG_ 2483023936 LKSEnableSwitch_rqst 100;
BA_ "GenSigCycleTimeActive" SG_ 2483023936 LKSEnableSwitch_rqst 100;
BA_ "GenSigStartValue" SG_ 2483023936 LKSEnableSwitch_rqst 3;
BA_ "GenSigMaxLatency" SG_ 2483023936 LKSEnableSwitch_rqst 68;
BA_ "Platform_VMCU1_Sig" SG_ 2483023936 LKSEnableSwitch_rqst 1;
BA_ "SeToolAncestorID_SIGNAL" SG_ 2483023936 LKSEnableSwitch_rqst "x0000001D04158E2E";
BA_ "SeToolItemID_SIGNAL" SG_ 2483023936 LKSEnableSwitch_rqst "x0000001D04158E2E";
BA_ "SeToolName_SIGNAL" SG_ 2483023936 LKSEnableSwitch_rqst "LKSEnableSwitch_rqst";
BA_ "SeToolVersion_SIGNAL" SG_ 2483023936 LKSEnableSwitch_rqst "1";
BA_ "GenSigCycleTime" SG_ 2515579712 AlmClkSnze_LECM_rqst_ID_ISig_4 100;
BA_ "GenSigCycleTimeActive" SG_ 2515579712 AlmClkSnze_LECM_rqst_ID_ISig_4 100;
BA_ "GenSigStartValue" SG_ 2515579712 AlmClkSnze_LECM_rqst_ID_ISig_4 127;
BA_ "Platform_VMCU1_Sig" SG_ 2515579712 AlmClkSnze_LECM_rqst_ID_ISig_4 1;
BA_ "GenSigCycleTime" SG_ 2515579712 AlmClkSetCurAlm_rqst_ID 100;
BA_ "GenSigCycleTimeActive" SG_ 2515579712 AlmClkSetCurAlm_rqst_ID 100;
BA_ "GenSigStartValue" SG_ 2515579712 AlmClkSetCurAlm_rqst_ID 127;
BA_ "Platform_VMCU1_Sig" SG_ 2515579712 AlmClkSetCurAlm_rqst_ID 1;
BA_ "GenSigCycleTime" SG_ 2515579712 AlmClkSnze_LECM_rqst_Action_ISig 100;
BA_ "GenSigCycleTimeActive" SG_ 2515579712 AlmClkSnze_LECM_rqst_Action_ISig 100;
BA_ "GenSigStartValue" SG_ 2515579712 AlmClkSnze_LECM_rqst_Action_ISig 7;
BA_ "Platform_VMCU1_Sig" SG_ 2515579712 AlmClkSnze_LECM_rqst_Action_ISig 1;
BA_ "SystemSignalLongSymbol" SG_ 2515579712 AlmClkSnze_LECM_rqst_Action_ISig "AlmClkSnze_LECM_rqst_Action_ISig_4";
BA_ "GenSigCycleTime" SG_ 2515579712 AlmClkSetCurAlm_rqst_Stat 100;
BA_ "GenSigCycleTimeActive" SG_ 2515579712 AlmClkSetCurAlm_rqst_Stat 100;
BA_ "GenSigStartValue" SG_ 2515579712 AlmClkSetCurAlm_rqst_Stat 3;
BA_ "Platform_VMCU1_Sig" SG_ 2515579712 AlmClkSetCurAlm_rqst_Stat 1;
BA_ "GenSigCycleTime" SG_ 2515579712 AlmClkSetCurAlm_rqst_SetMin 100;
BA_ "GenSigCycleTimeActive" SG_ 2515579712 AlmClkSetCurAlm_rqst_SetMin 100;
BA_ "GenSigStartValue" SG_ 2515579712 AlmClkSetCurAlm_rqst_SetMin 63;
BA_ "Platform_VMCU1_Sig" SG_ 2515579712 AlmClkSetCurAlm_rqst_SetMin 1;
BA_ "GenSigCycleTime" SG_ 2515579712 AlmClkSetCurAlm_rqst_SetHr 100;
BA_ "GenSigCycleTimeActive" SG_ 2515579712 AlmClkSetCurAlm_rqst_SetHr 100;
BA_ "GenSigStartValue" SG_ 2515579712 AlmClkSetCurAlm_rqst_SetHr 31;
BA_ "Platform_VMCU1_Sig" SG_ 2515579712 AlmClkSetCurAlm_rqst_SetHr 1;
BA_ "GenSigCycleTime" SG_ 2515579712 CollSituationHMICtrlRequestVM 100;
BA_ "GenSigCycleTimeActive" SG_ 2515579712 CollSituationHMICtrlRequestVM 100;
BA_ "GenSigStartValue" SG_ 2515579712 CollSituationHMICtrlRequestVM 7;
BA_ "Platform_VMCU1_Sig" SG_ 2515579712 CollSituationHMICtrlRequestVM 1;
BA_ "GenSigCycleTime" SG_ 2515579712 AcCoolantPumpEngagementRequest_I 100;
BA_ "GenSigCycleTimeActive" SG_ 2515579712 AcCoolantPumpEngagementRequest_I 100;
BA_ "GenSigStartValue" SG_ 2515579712 AcCoolantPumpEngagementRequest_I 255;
BA_ "Platform_VMCU1_Sig" SG_ 2515579712 AcCoolantPumpEngagementRequest_I 1;
BA_ "SystemSignalLongSymbol" SG_ 2515579712 AcCoolantPumpEngagementRequest_I "AcCoolantPumpEngagementRequest_ISig_4";
BA_ "GenSigCycleTime" SG_ 2515579712 AlmClkSetCurAlm_rqst_Type 100;
BA_ "GenSigCycleTimeActive" SG_ 2515579712 AlmClkSetCurAlm_rqst_Type 100;
BA_ "GenSigStartValue" SG_ 2515579712 AlmClkSetCurAlm_rqst_Type 7;
BA_ "Platform_VMCU1_Sig" SG_ 2515579712 AlmClkSetCurAlm_rqst_Type 1;
BA_ "GenSigCycleTime" SG_ 2515579712 WRC_Docking_stat_ISig_4 100;
BA_ "GenSigCycleTimeActive" SG_ 2515579712 WRC_Docking_stat_ISig_4 100;
BA_ "GenSigStartValue" SG_ 2515579712 WRC_Docking_stat_ISig_4 3;
BA_ "Platform_VMCU1_Sig" SG_ 2515579712 WRC_Docking_stat_ISig_4 1;
BA_ "GenSigSendType" SG_ 2482995008 LiftAxle1DirectControl_UB_ISig_4 7;
BA_ "Platform_VMCU1_Sig" SG_ 2482995008 LiftAxle1DirectControl_UB_ISig_4 1;
BA_ "GenSigCycleTime" SG_ 2482995008 MirrorSelectRightMainBtn_stat_IS 100;
BA_ "GenSigCycleTimeActive" SG_ 2482995008 MirrorSelectRightMainBtn_stat_IS 100;
BA_ "GenSigStartValue" SG_ 2482995008 MirrorSelectRightMainBtn_stat_IS 3;
BA_ "GenSigMaxLatency" SG_ 2482995008 MirrorSelectRightMainBtn_stat_IS 66;
BA_ "Platform_VMCU1_Sig" SG_ 2482995008 MirrorSelectRightMainBtn_stat_IS 1;
BA_ "SeToolAncestorID_SIGNAL" SG_ 2482995008 MirrorSelectRightMainBtn_stat_IS "x0000001D0423D932";
BA_ "SeToolItemID_SIGNAL" SG_ 2482995008 MirrorSelectRightMainBtn_stat_IS "x0000001D0429669B";
BA_ "SeToolName_SIGNAL" SG_ 2482995008 MirrorSelectRightMainBtn_stat_IS "EM_MirrorselectRightMain_ButtonStatus";
BA_ "SeToolVersion_SIGNAL" SG_ 2482995008 MirrorSelectRightMainBtn_stat_IS "4";
BA_ "SystemSignalLongSymbol" SG_ 2482995008 MirrorSelectRightMainBtn_stat_IS "MirrorSelectRightMainBtn_stat_ISig_4";
BA_ "GenSigCycleTime" SG_ 2482995008 WRCEngineStopRequest_ISig_4 100;
BA_ "GenSigCycleTimeActive" SG_ 2482995008 WRCEngineStopRequest_ISig_4 100;
BA_ "GenSigStartValue" SG_ 2482995008 WRCEngineStopRequest_ISig_4 3;
BA_ "GenSigMaxLatency" SG_ 2482995008 WRCEngineStopRequest_ISig_4 28;
BA_ "NeedsUpdateBit" SG_ 2482995008 WRCEngineStopRequest_ISig_4 1;
BA_ "Platform_VMCU1_Sig" SG_ 2482995008 WRCEngineStopRequest_ISig_4 1;
BA_ "GenSigCycleTime" SG_ 2482995008 LiftAxle1DirectControl_ISig_4 100;
BA_ "GenSigCycleTimeActive" SG_ 2482995008 LiftAxle1DirectControl_ISig_4 100;
BA_ "GenSigStartValue" SG_ 2482995008 LiftAxle1DirectControl_ISig_4 7;
BA_ "NeedsUpdateBit" SG_ 2482995008 LiftAxle1DirectControl_ISig_4 1;
BA_ "Platform_VMCU1_Sig" SG_ 2482995008 LiftAxle1DirectControl_ISig_4 1;
BA_ "GenSigCycleTime" SG_ 2482995008 MirrorSelectRightWideBtn_stat_IS 100;
BA_ "GenSigCycleTimeActive" SG_ 2482995008 MirrorSelectRightWideBtn_stat_IS 100;
BA_ "GenSigStartValue" SG_ 2482995008 MirrorSelectRightWideBtn_stat_IS 3;
BA_ "GenSigMaxLatency" SG_ 2482995008 MirrorSelectRightWideBtn_stat_IS 66;
BA_ "Platform_VMCU1_Sig" SG_ 2482995008 MirrorSelectRightWideBtn_stat_IS 1;
BA_ "SeToolAncestorID_SIGNAL" SG_ 2482995008 MirrorSelectRightWideBtn_stat_IS "x0000001D0423D932";
BA_ "SeToolItemID_SIGNAL" SG_ 2482995008 MirrorSelectRightWideBtn_stat_IS "x0000001D0429669B";
BA_ "SeToolName_SIGNAL" SG_ 2482995008 MirrorSelectRightWideBtn_stat_IS "EM_MirrorselectRightWide_ButtonStatus";
BA_ "SeToolVersion_SIGNAL" SG_ 2482995008 MirrorSelectRightWideBtn_stat_IS "4";
BA_ "SystemSignalLongSymbol" SG_ 2482995008 MirrorSelectRightWideBtn_stat_IS "MirrorSelectRightWideBtn_stat_ISig_4";
BA_ "GenSigCycleTime" SG_ 2482995008 PanicAlarmFromKeyfob_rqst 100;
BA_ "GenSigCycleTimeActive" SG_ 2482995008 PanicAlarmFromKeyfob_rqst 100;
BA_ "GenSigStartValue" SG_ 2482995008 PanicAlarmFromKeyfob_rqst 3;
BA_ "GenSigMaxLatency" SG_ 2482995008 PanicAlarmFromKeyfob_rqst 66;
BA_ "Platform_VMCU1_Sig" SG_ 2482995008 PanicAlarmFromKeyfob_rqst 1;
BA_ "GenSigCycleTime" SG_ 2482995008 ParkingClimate_IndicationCmd_ISi 100;
BA_ "GenSigCycleTimeActive" SG_ 2482995008 ParkingClimate_IndicationCmd_ISi 100;
BA_ "GenSigStartValue" SG_ 2482995008 ParkingClimate_IndicationCmd_ISi 7;
BA_ "Platform_VMCU1_Sig" SG_ 2482995008 ParkingClimate_IndicationCmd_ISi 1;
BA_ "SystemSignalLongSymbol" SG_ 2482995008 ParkingClimate_IndicationCmd_ISi "ParkingClimate_IndicationCmd_ISig_4";
BA_ "GenSigCycleTime" SG_ 2482995008 MirrorSelectLeftWideBtn_stat_ISi 100;
BA_ "GenSigCycleTimeActive" SG_ 2482995008 MirrorSelectLeftWideBtn_stat_ISi 100;
BA_ "GenSigStartValue" SG_ 2482995008 MirrorSelectLeftWideBtn_stat_ISi 3;
BA_ "GenSigMaxLatency" SG_ 2482995008 MirrorSelectLeftWideBtn_stat_ISi 66;
BA_ "Platform_VMCU1_Sig" SG_ 2482995008 MirrorSelectLeftWideBtn_stat_ISi 1;
BA_ "SeToolAncestorID_SIGNAL" SG_ 2482995008 MirrorSelectLeftWideBtn_stat_ISi "x0000001D0423D932";
BA_ "SeToolItemID_SIGNAL" SG_ 2482995008 MirrorSelectLeftWideBtn_stat_ISi "x0000001D0429669B";
BA_ "SeToolName_SIGNAL" SG_ 2482995008 MirrorSelectLeftWideBtn_stat_ISi "EM_MirrorselectLeftWide_ButtonStatus";
BA_ "SeToolVersion_SIGNAL" SG_ 2482995008 MirrorSelectLeftWideBtn_stat_ISi "4";
BA_ "SystemSignalLongSymbol" SG_ 2482995008 MirrorSelectLeftWideBtn_stat_ISi "MirrorSelectLeftWideBtn_stat_ISig_4";
BA_ "GenSigCycleTime" SG_ 2482995008 WRCEngineStartRequest_ISig_4 100;
BA_ "GenSigCycleTimeActive" SG_ 2482995008 WRCEngineStartRequest_ISig_4 100;
BA_ "GenSigStartValue" SG_ 2482995008 WRCEngineStartRequest_ISig_4 3;
BA_ "GenSigMaxLatency" SG_ 2482995008 WRCEngineStartRequest_ISig_4 28;
BA_ "NeedsUpdateBit" SG_ 2482995008 WRCEngineStartRequest_ISig_4 1;
BA_ "Platform_VMCU1_Sig" SG_ 2482995008 WRCEngineStartRequest_ISig_4 1;
BA_ "GenSigCycleTime" SG_ 2482995008 PW_Left_DS_SwStatus_ISig_4 100;
BA_ "GenSigCycleTimeActive" SG_ 2482995008 PW_Left_DS_SwStatus_ISig_4 100;
BA_ "GenSigStartValue" SG_ 2482995008 PW_Left_DS_SwStatus_ISig_4 7;
BA_ "GenSigMaxLatency" SG_ 2482995008 PW_Left_DS_SwStatus_ISig_4 66;
BA_ "Platform_VMCU1_Sig" SG_ 2482995008 PW_Left_DS_SwStatus_ISig_4 1;
BA_ "GenSigCycleTime" SG_ 2482995008 RegenerationSwitchStatus 100;
BA_ "GenSigCycleTimeActive" SG_ 2482995008 RegenerationSwitchStatus 100;
BA_ "GenSigStartValue" SG_ 2482995008 RegenerationSwitchStatus 7;
BA_ "Platform_VMCU1_Sig" SG_ 2482995008 RegenerationSwitchStatus 1;
BA_ "GenSigCycleTime" SG_ 2482995008 PW_Right_DS_SwStatus_ISig_4 100;
BA_ "GenSigCycleTimeActive" SG_ 2482995008 PW_Right_DS_SwStatus_ISig_4 100;
BA_ "GenSigStartValue" SG_ 2482995008 PW_Right_DS_SwStatus_ISig_4 7;
BA_ "GenSigMaxLatency" SG_ 2482995008 PW_Right_DS_SwStatus_ISig_4 66;
BA_ "Platform_VMCU1_Sig" SG_ 2482995008 PW_Right_DS_SwStatus_ISig_4 1;
BA_ "GenSigCycleTime" SG_ 2482995008 DoorLock_stat_ISig_4 100;
BA_ "GenSigCycleTimeActive" SG_ 2482995008 DoorLock_stat_ISig_4 100;
BA_ "GenSigStartValue" SG_ 2482995008 DoorLock_stat_ISig_4 15;
BA_ "GenSigMaxLatency" SG_ 2482995008 DoorLock_stat_ISig_4 66;
BA_ "Platform_VMCU1_Sig" SG_ 2482995008 DoorLock_stat_ISig_4 1;
BA_ "GenSigSendType" SG_ 2482995008 WRCEngineStartRequest_UB_ISig_4 7;
BA_ "Platform_VMCU1_Sig" SG_ 2482995008 WRCEngineStartRequest_UB_ISig_4 1;
BA_ "GenSigCycleTime" SG_ 2482995008 LuggageAjar_stat 100;
BA_ "GenSigCycleTimeActive" SG_ 2482995008 LuggageAjar_stat 100;
BA_ "GenSigStartValue" SG_ 2482995008 LuggageAjar_stat 7;
BA_ "Platform_VMCU1_Sig" SG_ 2482995008 LuggageAjar_stat 1;
BA_ "GenSigCycleTime" SG_ 2482995008 AlarmStatus_stat_ISig_4 100;
BA_ "GenSigCycleTimeActive" SG_ 2482995008 AlarmStatus_stat_ISig_4 100;
BA_ "GenSigStartValue" SG_ 2482995008 AlarmStatus_stat_ISig_4 15;
BA_ "Platform_VMCU1_Sig" SG_ 2482995008 AlarmStatus_stat_ISig_4 1;
BA_ "GenSigCycleTime" SG_ 2482995008 AlarmTriggeringCause_stat_ISig_4 100;
BA_ "GenSigCycleTimeActive" SG_ 2482995008 AlarmTriggeringCause_stat_ISig_4 100;
BA_ "GenSigStartValue" SG_ 2482995008 AlarmTriggeringCause_stat_ISig_4 15;
BA_ "GenSigMaxLatency" SG_ 2482995008 AlarmTriggeringCause_stat_ISig_4 66;
BA_ "Platform_VMCU1_Sig" SG_ 2482995008 AlarmTriggeringCause_stat_ISig_4 1;
BA_ "GenSigSendType" SG_ 2482995008 DoorsAjar_stat_UB_ISig_4 7;
BA_ "Platform_VMCU1_Sig" SG_ 2482995008 DoorsAjar_stat_UB_ISig_4 1;
BA_ "GenSigCycleTime" SG_ 2482995008 DoorsAjar_stat_ISig_4 100;
BA_ "GenSigCycleTimeActive" SG_ 2482995008 DoorsAjar_stat_ISig_4 100;
BA_ "GenSigStartValue" SG_ 2482995008 DoorsAjar_stat_ISig_4 7;
BA_ "GenSigMaxLatency" SG_ 2482995008 DoorsAjar_stat_ISig_4 66;
BA_ "NeedsUpdateBit" SG_ 2482995008 DoorsAjar_stat_ISig_4 1;
BA_ "Platform_VMCU1_Sig" SG_ 2482995008 DoorsAjar_stat_ISig_4 1;
BA_ "GenSigSendType" SG_ 2482995008 WRCEngineStopRequest_UB_ISig_4 7;
BA_ "Platform_VMCU1_Sig" SG_ 2482995008 WRCEngineStopRequest_UB_ISig_4 1;
BA_ "GenSigCycleTime" SG_ 2482995008 DoorAutoFunction_rqst 100;
BA_ "GenSigCycleTimeActive" SG_ 2482995008 DoorAutoFunction_rqst 100;
BA_ "GenSigStartValue" SG_ 2482995008 DoorAutoFunction_rqst 3;
BA_ "GenSigMaxLatency" SG_ 2482995008 DoorAutoFunction_rqst 66;
BA_ "Platform_VMCU1_Sig" SG_ 2482995008 DoorAutoFunction_rqst 1;
BA_ "GenSigCycleTime" SG_ 2482995008 MirrorSelectLeftMainBtn_stat_ISi 100;
BA_ "GenSigCycleTimeActive" SG_ 2482995008 MirrorSelectLeftMainBtn_stat_ISi 100;
BA_ "GenSigStartValue" SG_ 2482995008 MirrorSelectLeftMainBtn_stat_ISi 3;
BA_ "GenSigMaxLatency" SG_ 2482995008 MirrorSelectLeftMainBtn_stat_ISi 66;
BA_ "Platform_VMCU1_Sig" SG_ 2482995008 MirrorSelectLeftMainBtn_stat_ISi 1;
BA_ "SeToolAncestorID_SIGNAL" SG_ 2482995008 MirrorSelectLeftMainBtn_stat_ISi "x0000001D0423D932";
BA_ "SeToolItemID_SIGNAL" SG_ 2482995008 MirrorSelectLeftMainBtn_stat_ISi "x0000001D0429669B";
BA_ "SeToolName_SIGNAL" SG_ 2482995008 MirrorSelectLeftMainBtn_stat_ISi "EM_MirrorselectLeftMain_ButtonStatus";
BA_ "SeToolVersion_SIGNAL" SG_ 2482995008 MirrorSelectLeftMainBtn_stat_ISi "4";
BA_ "SystemSignalLongSymbol" SG_ 2482995008 MirrorSelectLeftMainBtn_stat_ISi "MirrorSelectLeftMainBtn_stat_ISig_4";
BA_REL_ "GenSigFirstTimeoutTime" BU_SG_REL_ IC3 SG_ 2147485152 DiagFaultStat_Alarm_DtcIdA_ISig_ 24000;
BA_REL_ "GenSigTimeoutTime" BU_SG_REL_ IC3 SG_ 2147485152 DiagFaultStat_Alarm_DtcIdA_ISig_ 6000;
BA_REL_ "GenSigFirstTimeoutTime" BU_SG_REL_ IC3 SG_ 2147485152 DiagFaultStat_Alarm_EcuAdr_ISig_ 24000;
BA_REL_ "GenSigTimeoutTime" BU_SG_REL_ IC3 SG_ 2147485152 DiagFaultStat_Alarm_EcuAdr_ISig_ 6000;
BA_REL_ "GenSigFirstTimeoutTime" BU_SG_REL_ IC3 SG_ 2147485152 DiagFaultStat_Alarm_FailTB_ISig_ 24000;
BA_REL_ "GenSigTimeoutTime" BU_SG_REL_ IC3 SG_ 2147485152 DiagFaultStat_Alarm_FailTB_ISig_ 6000;
BA_REL_ "GenSigFirstTimeoutTime" BU_SG_REL_ IC3 SG_ 2147485152 DiagFaultStat_Alarm_FailTA_ISig_ 24000;
BA_REL_ "GenSigTimeoutTime" BU_SG_REL_ IC3 SG_ 2147485152 DiagFaultStat_Alarm_FailTA_ISig_ 6000;
BA_REL_ "GenSigFirstTimeoutTime" BU_SG_REL_ IC3 SG_ 2147485152 DiagFaultStat_Alarm_DtcIdB_ISig_ 24000;
BA_REL_ "GenSigTimeoutTime" BU_SG_REL_ IC3 SG_ 2147485152 DiagFaultStat_Alarm_DtcIdB_ISig_ 6000;
BA_REL_ "GenSigFirstTimeoutTime" BU_SG_REL_ IC3 SG_ 2147485137 DiagFaultStat_APM_DtcIdA_ISig_4 12000;
BA_REL_ "GenSigTimeoutTime" BU_SG_REL_ IC3 SG_ 2147485137 DiagFaultStat_APM_DtcIdA_ISig_4 3000;
BA_REL_ "GenSigFirstTimeoutTime" BU_SG_REL_ IC3 SG_ 2147485137 DiagFaultStat_APM_EcuAdr_ISig_4 12000;
BA_REL_ "GenSigTimeoutTime" BU_SG_REL_ IC3 SG_ 2147485137 DiagFaultStat_APM_EcuAdr_ISig_4 3000;
BA_REL_ "GenSigFirstTimeoutTime" BU_SG_REL_ IC3 SG_ 2147485137 DiagFaultStat_APM_FailTB_ISig_4 12000;
BA_REL_ "GenSigTimeoutTime" BU_SG_REL_ IC3 SG_ 2147485137 DiagFaultStat_APM_FailTB_ISig_4 3000;
BA_REL_ "GenSigFirstTimeoutTime" BU_SG_REL_ IC3 SG_ 2147485137 DiagFaultStat_APM_DtcIdB_ISig_4 12000;
BA_REL_ "GenSigTimeoutTime" BU_SG_REL_ IC3 SG_ 2147485137 DiagFaultStat_APM_DtcIdB_ISig_4 3000;
BA_REL_ "GenSigFirstTimeoutTime" BU_SG_REL_ IC3 SG_ 2147485137 DiagFaultStat_APM_FailTA_ISig_4 12000;
BA_REL_ "GenSigTimeoutTime" BU_SG_REL_ IC3 SG_ 2147485137 DiagFaultStat_APM_FailTA_ISig_4 3000;
BA_REL_ "GenSigTimeoutTime" BU_SG_REL_ ECUspare1 SG_ 1964 Debug_PVT_SCIM_Task7_Time 200;
BA_REL_ "GenSigFirstTimeoutTime" BU_SG_REL_ ECUspare1 SG_ 1964 Debug_PVT_SCIM_Task7_Time 1500;
BA_REL_ "GenSigTimeoutTime" BU_SG_REL_ ECUspare1 SG_ 1964 Debug_PVT_SCIM_Task6_Time 200;
BA_REL_ "GenSigFirstTimeoutTime" BU_SG_REL_ ECUspare1 SG_ 1964 Debug_PVT_SCIM_Task6_Time 1500;
BA_REL_ "GenSigTimeoutTime" BU_SG_REL_ ECUspare1 SG_ 1964 Debug_PVT_SCIM_Task5_Time 200;
BA_REL_ "GenSigFirstTimeoutTime" BU_SG_REL_ ECUspare1 SG_ 1964 Debug_PVT_SCIM_Task5_Time 1500;
BA_REL_ "GenSigTimeoutTime" BU_SG_REL_ ECUspare1 SG_ 1964 Debug_PVT_SCIM_Task4_Time 200;
BA_REL_ "GenSigFirstTimeoutTime" BU_SG_REL_ ECUspare1 SG_ 1964 Debug_PVT_SCIM_Task4_Time 1500;
BA_REL_ "GenSigTimeoutTime" BU_SG_REL_ ECUspare1 SG_ 1964 Debug_PVT_SCIM_Task3_Time 200;
BA_REL_ "GenSigFirstTimeoutTime" BU_SG_REL_ ECUspare1 SG_ 1964 Debug_PVT_SCIM_Task3_Time 1500;
BA_REL_ "GenSigTimeoutTime" BU_SG_REL_ ECUspare1 SG_ 1964 Debug_PVT_SCIM_Task2_Time 200;
BA_REL_ "GenSigFirstTimeoutTime" BU_SG_REL_ ECUspare1 SG_ 1964 Debug_PVT_SCIM_Task2_Time 1500;
BA_REL_ "GenSigFirstTimeoutTime" BU_SG_REL_ ECUspare1 SG_ 1964 Debug_PVT_SCIM_Task1_Time 1500;
BA_REL_ "GenSigTimeoutTime" BU_SG_REL_ ECUspare1 SG_ 1964 Debug_PVT_SCIM_Task1_Time 200;
BA_REL_ "GenSigTimeoutTime" BU_SG_REL_ ECUspare1 SG_ 1957 Debug_PVT_SCIM_TSinceWkUp_Short 200;
BA_REL_ "GenSigFirstTimeoutTime" BU_SG_REL_ ECUspare1 SG_ 1957 Debug_PVT_SCIM_TSinceWkUp_Short 1500;
BA_REL_ "GenSigTimeoutTime" BU_SG_REL_ ECUspare1 SG_ 1957 Debug_PVT_SCIM_TSincePwrOn_Short 200;
BA_REL_ "GenSigFirstTimeoutTime" BU_SG_REL_ ECUspare1 SG_ 1957 Debug_PVT_SCIM_TSincePwrOn_Short 1500;
BA_REL_ "GenSigTimeoutTime" BU_SG_REL_ ECUspare1 SG_ 1957 Debug_PVT_SCIM_TSincePwrOn_Long 200;
BA_REL_ "GenSigFirstTimeoutTime" BU_SG_REL_ ECUspare1 SG_ 1957 Debug_PVT_SCIM_TSincePwrOn_Long 1500;
BA_REL_ "GenSigTimeoutTime" BU_SG_REL_ ECUspare1 SG_ 1950 Debug_PVT_SCIM_RF_Button2_Time 200;
BA_REL_ "GenSigFirstTimeoutTime" BU_SG_REL_ ECUspare1 SG_ 1950 Debug_PVT_SCIM_RF_Button2_Time 1500;
BA_REL_ "GenSigTimeoutTime" BU_SG_REL_ ECUspare1 SG_ 1950 Debug_PVT_SCIM_RF_Button2_ID 200;
BA_REL_ "GenSigFirstTimeoutTime" BU_SG_REL_ ECUspare1 SG_ 1950 Debug_PVT_SCIM_RF_Button2_ID 1500;
BA_REL_ "GenSigTimeoutTime" BU_SG_REL_ ECUspare1 SG_ 1950 Debug_PVT_SCIM_RF_Button1_Time 200;
BA_REL_ "GenSigFirstTimeoutTime" BU_SG_REL_ ECUspare1 SG_ 1950 Debug_PVT_SCIM_RF_Button1_Time 1500;
BA_REL_ "GenSigTimeoutTime" BU_SG_REL_ ECUspare1 SG_ 1950 Debug_PVT_SCIM_RF_Button1_ID 200;
BA_REL_ "GenSigFirstTimeoutTime" BU_SG_REL_ ECUspare1 SG_ 1950 Debug_PVT_SCIM_RF_Button1_ID 1500;
BA_REL_ "GenSigTimeoutTime" BU_SG_REL_ ECUspare1 SG_ 1950 Debug_PVT_SCIM_RF_BtnPressIndex 200;
BA_REL_ "GenSigFirstTimeoutTime" BU_SG_REL_ ECUspare1 SG_ 1950 Debug_PVT_SCIM_RF_BtnPressIndex 1500;
BA_REL_ "GenSigTimeoutTime" BU_SG_REL_ ECUspare1 SG_ 1950 Debug_PVT_SCIM_RF_BAT 200;
BA_REL_ "GenSigFirstTimeoutTime" BU_SG_REL_ ECUspare1 SG_ 1950 Debug_PVT_SCIM_RF_BAT 1500;
BA_REL_ "GenSigTimeoutTime" BU_SG_REL_ ECUspare1 SG_ 1943 Debug_PVT_SCIM_RD_BHS4_Volt 200;
BA_REL_ "GenSigFirstTimeoutTime" BU_SG_REL_ ECUspare1 SG_ 1943 Debug_PVT_SCIM_RD_BHS4_Volt 1500;
BA_REL_ "GenSigTimeoutTime" BU_SG_REL_ ECUspare1 SG_ 1943 Debug_PVT_SCIM_RD_BHS4_Fault 200;
BA_REL_ "GenSigFirstTimeoutTime" BU_SG_REL_ ECUspare1 SG_ 1943 Debug_PVT_SCIM_RD_BHS4_Fault 1500;
BA_REL_ "GenSigFirstTimeoutTime" BU_SG_REL_ ECUspare1 SG_ 1943 Debug_PVT_SCIM_RD_BHS3_Volt 1500;
BA_REL_ "GenSigTimeoutTime" BU_SG_REL_ ECUspare1 SG_ 1943 Debug_PVT_SCIM_RD_BHS3_Volt 200;
BA_REL_ "GenSigTimeoutTime" BU_SG_REL_ ECUspare1 SG_ 1943 Debug_PVT_SCIM_RD_BHS3_Fault 200;
BA_REL_ "GenSigFirstTimeoutTime" BU_SG_REL_ ECUspare1 SG_ 1943 Debug_PVT_SCIM_RD_BHS3_Fault 1500;
BA_REL_ "GenSigTimeoutTime" BU_SG_REL_ ECUspare1 SG_ 1943 Debug_PVT_SCIM_RD_BHS2_Volt 200;
BA_REL_ "GenSigFirstTimeoutTime" BU_SG_REL_ ECUspare1 SG_ 1943 Debug_PVT_SCIM_RD_BHS2_Volt 1500;
BA_REL_ "GenSigTimeoutTime" BU_SG_REL_ ECUspare1 SG_ 1943 Debug_PVT_SCIM_RD_BHS2_Fault 200;
BA_REL_ "GenSigFirstTimeoutTime" BU_SG_REL_ ECUspare1 SG_ 1943 Debug_PVT_SCIM_RD_BHS2_Fault 1500;
BA_REL_ "GenSigTimeoutTime" BU_SG_REL_ ECUspare1 SG_ 1943 Debug_PVT_SCIM_RD_BHS1_Volt 200;
BA_REL_ "GenSigFirstTimeoutTime" BU_SG_REL_ ECUspare1 SG_ 1943 Debug_PVT_SCIM_RD_BHS1_Volt 1500;
BA_REL_ "GenSigTimeoutTime" BU_SG_REL_ ECUspare1 SG_ 1943 Debug_PVT_SCIM_RD_BHS1_Fault 200;
BA_REL_ "GenSigFirstTimeoutTime" BU_SG_REL_ ECUspare1 SG_ 1943 Debug_PVT_SCIM_RD_BHS1_Fault 1500;
BA_REL_ "GenSigTimeoutTime" BU_SG_REL_ ECUspare1 SG_ 1936 Debug_PVT_SCIM_RD_VBAT_Fault 200;
BA_REL_ "GenSigFirstTimeoutTime" BU_SG_REL_ ECUspare1 SG_ 1936 Debug_PVT_SCIM_RD_VBAT_Fault 1500;
BA_REL_ "GenSigTimeoutTime" BU_SG_REL_ ECUspare1 SG_ 1936 Debug_PVT_SCIM_RD_12VParkedFault 200;
BA_REL_ "GenSigFirstTimeoutTime" BU_SG_REL_ ECUspare1 SG_ 1936 Debug_PVT_SCIM_RD_12VParkedFault 1500;
BA_REL_ "GenSigFirstTimeoutTime" BU_SG_REL_ ECUspare1 SG_ 1936 Debug_PVT_SCIM_RD_12VLivingFault 1500;
BA_REL_ "GenSigTimeoutTime" BU_SG_REL_ ECUspare1 SG_ 1936 Debug_PVT_SCIM_RD_12VLivingFault 200;
BA_REL_ "GenSigFirstTimeoutTime" BU_SG_REL_ ECUspare1 SG_ 1936 Debug_PVT_SCIM_RD_12VDCDCFault 1500;
BA_REL_ "GenSigTimeoutTime" BU_SG_REL_ ECUspare1 SG_ 1936 Debug_PVT_SCIM_RD_12VDCDCFault 200;
BA_REL_ "GenSigTimeoutTime" BU_SG_REL_ ECUspare1 SG_ 1936 Debug_PVT_SCIM_RD_VBAT 200;
BA_REL_ "GenSigFirstTimeoutTime" BU_SG_REL_ ECUspare1 SG_ 1936 Debug_PVT_SCIM_RD_VBAT 1500;
BA_REL_ "GenSigTimeoutTime" BU_SG_REL_ ECUspare1 SG_ 1936 Debug_PVT_SCIM_RD_12VParkedVolt 200;
BA_REL_ "GenSigFirstTimeoutTime" BU_SG_REL_ ECUspare1 SG_ 1936 Debug_PVT_SCIM_RD_12VParkedVolt 1500;
BA_REL_ "GenSigTimeoutTime" BU_SG_REL_ ECUspare1 SG_ 1936 Debug_PVT_SCIM_RD_12VLivingVolt 200;
BA_REL_ "GenSigFirstTimeoutTime" BU_SG_REL_ ECUspare1 SG_ 1936 Debug_PVT_SCIM_RD_12VLivingVolt 1500;
BA_REL_ "GenSigFirstTimeoutTime" BU_SG_REL_ ECUspare1 SG_ 1936 Debug_PVT_SCIM_RD_12VDCDCVolt 1500;
BA_REL_ "GenSigTimeoutTime" BU_SG_REL_ ECUspare1 SG_ 1936 Debug_PVT_SCIM_RD_12VDCDCVolt 200;
BA_REL_ "GenSigFirstTimeoutTime" BU_SG_REL_ IC3 SG_ 1338 RoadSpeedRestriction 12000;
BA_REL_ "GenSigTimeoutTime" BU_SG_REL_ IC3 SG_ 1338 RoadSpeedRestriction 3000;
BA_REL_ "GenSigFirstTimeoutTime" BU_SG_REL_ IC3 SG_ 1338 ObserveRoadRestriction_OpCap 12000;
BA_REL_ "GenSigTimeoutTime" BU_SG_REL_ IC3 SG_ 1338 ObserveRoadRestriction_OpCap 3000;
BA_REL_ "GenSigFirstTimeoutTime" BU_SG_REL_ IC3 SG_ 1338 RoadOvertakingRestriction 12000;
BA_REL_ "GenSigTimeoutTime" BU_SG_REL_ IC3 SG_ 1338 RoadOvertakingRestriction 3000;
BA_REL_ "GenSigFirstTimeoutTime" BU_SG_REL_ IC3 SG_ 1338 RoadTypeSpeedRestriction 12000;
BA_REL_ "GenSigTimeoutTime" BU_SG_REL_ IC3 SG_ 1338 RoadTypeSpeedRestriction 3000;
BA_REL_ "GenSigFirstTimeoutTime" BU_SG_REL_ IC3 SG_ 1338 ObserveRoadRestrictionStatus 12000;
BA_REL_ "GenSigTimeoutTime" BU_SG_REL_ IC3 SG_ 1338 ObserveRoadRestrictionStatus 3000;
BA_REL_ "GenSigFirstTimeoutTime" BU_SG_REL_ VMCU SG_ 2432641616 FASHapticFeedbackRequest_ISig_4 3000;
BA_REL_ "GenSigTimeoutTime" BU_SG_REL_ VMCU SG_ 2432641616 FASHapticFeedbackRequest_ISig_4 120;
BA_REL_ "GenSigFirstTimeoutTime" BU_SG_REL_ VMCU SG_ 2432641616 FASCurvatureRequest_ISig_4 3000;
BA_REL_ "GenSigTimeoutTime" BU_SG_REL_ VMCU SG_ 2432641616 FASCurvatureRequest_ISig_4 120;
BA_REL_ "GenSigFirstTimeoutTime" BU_SG_REL_ VMCU SG_ 2432641616 FASControlMode_ISig_4 3000;
BA_REL_ "GenSigTimeoutTime" BU_SG_REL_ VMCU SG_ 2432641616 FASControlMode_ISig_4 120;
BA_REL_ "GenSigFirstTimeoutTime" BU_SG_REL_ VMCU SG_ 2432641616 FASExtCtrlMsgChecksum_ISig_4 3000;
BA_REL_ "GenSigTimeoutTime" BU_SG_REL_ VMCU SG_ 2432641616 FASExtCtrlMsgChecksum_ISig_4 120;
BA_REL_ "GenSigFirstTimeoutTime" BU_SG_REL_ VMCU SG_ 2432641616 ReferencePathCurvature_ISig_4 3000;
BA_REL_ "GenSigTimeoutTime" BU_SG_REL_ VMCU SG_ 2432641616 ReferencePathCurvature_ISig_4 120;
BA_REL_ "GenSigFirstTimeoutTime" BU_SG_REL_ VMCU SG_ 2432641616 FASExtCtrlMsgCounter_ISig_4 3000;
BA_REL_ "GenSigTimeoutTime" BU_SG_REL_ VMCU SG_ 2432641616 FASExtCtrlMsgCounter_ISig_4 120;
BA_REL_ "GenSigFirstTimeoutTime" BU_SG_REL_ VMCU SG_ 2432641616 FASRoadWheelAngleRequest_ISig_4 3000;
BA_REL_ "GenSigTimeoutTime" BU_SG_REL_ VMCU SG_ 2432641616 FASRoadWheelAngleRequest_ISig_4 120;
BA_REL_ "GenSigFirstTimeoutTime" BU_SG_REL_ VMCU SG_ 2432640336 GlareFreeArea02_LeftAngle_ISig_4 3000;
BA_REL_ "GenSigTimeoutTime" BU_SG_REL_ VMCU SG_ 2432640336 GlareFreeArea02_LeftAngle_ISig_4 120;
BA_REL_ "GenSigFirstTimeoutTime" BU_SG_REL_ VMCU SG_ 2432640336 GlareFreeArea02_RightAngle_ISig_ 3000;
BA_REL_ "GenSigTimeoutTime" BU_SG_REL_ VMCU SG_ 2432640336 GlareFreeArea02_RightAngle_ISig_ 120;
BA_REL_ "GenSigFirstTimeoutTime" BU_SG_REL_ VMCU SG_ 2432640336 GlareFreeArea02_Distance_ISig_4 3000;
BA_REL_ "GenSigTimeoutTime" BU_SG_REL_ VMCU SG_ 2432640336 GlareFreeArea02_Distance_ISig_4 120;
BA_REL_ "GenSigFirstTimeoutTime" BU_SG_REL_ VMCU SG_ 2432639568 GlareFreeArea01_LeftAngle_ISig_4 3000;
BA_REL_ "GenSigTimeoutTime" BU_SG_REL_ VMCU SG_ 2432639568 GlareFreeArea01_LeftAngle_ISig_4 120;
BA_REL_ "GenSigFirstTimeoutTime" BU_SG_REL_ VMCU SG_ 2432639568 GlareFreeArea03_Distance_ISig_4 3000;
BA_REL_ "GenSigTimeoutTime" BU_SG_REL_ VMCU SG_ 2432639568 GlareFreeArea03_Distance_ISig_4 120;
BA_REL_ "GenSigFirstTimeoutTime" BU_SG_REL_ VMCU SG_ 2432639568 GlareFreeArea03_LeftAngle_ISig_4 3000;
BA_REL_ "GenSigTimeoutTime" BU_SG_REL_ VMCU SG_ 2432639568 GlareFreeArea03_LeftAngle_ISig_4 120;
BA_REL_ "GenSigFirstTimeoutTime" BU_SG_REL_ VMCU SG_ 2432639568 GlareFreeArea03_RightAngle_ISig_ 3000;
BA_REL_ "GenSigTimeoutTime" BU_SG_REL_ VMCU SG_ 2432639568 GlareFreeArea03_RightAngle_ISig_ 120;
BA_REL_ "GenSigFirstTimeoutTime" BU_SG_REL_ VMCU SG_ 2432639568 GlareFreeArea01_Distance_ISig_4 3000;
BA_REL_ "GenSigTimeoutTime" BU_SG_REL_ VMCU SG_ 2432639568 GlareFreeArea01_Distance_ISig_4 120;
BA_REL_ "GenSigFirstTimeoutTime" BU_SG_REL_ VMCU SG_ 2432639568 GlareFreeArea01_RightAngle_ISig_ 3000;
BA_REL_ "GenSigTimeoutTime" BU_SG_REL_ VMCU SG_ 2432639568 GlareFreeArea01_RightAngle_ISig_ 120;
BA_REL_ "GenSigFirstTimeoutTime" BU_SG_REL_ IC3 SG_ 2499772240 TrafficSituationCriticality 3000;
BA_REL_ "GenSigTimeoutTime" BU_SG_REL_ IC3 SG_ 2499772240 TrafficSituationCriticality 600;
BA_REL_ "GenSigFirstTimeoutTime" BU_SG_REL_ VMCU SG_ 2499772240 VisionLight_stat 3000;
BA_REL_ "GenSigTimeoutTime" BU_SG_REL_ VMCU SG_ 2499772240 VisionLight_stat 600;
BA_REL_ "GenSigFirstTimeoutTime" BU_SG_REL_ BBM SG_ 2499772240 BBSteeringStatus_ISig_4 3000;
BA_REL_ "GenSigTimeoutTime" BU_SG_REL_ BBM SG_ 2499772240 BBSteeringStatus_ISig_4 600;
BA_REL_ "GenSigFirstTimeoutTime" BU_SG_REL_ TECU SG_ 2499772240 ACCiSeeDistanceGap 3000;
BA_REL_ "GenSigTimeoutTime" BU_SG_REL_ TECU SG_ 2499772240 ACCiSeeDistanceGap 600;
BA_REL_ "GenSigFirstTimeoutTime" BU_SG_REL_ IC3 SG_ 2466246992 ForwardLookingCameraStatus_ISig_ 3000;
BA_REL_ "GenSigTimeoutTime" BU_SG_REL_ IC3 SG_ 2466246992 ForwardLookingCameraStatus_ISig_ 240;
BA_REL_ "GenSigFirstTimeoutTime" BU_SG_REL_ EMS SG_ 2466246992 XARDACU_ControlMode 3000;
BA_REL_ "GenSigTimeoutTime" BU_SG_REL_ EMS SG_ 2466246992 XARDACU_ControlMode 240;
BA_REL_ "GenSigFirstTimeoutTime" BU_SG_REL_ TECU SG_ 2466246992 XARDACU_ControlMode 3000;
BA_REL_ "GenSigTimeoutTime" BU_SG_REL_ TECU SG_ 2466246992 XARDACU_ControlMode 240;
BA_REL_ "GenSigFirstTimeoutTime" BU_SG_REL_ TECU SG_ 2466246992 ACCiRollInhibit 3000;
BA_REL_ "GenSigTimeoutTime" BU_SG_REL_ TECU SG_ 2466246992 ACCiRollInhibit 240;
BA_REL_ "GenSigFirstTimeoutTime" BU_SG_REL_ IC3 SG_ 2466246992 CMReducedAbilityStatus 3000;
BA_REL_ "GenSigTimeoutTime" BU_SG_REL_ IC3 SG_ 2466246992 CMReducedAbilityStatus 240;
BA_REL_ "GenSigFirstTimeoutTime" BU_SG_REL_ VMCU SG_ 2466246992 CollisionSituationAliveAck 3000;
BA_REL_ "GenSigTimeoutTime" BU_SG_REL_ VMCU SG_ 2466246992 CollisionSituationAliveAck 240;
BA_REL_ "GenSigFirstTimeoutTime" BU_SG_REL_ IC3 SG_ 2466246992 ForwardLookingRadarStatus_ISig_4 3000;
BA_REL_ "GenSigTimeoutTime" BU_SG_REL_ IC3 SG_ 2466246992 ForwardLookingRadarStatus_ISig_4 240;
BA_REL_ "GenSigFirstTimeoutTime" BU_SG_REL_ VMCU SG_ 2466246992 XPRRequest_CM_ISig_4 3000;
BA_REL_ "GenSigTimeoutTime" BU_SG_REL_ VMCU SG_ 2466246992 XPRRequest_CM_ISig_4 240;
BA_REL_ "GenSigFirstTimeoutTime" BU_SG_REL_ IC3 SG_ 2466246992 LPOSBlocked 3000;
BA_REL_ "GenSigTimeoutTime" BU_SG_REL_ IC3 SG_ 2466246992 LPOSBlocked 240;
BA_REL_ "GenSigFirstTimeoutTime" BU_SG_REL_ EMS SG_ 2466246992 XARDACU_AccelDemand 3000;
BA_REL_ "GenSigTimeoutTime" BU_SG_REL_ EMS SG_ 2466246992 XARDACU_AccelDemand 240;
BA_REL_ "GenSigFirstTimeoutTime" BU_SG_REL_ TECU SG_ 2466246992 XARDACU_AccelDemand 3000;
BA_REL_ "GenSigTimeoutTime" BU_SG_REL_ TECU SG_ 2466246992 XARDACU_AccelDemand 240;
BA_REL_ "GenSigFirstTimeoutTime" BU_SG_REL_ VMCU SG_ 2466246992 CollSituationHazardLightReq 3000;
BA_REL_ "GenSigTimeoutTime" BU_SG_REL_ VMCU SG_ 2466246992 CollSituationHazardLightReq 240;
BA_REL_ "GenSigFirstTimeoutTime" BU_SG_REL_ IC3 SG_ 2432690512 PathDeviationDriverAlert 3000;
BA_REL_ "GenSigTimeoutTime" BU_SG_REL_ IC3 SG_ 2432690512 PathDeviationDriverAlert 240;
BA_REL_ "GenSigFirstTimeoutTime" BU_SG_REL_ VMCU SG_ 2432690512 PathDeviationDriverAlert 3000;
BA_REL_ "GenSigTimeoutTime" BU_SG_REL_ VMCU SG_ 2432690512 PathDeviationDriverAlert 240;
BA_REL_ "GenSigFirstTimeoutTime" BU_SG_REL_ TECU SG_ 2432690512 CM_DisengageDrivelineRequest 3000;
BA_REL_ "GenSigTimeoutTime" BU_SG_REL_ TECU SG_ 2432690512 CM_DisengageDrivelineRequest 240;
BA_REL_ "GenSigFirstTimeoutTime" BU_SG_REL_ VMCU SG_ 2432690512 ACCBrakeRequestStatus 3000;
BA_REL_ "GenSigTimeoutTime" BU_SG_REL_ VMCU SG_ 2432690512 ACCBrakeRequestStatus 240;
BA_REL_ "GenSigFirstTimeoutTime" BU_SG_REL_ IC3 SG_ 2432690512 FrontalCollisionDriverAlert_ISig 3000;
BA_REL_ "GenSigTimeoutTime" BU_SG_REL_ IC3 SG_ 2432690512 FrontalCollisionDriverAlert_ISig 240;
BA_REL_ "GenSigFirstTimeoutTime" BU_SG_REL_ VMCU SG_ 2432690512 FrontalCollisionDriverAlert_ISig 3000;
BA_REL_ "GenSigTimeoutTime" BU_SG_REL_ VMCU SG_ 2432690512 FrontalCollisionDriverAlert_ISig 120;
BA_REL_ "GenSigFirstTimeoutTime" BU_SG_REL_ IC3 SG_ 2432690512 ACC_SGOFaultCondStat_SeatBelt 3000;
BA_REL_ "GenSigTimeoutTime" BU_SG_REL_ IC3 SG_ 2432690512 ACC_SGOFaultCondStat_SeatBelt 240;
BA_REL_ "GenSigFirstTimeoutTime" BU_SG_REL_ CIOM SG_ 2432690512 CM_Status_ISig_4 3000;
BA_REL_ "GenSigTimeoutTime" BU_SG_REL_ CIOM SG_ 2432690512 CM_Status_ISig_4 240;
BA_REL_ "GenSigFirstTimeoutTime" BU_SG_REL_ VMCU SG_ 2432690512 CM_Status_ISig_4 3000;
BA_REL_ "GenSigTimeoutTime" BU_SG_REL_ VMCU SG_ 2432690512 CM_Status_ISig_4 240;
BA_REL_ "GenSigFirstTimeoutTime" BU_SG_REL_ IC3 SG_ 2432690512 CM_Status_ISig_4 3000;
BA_REL_ "GenSigTimeoutTime" BU_SG_REL_ IC3 SG_ 2432690512 CM_Status_ISig_4 240;
BA_REL_ "GenSigFirstTimeoutTime" BU_SG_REL_ IC3 SG_ 2432690512 DASApplicationStatus 3000;
BA_REL_ "GenSigTimeoutTime" BU_SG_REL_ IC3 SG_ 2432690512 DASApplicationStatus 240;
BA_REL_ "GenSigFirstTimeoutTime" BU_SG_REL_ VMCU SG_ 2432690512 DASApplicationStatus 3000;
BA_REL_ "GenSigTimeoutTime" BU_SG_REL_ VMCU SG_ 2432690512 DASApplicationStatus 120;
BA_REL_ "GenSigFirstTimeoutTime" BU_SG_REL_ CIOM SG_ 2432690512 DASApplicationStatus 3000;
BA_REL_ "GenSigTimeoutTime" BU_SG_REL_ CIOM SG_ 2432690512 DASApplicationStatus 240;
BA_REL_ "GenSigFirstTimeoutTime" BU_SG_REL_ VMCU SG_ 2432690512 ACC_Status 3000;
BA_REL_ "GenSigTimeoutTime" BU_SG_REL_ VMCU SG_ 2432690512 ACC_Status 240;
BA_REL_ "GenSigFirstTimeoutTime" BU_SG_REL_ IC3 SG_ 2432690512 ACC_Status 3000;
BA_REL_ "GenSigTimeoutTime" BU_SG_REL_ IC3 SG_ 2432690512 ACC_Status 240;
BA_REL_ "GenSigFirstTimeoutTime" BU_SG_REL_ TECU SG_ 2432690512 ACC_Status 3000;
BA_REL_ "GenSigTimeoutTime" BU_SG_REL_ TECU SG_ 2432690512 ACC_Status 240;
BA_REL_ "GenSigFirstTimeoutTime" BU_SG_REL_ CIOM SG_ 2432690512 LKSApplicationStatus 3000;
BA_REL_ "GenSigTimeoutTime" BU_SG_REL_ CIOM SG_ 2432690512 LKSApplicationStatus 240;
BA_REL_ "GenSigFirstTimeoutTime" BU_SG_REL_ VMCU SG_ 2432690512 LKSApplicationStatus 3000;
BA_REL_ "GenSigTimeoutTime" BU_SG_REL_ VMCU SG_ 2432690512 LKSApplicationStatus 120;
BA_REL_ "GenSigFirstTimeoutTime" BU_SG_REL_ IC3 SG_ 2432690512 LKSApplicationStatus 3000;
BA_REL_ "GenSigTimeoutTime" BU_SG_REL_ IC3 SG_ 2432690512 LKSApplicationStatus 240;
BA_REL_ "GenSigFirstTimeoutTime" BU_SG_REL_ IC3 SG_ 2432690512 LCSSystemStatus 3000;
BA_REL_ "GenSigTimeoutTime" BU_SG_REL_ IC3 SG_ 2432690512 LCSSystemStatus 240;
BA_REL_ "GenSigFirstTimeoutTime" BU_SG_REL_ CIOM SG_ 2432690512 LCSSystemStatus 3000;
BA_REL_ "GenSigTimeoutTime" BU_SG_REL_ CIOM SG_ 2432690512 LCSSystemStatus 240;
BA_REL_ "GenSigFirstTimeoutTime" BU_SG_REL_ IC3 SG_ 2432690512 ACC_SGOFaultCondStat_SigStat 3000;
BA_REL_ "GenSigTimeoutTime" BU_SG_REL_ IC3 SG_ 2432690512 ACC_SGOFaultCondStat_SigStat 240;
BA_REL_ "GenSigFirstTimeoutTime" BU_SG_REL_ IC3 SG_ 2432690512 ACC_SGOFaultCondStat_Target 3000;
BA_REL_ "GenSigTimeoutTime" BU_SG_REL_ IC3 SG_ 2432690512 ACC_SGOFaultCondStat_Target 240;
BA_REL_ "GenSigFirstTimeoutTime" BU_SG_REL_ IC3 SG_ 2432690512 FCW_Status 3000;
BA_REL_ "GenSigTimeoutTime" BU_SG_REL_ IC3 SG_ 2432690512 FCW_Status 240;
BA_REL_ "GenSigFirstTimeoutTime" BU_SG_REL_ CIOM SG_ 2432690512 FCW_Status 3000;
BA_REL_ "GenSigTimeoutTime" BU_SG_REL_ CIOM SG_ 2432690512 FCW_Status 240;
BA_REL_ "GenSigFirstTimeoutTime" BU_SG_REL_ VMCU SG_ 2432690512 FCW_Status 3000;
BA_REL_ "GenSigTimeoutTime" BU_SG_REL_ VMCU SG_ 2432690512 FCW_Status 120;
BA_REL_ "GenSigFirstTimeoutTime" BU_SG_REL_ IC3 SG_ 2432690512 DriverImpairedDriverAlert 3000;
BA_REL_ "GenSigTimeoutTime" BU_SG_REL_ IC3 SG_ 2432690512 DriverImpairedDriverAlert 240;
BA_REL_ "GenSigFirstTimeoutTime" BU_SG_REL_ VMCU SG_ 2432690512 DriverImpairedDriverAlert 3000;
BA_REL_ "GenSigTimeoutTime" BU_SG_REL_ VMCU SG_ 2432690512 DriverImpairedDriverAlert 240;
BA_REL_ "GenSigFirstTimeoutTime" BU_SG_REL_ IC3 SG_ 2432690512 DriverVigilanceLevel 3000;
BA_REL_ "GenSigTimeoutTime" BU_SG_REL_ IC3 SG_ 2432690512 DriverVigilanceLevel 240;
BA_REL_ "GenSigFirstTimeoutTime" BU_SG_REL_ VMCU SG_ 2432690512 DriverVigilanceLevel 3000;
BA_REL_ "GenSigTimeoutTime" BU_SG_REL_ VMCU SG_ 2432690512 DriverVigilanceLevel 240;
BA_REL_ "GenSigFirstTimeoutTime" BU_SG_REL_ TECU SG_ 2432690512 ACCForwardVehicleSpeed_ISig_4 3000;
BA_REL_ "GenSigTimeoutTime" BU_SG_REL_ TECU SG_ 2432690512 ACCForwardVehicleSpeed_ISig_4 120;
BA_REL_ "GenSigFirstTimeoutTime" BU_SG_REL_ IC3 SG_ 2432690512 ACCForwardVehicleSpeed_ISig_4 3000;
BA_REL_ "GenSigTimeoutTime" BU_SG_REL_ IC3 SG_ 2432690512 ACCForwardVehicleSpeed_ISig_4 240;
BA_REL_ "GenSigFirstTimeoutTime" BU_SG_REL_ IC3 SG_ 2432690512 ACC_SGOFaultCondStat_Door 3000;
BA_REL_ "GenSigTimeoutTime" BU_SG_REL_ IC3 SG_ 2432690512 ACC_SGOFaultCondStat_Door 240;
BA_REL_ "GenSigFirstTimeoutTime" BU_SG_REL_ IC3 SG_ 2432690512 ACCTargetDetected 3000;
BA_REL_ "GenSigTimeoutTime" BU_SG_REL_ IC3 SG_ 2432690512 ACCTargetDetected 240;
BA_REL_ "GenSigFirstTimeoutTime" BU_SG_REL_ IC3 SG_ 2432690512 ACCForwardVehicleDistance_ISig_4 3000;
BA_REL_ "GenSigTimeoutTime" BU_SG_REL_ IC3 SG_ 2432690512 ACCForwardVehicleDistance_ISig_4 240;
BA_REL_ "GenSigFirstTimeoutTime" BU_SG_REL_ TECU SG_ 2432690512 ACCForwardVehicleDistance_ISig_4 3000;
BA_REL_ "GenSigTimeoutTime" BU_SG_REL_ TECU SG_ 2432690512 ACCForwardVehicleDistance_ISig_4 120;
BA_REL_ "GenSigFirstTimeoutTime" BU_SG_REL_ CIOM SG_ 2432690512 LKSCorrectiveSteeringStatus 3000;
BA_REL_ "GenSigTimeoutTime" BU_SG_REL_ CIOM SG_ 2432690512 LKSCorrectiveSteeringStatus 120;
BA_REL_ "GenSigFirstTimeoutTime" BU_SG_REL_ IC3 SG_ 2432690512 ACC_SGOFaultCondStat_Other 3000;
BA_REL_ "GenSigTimeoutTime" BU_SG_REL_ IC3 SG_ 2432690512 ACC_SGOFaultCondStat_Other 240;
BA_REL_ "GenSigFirstTimeoutTime" BU_SG_REL_ IC3 SG_ 2432690512 LCSSoundSettingStatus 3000;
BA_REL_ "GenSigTimeoutTime" BU_SG_REL_ IC3 SG_ 2432690512 LCSSoundSettingStatus 240;
BA_REL_ "GenSigFirstTimeoutTime" BU_SG_REL_ IC3 SG_ 2432690512 ACC_SGOFaultCondStat_Speed 3000;
BA_REL_ "GenSigTimeoutTime" BU_SG_REL_ IC3 SG_ 2432690512 ACC_SGOFaultCondStat_Speed 240;
BA_REL_ "GenSigFirstTimeoutTime" BU_SG_REL_ IC3 SG_ 551 AutoBlowerLevel_Status_ISig_4 3000;
BA_REL_ "GenSigTimeoutTime" BU_SG_REL_ IC3 SG_ 551 AutoBlowerLevel_Status_ISig_4 240;
BA_REL_ "GenSigFirstTimeoutTime" BU_SG_REL_ IC3 SG_ 551 AutoDefogmode_Status_ISig_4 3000;
BA_REL_ "GenSigTimeoutTime" BU_SG_REL_ IC3 SG_ 551 AutoDefogmode_Status_ISig_4 240;
BA_REL_ "GenSigFirstTimeoutTime" BU_SG_REL_ IC3 SG_ 551 AQSmode_Status_ISig_4 3000;
BA_REL_ "GenSigTimeoutTime" BU_SG_REL_ IC3 SG_ 551 AQSmode_Status_ISig_4 240;
BA_REL_ "GenSigFirstTimeoutTime" BU_SG_REL_ IC3 SG_ 551 ACmode_Status_ISig_4 3000;
BA_REL_ "GenSigTimeoutTime" BU_SG_REL_ IC3 SG_ 551 ACmode_Status_ISig_4 240;
BA_REL_ "GenSigFirstTimeoutTime" BU_SG_REL_ DACU SG_ 2432685120 LKSCSEnableSwitch_rqst 3000;
BA_REL_ "GenSigTimeoutTime" BU_SG_REL_ DACU SG_ 2432685120 LKSCSEnableSwitch_rqst 240;
BA_REL_ "GenSigFirstTimeoutTime" BU_SG_REL_ VMCU SG_ 2566078272 TrafficAccidentHazardLightRqst_I 3000;
BA_REL_ "GenSigTimeoutTime" BU_SG_REL_ VMCU SG_ 2566078272 TrafficAccidentHazardLightRqst_I 600;
BA_REL_ "GenSigFirstTimeoutTime" BU_SG_REL_ TECU SG_ 2566078272 GearboxUnlockAuth_stat 3000;
BA_REL_ "GenSigTimeoutTime" BU_SG_REL_ TECU SG_ 2566078272 GearboxUnlockAuth_stat 600;
BA_REL_ "GenSigFirstTimeoutTime" BU_SG_REL_ IC3 SG_ 2482978624 ExtraHeating_status_ISig_4 3000;
BA_REL_ "GenSigTimeoutTime" BU_SG_REL_ IC3 SG_ 2482978624 ExtraHeating_status_ISig_4 300;
BA_REL_ "GenSigFirstTimeoutTime" BU_SG_REL_ DACU SG_ 2482978624 FrontalCollisionAccidentStatus_I 3000;
BA_REL_ "GenSigTimeoutTime" BU_SG_REL_ DACU SG_ 2482978624 FrontalCollisionAccidentStatus_I 300;
BA_REL_ "GenSigFirstTimeoutTime" BU_SG_REL_ BBM SG_ 2482978624 TipperUpDownRequest_ISig_4 3000;
BA_REL_ "GenSigTimeoutTime" BU_SG_REL_ BBM SG_ 2482978624 TipperUpDownRequest_ISig_4 500;
BA_REL_ "GenSigFirstTimeoutTime" BU_SG_REL_ VMCU SG_ 2482978624 LoadDistributionRequested_ISig_4 3000;
BA_REL_ "GenSigTimeoutTime" BU_SG_REL_ VMCU SG_ 2482978624 LoadDistributionRequested_ISig_4 500;
BA_REL_ "GenSigFirstTimeoutTime" BU_SG_REL_ BBM SG_ 2482978624 TipperTailGateRequest_ISig_4 3000;
BA_REL_ "GenSigTimeoutTime" BU_SG_REL_ BBM SG_ 2482978624 TipperTailGateRequest_ISig_4 500;
BA_REL_ "GenSigFirstTimeoutTime" BU_SG_REL_ BBM SG_ 2482978624 TipperTippingBodySelection_ISig_ 3000;
BA_REL_ "GenSigTimeoutTime" BU_SG_REL_ BBM SG_ 2482978624 TipperTippingBodySelection_ISig_ 500;
BA_REL_ "GenSigFirstTimeoutTime" BU_SG_REL_ BBM SG_ 2482978624 TipperEmergencyStop_ISig_4 3000;
BA_REL_ "GenSigTimeoutTime" BU_SG_REL_ BBM SG_ 2482978624 TipperEmergencyStop_ISig_4 500;
BA_REL_ "GenSigFirstTimeoutTime" BU_SG_REL_ BBM SG_ 2482978624 ExtraBbWrcWatchdog_ISig_4 3000;
BA_REL_ "GenSigTimeoutTime" BU_SG_REL_ BBM SG_ 2482978624 ExtraBbWrcWatchdog_ISig_4 500;
BA_REL_ "GenSigFirstTimeoutTime" BU_SG_REL_ VMCU SG_ 2482978624 AutoFrontWheelDriveDrvReq 3000;
BA_REL_ "GenSigTimeoutTime" BU_SG_REL_ VMCU SG_ 2482978624 AutoFrontWheelDriveDrvReq 300;
BA_REL_ "GenSigFirstTimeoutTime" BU_SG_REL_ VMCU SG_ 2482978624 ShortStopHeater_cmd_ISig_4 3000;
BA_REL_ "GenSigTimeoutTime" BU_SG_REL_ VMCU SG_ 2482978624 ShortStopHeater_cmd_ISig_4 300;
BA_REL_ "GenSigFirstTimeoutTime" BU_SG_REL_ BBM SG_ 2482978624 TailLiftMotionRequest_ISig_4 3000;
BA_REL_ "GenSigTimeoutTime" BU_SG_REL_ BBM SG_ 2482978624 TailLiftMotionRequest_ISig_4 500;
BA_REL_ "GenSigFirstTimeoutTime" BU_SG_REL_ BBM SG_ 2482978624 TipperShakerRequest_ISig_4 3000;
BA_REL_ "GenSigTimeoutTime" BU_SG_REL_ BBM SG_ 2482978624 TipperShakerRequest_ISig_4 500;
BA_REL_ "GenSigFirstTimeoutTime" BU_SG_REL_ BBM SG_ 2482978624 TipperTarpaulinRequest_ISig_4 3000;
BA_REL_ "GenSigTimeoutTime" BU_SG_REL_ BBM SG_ 2482978624 TipperTarpaulinRequest_ISig_4 500;
BA_REL_ "GenSigFirstTimeoutTime" BU_SG_REL_ IC3 SG_ 2482978624 ABSInhibitRqstDenied 3000;
BA_REL_ "GenSigTimeoutTime" BU_SG_REL_ IC3 SG_ 2482978624 ABSInhibitRqstDenied 300;
BA_REL_ "GenSigFirstTimeoutTime" BU_SG_REL_ EMS SG_ 2498741568 ACCoolingFanSpeedRequest 3000;
BA_REL_ "GenSigTimeoutTime" BU_SG_REL_ EMS SG_ 2498741568 ACCoolingFanSpeedRequest 570;
BA_REL_ "GenSigFirstTimeoutTime" BU_SG_REL_ VMCU SG_ 2498741568 CabTilt_rqst 3000;
BA_REL_ "GenSigTimeoutTime" BU_SG_REL_ VMCU SG_ 2498741568 CabTilt_rqst 570;
BA_REL_ "GenSigFirstTimeoutTime" BU_SG_REL_ BBM SG_ 2498741568 Pto3CabRequest 3000;
BA_REL_ "GenSigTimeoutTime" BU_SG_REL_ BBM SG_ 2498741568 Pto3CabRequest 570;
BA_REL_ "GenSigFirstTimeoutTime" BU_SG_REL_ VMCU SG_ 2498741568 Pto3CabRequest 3000;
BA_REL_ "GenSigTimeoutTime" BU_SG_REL_ VMCU SG_ 2498741568 Pto3CabRequest 570;
BA_REL_ "GenSigFirstTimeoutTime" BU_SG_REL_ VMCU SG_ 2498741568 Pto4CabRequest 3000;
BA_REL_ "GenSigTimeoutTime" BU_SG_REL_ VMCU SG_ 2498741568 Pto4CabRequest 570;
BA_REL_ "GenSigFirstTimeoutTime" BU_SG_REL_ BBM SG_ 2498741568 Pto4CabRequest 3000;
BA_REL_ "GenSigTimeoutTime" BU_SG_REL_ BBM SG_ 2498741568 Pto4CabRequest 600;
BA_REL_ "GenSigFirstTimeoutTime" BU_SG_REL_ BBM SG_ 2498741568 WindscreenDefrostInd_cmd_ISig_4 3000;
BA_REL_ "GenSigTimeoutTime" BU_SG_REL_ BBM SG_ 2498741568 WindscreenDefrostInd_cmd_ISig_4 600;
BA_REL_ "GenSigFirstTimeoutTime" BU_SG_REL_ IC3 SG_ 2498741568 SRSAirbagStatus_ISig_4 3000;
BA_REL_ "GenSigTimeoutTime" BU_SG_REL_ IC3 SG_ 2498741568 SRSAirbagStatus_ISig_4 570;
BA_REL_ "GenSigFirstTimeoutTime" BU_SG_REL_ VMCU SG_ 2498741568 SRSAirbagStatus_ISig_4 3000;
BA_REL_ "GenSigTimeoutTime" BU_SG_REL_ VMCU SG_ 2498741568 SRSAirbagStatus_ISig_4 570;
BA_REL_ "GenSigFirstTimeoutTime" BU_SG_REL_ VMCU SG_ 2498741568 FrontLidAjar_Stat 3000;
BA_REL_ "GenSigTimeoutTime" BU_SG_REL_ VMCU SG_ 2498741568 FrontLidAjar_Stat 570;
BA_REL_ "GenSigFirstTimeoutTime" BU_SG_REL_ IC3 SG_ 2498741568 ParkingHeaterCleaning_Rqst_ISig_ 3000;
BA_REL_ "GenSigTimeoutTime" BU_SG_REL_ IC3 SG_ 2498741568 ParkingHeaterCleaning_Rqst_ISig_ 570;
BA_REL_ "GenSigFirstTimeoutTime" BU_SG_REL_ BBM SG_ 2498741568 Pto2CabRequest 3000;
BA_REL_ "GenSigTimeoutTime" BU_SG_REL_ BBM SG_ 2498741568 Pto2CabRequest 570;
BA_REL_ "GenSigFirstTimeoutTime" BU_SG_REL_ VMCU SG_ 2498741568 Pto2CabRequest 3000;
BA_REL_ "GenSigTimeoutTime" BU_SG_REL_ VMCU SG_ 2498741568 Pto2CabRequest 570;
BA_REL_ "GenSigFirstTimeoutTime" BU_SG_REL_ IC3 SG_ 2498741568 SeatSwivelWarning_rqst 3000;
BA_REL_ "GenSigTimeoutTime" BU_SG_REL_ IC3 SG_ 2498741568 SeatSwivelWarning_rqst 570;
BA_REL_ "GenSigFirstTimeoutTime" BU_SG_REL_ VMCU SG_ 2498741568 TemporaryRSLDriverRequest 3000;
BA_REL_ "GenSigTimeoutTime" BU_SG_REL_ VMCU SG_ 2498741568 TemporaryRSLDriverRequest 570;
BA_REL_ "GenSigFirstTimeoutTime" BU_SG_REL_ VMCU SG_ 2498741568 Pto1CabRequest 3000;
BA_REL_ "GenSigTimeoutTime" BU_SG_REL_ VMCU SG_ 2498741568 Pto1CabRequest 570;
BA_REL_ "GenSigFirstTimeoutTime" BU_SG_REL_ BBM SG_ 2498741568 Pto1CabRequest 3000;
BA_REL_ "GenSigTimeoutTime" BU_SG_REL_ BBM SG_ 2498741568 Pto1CabRequest 570;
BA_REL_ "GenSigFirstTimeoutTime" BU_SG_REL_ DACU SG_ 2483023936 LCS_EnableSwitch_rqst 3000;
BA_REL_ "GenSigTimeoutTime" BU_SG_REL_ DACU SG_ 2483023936 LCS_EnableSwitch_rqst 330;
BA_REL_ "GenSigFirstTimeoutTime" BU_SG_REL_ VMCU SG_ 2483023936 EscCrossCountryActivation_rqst 3000;
BA_REL_ "GenSigTimeoutTime" BU_SG_REL_ VMCU SG_ 2483023936 EscCrossCountryActivation_rqst 330;
BA_REL_ "GenSigFirstTimeoutTime" BU_SG_REL_ VMCU SG_ 2483023936 StaticCornerLightMode 3000;
BA_REL_ "GenSigTimeoutTime" BU_SG_REL_ VMCU SG_ 2483023936 StaticCornerLightMode 330;
BA_REL_ "GenSigFirstTimeoutTime" BU_SG_REL_ EMS SG_ 2483023936 SplitBoxDifflockActvnDrvrRqst_IS 3000;
BA_REL_ "GenSigTimeoutTime" BU_SG_REL_ EMS SG_ 2483023936 SplitBoxDifflockActvnDrvrRqst_IS 500;
BA_REL_ "GenSigFirstTimeoutTime" BU_SG_REL_ VMCU SG_ 2483023936 SplitBoxDifflockActvnDrvrRqst_IS 3000;
BA_REL_ "GenSigTimeoutTime" BU_SG_REL_ VMCU SG_ 2483023936 SplitBoxDifflockActvnDrvrRqst_IS 500;
BA_REL_ "GenSigFirstTimeoutTime" BU_SG_REL_ TECU SG_ 2483023936 SplitBoxDifflockActvnDrvrRqst_IS 3000;
BA_REL_ "GenSigTimeoutTime" BU_SG_REL_ TECU SG_ 2483023936 SplitBoxDifflockActvnDrvrRqst_IS 500;
BA_REL_ "GenSigFirstTimeoutTime" BU_SG_REL_ VMCU SG_ 2483023936 ATCFrontWheelDriveRequest 3000;
BA_REL_ "GenSigTimeoutTime" BU_SG_REL_ VMCU SG_ 2483023936 ATCFrontWheelDriveRequest 330;
BA_REL_ "GenSigFirstTimeoutTime" BU_SG_REL_ TECU SG_ 2483023936 ConstructionSwitch_stat 3000;
BA_REL_ "GenSigTimeoutTime" BU_SG_REL_ TECU SG_ 2483023936 ConstructionSwitch_stat 330;
BA_REL_ "GenSigFirstTimeoutTime" BU_SG_REL_ VMCU SG_ 2483023936 EscCabActionRequest 3000;
BA_REL_ "GenSigTimeoutTime" BU_SG_REL_ VMCU SG_ 2483023936 EscCabActionRequest 330;
BA_REL_ "GenSigFirstTimeoutTime" BU_SG_REL_ VMCU SG_ 2483023936 AdjustRequestForIdle 3000;
BA_REL_ "GenSigTimeoutTime" BU_SG_REL_ VMCU SG_ 2483023936 AdjustRequestForIdle 330;
BA_REL_ "GenSigFirstTimeoutTime" BU_SG_REL_ VMCU SG_ 2483023936 SCL_LogicPowerOutput_stat 3000;
BA_REL_ "GenSigTimeoutTime" BU_SG_REL_ VMCU SG_ 2483023936 SCL_LogicPowerOutput_stat 330;
BA_REL_ "GenSigFirstTimeoutTime" BU_SG_REL_ IC3 SG_ 2483023936 PinCode_validity_time 3000;
BA_REL_ "GenSigTimeoutTime" BU_SG_REL_ IC3 SG_ 2483023936 PinCode_validity_time 330;
BA_REL_ "GenSigFirstTimeoutTime" BU_SG_REL_ VMCU SG_ 2483023936 StatTrailerBrakeSwitchStatus 3000;
BA_REL_ "GenSigTimeoutTime" BU_SG_REL_ VMCU SG_ 2483023936 StatTrailerBrakeSwitchStatus 330;
BA_REL_ "GenSigFirstTimeoutTime" BU_SG_REL_ VMCU SG_ 2483023936 RoofHatch_HMI_rqst 3000;
BA_REL_ "GenSigTimeoutTime" BU_SG_REL_ VMCU SG_ 2483023936 RoofHatch_HMI_rqst 330;
BA_REL_ "GenSigFirstTimeoutTime" BU_SG_REL_ VMCU SG_ 2483023936 EscCabEnable 3000;
BA_REL_ "GenSigTimeoutTime" BU_SG_REL_ VMCU SG_ 2483023936 EscCabEnable 330;
BA_REL_ "GenSigFirstTimeoutTime" BU_SG_REL_ VMCU SG_ 2483023936 ExtraSideMarkers_Rqst 3000;
BA_REL_ "GenSigTimeoutTime" BU_SG_REL_ VMCU SG_ 2483023936 ExtraSideMarkers_Rqst 330;
BA_REL_ "GenSigFirstTimeoutTime" BU_SG_REL_ VMCU SG_ 2483023936 LevelingThumbwheel_stat 3000;
BA_REL_ "GenSigTimeoutTime" BU_SG_REL_ VMCU SG_ 2483023936 LevelingThumbwheel_stat 330;
BA_REL_ "GenSigFirstTimeoutTime" BU_SG_REL_ DACU SG_ 2483023936 DASActivation_rqst 3000;
BA_REL_ "GenSigTimeoutTime" BU_SG_REL_ DACU SG_ 2483023936 DASActivation_rqst 330;
BA_REL_ "GenSigFirstTimeoutTime" BU_SG_REL_ VMCU SG_ 2483023936 DriverSeatBeltSwitch_ISig_4 3000;
BA_REL_ "GenSigTimeoutTime" BU_SG_REL_ VMCU SG_ 2483023936 DriverSeatBeltSwitch_ISig_4 330;
BA_REL_ "GenSigFirstTimeoutTime" BU_SG_REL_ DACU SG_ 2483023936 DriverSeatBeltSwitch_ISig_4 3000;
BA_REL_ "GenSigTimeoutTime" BU_SG_REL_ DACU SG_ 2483023936 DriverSeatBeltSwitch_ISig_4 330;
BA_REL_ "GenSigFirstTimeoutTime" BU_SG_REL_ BBM SG_ 2483023936 DriverSeatBeltSwitch_ISig_4 3000;
BA_REL_ "GenSigTimeoutTime" BU_SG_REL_ BBM SG_ 2483023936 DriverSeatBeltSwitch_ISig_4 330;
BA_REL_ "GenSigFirstTimeoutTime" BU_SG_REL_ IC3 SG_ 2483023936 DriverSeatBeltSwitch_ISig_4 3000;
BA_REL_ "GenSigTimeoutTime" BU_SG_REL_ IC3 SG_ 2483023936 DriverSeatBeltSwitch_ISig_4 330;
BA_REL_ "GenSigFirstTimeoutTime" BU_SG_REL_ IC3 SG_ 2483023936 PinCode_stat 3000;
BA_REL_ "GenSigTimeoutTime" BU_SG_REL_ IC3 SG_ 2483023936 PinCode_stat 330;
BA_REL_ "GenSigFirstTimeoutTime" BU_SG_REL_ EMS SG_ 2483023936 WarmUp_Request 3000;
BA_REL_ "GenSigTimeoutTime" BU_SG_REL_ EMS SG_ 2483023936 WarmUp_Request 330;
BA_REL_ "GenSigFirstTimeoutTime" BU_SG_REL_ DACU SG_ 2483023936 LKSEnableSwitch_rqst 3000;
BA_REL_ "GenSigTimeoutTime" BU_SG_REL_ DACU SG_ 2483023936 LKSEnableSwitch_rqst 330;
BA_REL_ "GenSigFirstTimeoutTime" BU_SG_REL_ VMCU SG_ 2515579712 AlmClkSnze_LECM_rqst_ID_ISig_4 3000;
BA_REL_ "GenSigTimeoutTime" BU_SG_REL_ VMCU SG_ 2515579712 AlmClkSnze_LECM_rqst_ID_ISig_4 600;
BA_REL_ "GenSigFirstTimeoutTime" BU_SG_REL_ VMCU SG_ 2515579712 AlmClkSetCurAlm_rqst_ID 3000;
BA_REL_ "GenSigTimeoutTime" BU_SG_REL_ VMCU SG_ 2515579712 AlmClkSetCurAlm_rqst_ID 600;
BA_REL_ "GenSigFirstTimeoutTime" BU_SG_REL_ VMCU SG_ 2515579712 AlmClkSnze_LECM_rqst_Action_ISig 3000;
BA_REL_ "GenSigTimeoutTime" BU_SG_REL_ VMCU SG_ 2515579712 AlmClkSnze_LECM_rqst_Action_ISig 600;
BA_REL_ "GenSigFirstTimeoutTime" BU_SG_REL_ VMCU SG_ 2515579712 AlmClkSetCurAlm_rqst_Stat 3000;
BA_REL_ "GenSigTimeoutTime" BU_SG_REL_ VMCU SG_ 2515579712 AlmClkSetCurAlm_rqst_Stat 600;
BA_REL_ "GenSigFirstTimeoutTime" BU_SG_REL_ VMCU SG_ 2515579712 AlmClkSetCurAlm_rqst_SetMin 3000;
BA_REL_ "GenSigTimeoutTime" BU_SG_REL_ VMCU SG_ 2515579712 AlmClkSetCurAlm_rqst_SetMin 600;
BA_REL_ "GenSigFirstTimeoutTime" BU_SG_REL_ VMCU SG_ 2515579712 AlmClkSetCurAlm_rqst_SetHr 3000;
BA_REL_ "GenSigTimeoutTime" BU_SG_REL_ VMCU SG_ 2515579712 AlmClkSetCurAlm_rqst_SetHr 600;
BA_REL_ "GenSigFirstTimeoutTime" BU_SG_REL_ IC3 SG_ 2515579712 CollSituationHMICtrlRequestVM 3000;
BA_REL_ "GenSigTimeoutTime" BU_SG_REL_ IC3 SG_ 2515579712 CollSituationHMICtrlRequestVM 600;
BA_REL_ "GenSigFirstTimeoutTime" BU_SG_REL_ EMS SG_ 2515579712 AcCoolantPumpEngagementRequest_I 3000;
BA_REL_ "GenSigTimeoutTime" BU_SG_REL_ EMS SG_ 2515579712 AcCoolantPumpEngagementRequest_I 600;
BA_REL_ "GenSigFirstTimeoutTime" BU_SG_REL_ VMCU SG_ 2515579712 AlmClkSetCurAlm_rqst_Type 3000;
BA_REL_ "GenSigTimeoutTime" BU_SG_REL_ VMCU SG_ 2515579712 AlmClkSetCurAlm_rqst_Type 600;
BA_REL_ "GenSigFirstTimeoutTime" BU_SG_REL_ IC3 SG_ 2515579712 WRC_Docking_stat_ISig_4 3000;
BA_REL_ "GenSigTimeoutTime" BU_SG_REL_ IC3 SG_ 2515579712 WRC_Docking_stat_ISig_4 600;
BA_REL_ "GenSigFirstTimeoutTime" BU_SG_REL_ IC3 SG_ 2482995008 MirrorSelectRightMainBtn_stat_IS 3000;
BA_REL_ "GenSigTimeoutTime" BU_SG_REL_ IC3 SG_ 2482995008 MirrorSelectRightMainBtn_stat_IS 300;
BA_REL_ "GenSigFirstTimeoutTime" BU_SG_REL_ BBM SG_ 2482995008 WRCEngineStopRequest_ISig_4 3000;
BA_REL_ "GenSigTimeoutTime" BU_SG_REL_ BBM SG_ 2482995008 WRCEngineStopRequest_ISig_4 500;
BA_REL_ "GenSigFirstTimeoutTime" BU_SG_REL_ VMCU SG_ 2482995008 LiftAxle1DirectControl_ISig_4 3000;
BA_REL_ "GenSigTimeoutTime" BU_SG_REL_ VMCU SG_ 2482995008 LiftAxle1DirectControl_ISig_4 500;
BA_REL_ "GenSigFirstTimeoutTime" BU_SG_REL_ IC3 SG_ 2482995008 MirrorSelectRightWideBtn_stat_IS 3000;
BA_REL_ "GenSigTimeoutTime" BU_SG_REL_ IC3 SG_ 2482995008 MirrorSelectRightWideBtn_stat_IS 300;
BA_REL_ "GenSigFirstTimeoutTime" BU_SG_REL_ VMCU SG_ 2482995008 PanicAlarmFromKeyfob_rqst 3000;
BA_REL_ "GenSigTimeoutTime" BU_SG_REL_ VMCU SG_ 2482995008 PanicAlarmFromKeyfob_rqst 300;
BA_REL_ "GenSigFirstTimeoutTime" BU_SG_REL_ IC3 SG_ 2482995008 ParkingClimate_IndicationCmd_ISi 3000;
BA_REL_ "GenSigTimeoutTime" BU_SG_REL_ IC3 SG_ 2482995008 ParkingClimate_IndicationCmd_ISi 300;
BA_REL_ "GenSigFirstTimeoutTime" BU_SG_REL_ IC3 SG_ 2482995008 MirrorSelectLeftWideBtn_stat_ISi 3000;
BA_REL_ "GenSigTimeoutTime" BU_SG_REL_ IC3 SG_ 2482995008 MirrorSelectLeftWideBtn_stat_ISi 300;
BA_REL_ "GenSigFirstTimeoutTime" BU_SG_REL_ BBM SG_ 2482995008 WRCEngineStartRequest_ISig_4 3000;
BA_REL_ "GenSigTimeoutTime" BU_SG_REL_ BBM SG_ 2482995008 WRCEngineStartRequest_ISig_4 500;
BA_REL_ "GenSigFirstTimeoutTime" BU_SG_REL_ IC3 SG_ 2482995008 PW_Left_DS_SwStatus_ISig_4 3000;
BA_REL_ "GenSigTimeoutTime" BU_SG_REL_ IC3 SG_ 2482995008 PW_Left_DS_SwStatus_ISig_4 300;
BA_REL_ "GenSigFirstTimeoutTime" BU_SG_REL_ IC3 SG_ 2482995008 RegenerationSwitchStatus 3000;
BA_REL_ "GenSigTimeoutTime" BU_SG_REL_ IC3 SG_ 2482995008 RegenerationSwitchStatus 300;
BA_REL_ "GenSigFirstTimeoutTime" BU_SG_REL_ IC3 SG_ 2482995008 PW_Right_DS_SwStatus_ISig_4 3000;
BA_REL_ "GenSigTimeoutTime" BU_SG_REL_ IC3 SG_ 2482995008 PW_Right_DS_SwStatus_ISig_4 300;
BA_REL_ "GenSigFirstTimeoutTime" BU_SG_REL_ BBM SG_ 2482995008 DoorLock_stat_ISig_4 3000;
BA_REL_ "GenSigTimeoutTime" BU_SG_REL_ BBM SG_ 2482995008 DoorLock_stat_ISig_4 300;
BA_REL_ "GenSigFirstTimeoutTime" BU_SG_REL_ IC3 SG_ 2482995008 DoorLock_stat_ISig_4 3000;
BA_REL_ "GenSigTimeoutTime" BU_SG_REL_ IC3 SG_ 2482995008 DoorLock_stat_ISig_4 300;
BA_REL_ "GenSigFirstTimeoutTime" BU_SG_REL_ IC3 SG_ 2482995008 LuggageAjar_stat 3000;
BA_REL_ "GenSigTimeoutTime" BU_SG_REL_ IC3 SG_ 2482995008 LuggageAjar_stat 300;
BA_REL_ "GenSigFirstTimeoutTime" BU_SG_REL_ IC3 SG_ 2482995008 AlarmStatus_stat_ISig_4 3000;
BA_REL_ "GenSigTimeoutTime" BU_SG_REL_ IC3 SG_ 2482995008 AlarmStatus_stat_ISig_4 300;
BA_REL_ "GenSigFirstTimeoutTime" BU_SG_REL_ BBM SG_ 2482995008 AlarmTriggeringCause_stat_ISig_4 3000;
BA_REL_ "GenSigTimeoutTime" BU_SG_REL_ BBM SG_ 2482995008 AlarmTriggeringCause_stat_ISig_4 300;
BA_REL_ "GenSigFirstTimeoutTime" BU_SG_REL_ IC3 SG_ 2482995008 AlarmTriggeringCause_stat_ISig_4 3000;
BA_REL_ "GenSigTimeoutTime" BU_SG_REL_ IC3 SG_ 2482995008 AlarmTriggeringCause_stat_ISig_4 300;
BA_REL_ "GenSigFirstTimeoutTime" BU_SG_REL_ IC3 SG_ 2482995008 DoorsAjar_stat_ISig_4 3000;
BA_REL_ "GenSigTimeoutTime" BU_SG_REL_ IC3 SG_ 2482995008 DoorsAjar_stat_ISig_4 500;
BA_REL_ "GenSigFirstTimeoutTime" BU_SG_REL_ VMCU SG_ 2482995008 DoorsAjar_stat_ISig_4 3000;
BA_REL_ "GenSigTimeoutTime" BU_SG_REL_ VMCU SG_ 2482995008 DoorsAjar_stat_ISig_4 500;
BA_REL_ "GenSigFirstTimeoutTime" BU_SG_REL_ DACU SG_ 2482995008 DoorsAjar_stat_ISig_4 3000;
BA_REL_ "GenSigTimeoutTime" BU_SG_REL_ DACU SG_ 2482995008 DoorsAjar_stat_ISig_4 500;
BA_REL_ "GenSigFirstTimeoutTime" BU_SG_REL_ BBM SG_ 2482995008 DoorsAjar_stat_ISig_4 3000;
BA_REL_ "GenSigTimeoutTime" BU_SG_REL_ BBM SG_ 2482995008 DoorsAjar_stat_ISig_4 500;
BA_REL_ "GenSigFirstTimeoutTime" BU_SG_REL_ VMCU SG_ 2482995008 DoorAutoFunction_rqst 3000;
BA_REL_ "GenSigTimeoutTime" BU_SG_REL_ VMCU SG_ 2482995008 DoorAutoFunction_rqst 300;
BA_REL_ "GenSigFirstTimeoutTime" BU_SG_REL_ IC3 SG_ 2482995008 MirrorSelectLeftMainBtn_stat_ISi 3000;
BA_REL_ "GenSigTimeoutTime" BU_SG_REL_ IC3 SG_ 2482995008 MirrorSelectLeftMainBtn_stat_ISi 300;
VAL_ 1943 Debug_PVT_SCIM_RD_BHS4_Fault 0 "Nomal" 8 "Invalid[Error Value]" 5 "Reserved" 4 "Reserved" 7 "Voltage Too High" 6 "Voltage Too Low" 3 "Open Circuit" 2 "Short To Battery" 1 "Short To Ground" ;
VAL_ 1943 Debug_PVT_SCIM_RD_BHS3_Fault 0 "Nomal" 8 "Invalid[Error Value]" 5 "Reserved" 4 "Reserved" 7 "Voltage Too High" 6 "Voltage Too Low" 3 "Open Circuit" 2 "Short To Battery" 1 "Short To Ground" ;
VAL_ 1943 Debug_PVT_SCIM_RD_BHS2_Fault 0 "Nomal" 8 "Invalid[Error Value]" 5 "Reserved" 4 "Reserved" 7 "Voltage Too High" 6 "Voltage Too Low" 3 "Open Circuit" 2 "Short To Battery" 1 "Short To Ground" ;
VAL_ 1943 Debug_PVT_SCIM_RD_BHS1_Fault 0 "Nomal" 8 "Invalid[Error Value]" 5 "Reserved" 4 "Reserved" 7 "Voltage Too High" 6 "Voltage Too Low" 3 "Open Circuit" 2 "Short To Battery" 1 "Short To Ground" ;
VAL_ 1936 Debug_PVT_SCIM_RD_VBAT_Fault 8 "Invalid[Error Value]" 7 "Voltage Too High" 6 "Voltage Too Low" 5 "Voltage out of range" 4 "Reserved" 3 "Reserved" 2 "Reserved" 1 "Reserved" 0 "Nomal" ;
VAL_ 1936 Debug_PVT_SCIM_RD_12VParkedFault 8 "Invalid[Error Value]" 7 "Voltage Too High" 6 "Voltage Too Low" 5 "Reserved" 4 "Reserved" 3 "Reserved" 2 "Short To Battery" 1 "Short To Ground" 0 "Nomal" ;
VAL_ 1936 Debug_PVT_SCIM_RD_12VLivingFault 8 "Invalid[Error Value]" 7 "Voltage Too High" 6 "Voltage Too Low" 5 "Reserved" 4 "Reserved" 3 "Reserved" 2 "Short To Battery" 1 "Short To Ground" 0 "Nomal" ;
VAL_ 1936 Debug_PVT_SCIM_RD_12VDCDCFault 8 "invalid[Error Value]" 7 "Reserved" 6 "Reserved" 5 "Voltage out of range" 4 "Reserved" 3 "Reserved" 2 "Reserved" 1 "Reserved" 0 "Nomal" ;
VAL_ 1338 ObserveRoadRestriction_OpCap 3 "ObserveRoadRestriction_NotAvailable" 2 "ObserveRoadRestriction_Spare" 1 "ObserveRoadRestriction_FullPerformance" 0 "ObserveRoadRestriction_NoPerformance" ;
VAL_ 1338 RoadOvertakingRestriction 3 "RoadOvertakingRestriction_NotAvailable" 2 "RoadOvertakingRestriction_Error" 1 "RoadOvertakingRestriction_OvertakingRestricted" 0 "RoadOvertakingRestriction_OvertakingAllowedNotRestricted" ;
VAL_ 1338 RoadTypeSpeedRestriction 7 "RoadTypeSpeedRestriction_NotAvailable" 6 "RoadTypeSpeedRestriction_Spare4" 5 "RoadTypeSpeedRestriction_Spare3" 4 "RoadTypeSpeedRestriction_Spare2" 3 "RoadTypeSpeedRestriction_Spare1" 2 "RoadTypeSpeedRestriction_Expressway" 1 "RoadTypeSpeedRestriction_Motorway" 0 "RoadTypeSpeedRestriction_Highway_undefined" ;
VAL_ 1338 ObserveRoadRestrictionStatus 3 "OffOn_NotAvailable" 2 "OffOn_Error" 1 "OffOn_On" 0 "OffOn_Off" ;
VAL_ 2432641616 FASHapticFeedbackRequest_ISig_4 15 "FASHapticFeedbackRequest_NotAvailable" 14 "FASHapticFeedbackRequest_Error" 13 "FASHapticFeedbackRequest_Spare3" 12 "FASHapticFeedbackRequest_Spare2" 11 "FASHapticFeedbackRequest_Spare1" 10 "FASHapticFeedbackRequest_PredefinedFreqAndAmpl10" 9 "FASHapticFeedbackRequest_PredefinedFreqAndAmpl9" 8 "FASHapticFeedbackRequest_PredefinedFreqAndAmpl8" 7 "FASHapticFeedbackRequest_PredefinedFreqAndAmpl7" 6 "FASHapticFeedbackRequest_PredefinedFreqAndAmpl6" 5 "FASHapticFeedbackRequest_PredefinedFreqAndAmpl5" 4 "FASHapticFeedbackRequest_PredefinedFreqAndAmpl4" 3 "FASHapticFeedbackRequest_PredefinedFreqAndAmpl3" 2 "FASHapticFeedbackRequest_PredefinedFreqAndAmpl2" 1 "FASHapticFeedbackRequest_PredefinedFreqAndAmpl1" 0 "FASHapticFeedbackRequest_NoHapticFeedback" ;
VAL_ 2499772240 VisionLight_stat 7 "VisionLight_stat_NotAvailable" 6 "VisionLight_stat_Error" 5 "VisionLight_stat_Spare02" 4 "VisionLight_stat_Spare01" 3 "VisionLight_stat_CameraBlockedCondition" 2 "VisionLight_stat_NightSufficientLight" 1 "VisionLight_stat_NightNotSufficientLight" 0 "VisionLight_stat_Day" ;
VAL_ 2499772240 BBSteeringStatus_ISig_4 3 "InactiveActive_NotAvailable" 2 "InactiveActive_Error" 1 "InactiveActive_Active" 0 "InactiveActive_Inactive" ;
VAL_ 2466246992 ForwardLookingCameraStatus_ISig_ 15 "CameraStatus_NotAvailable" 14 "CameraStatus_Error" 13 "CameraStatus_Spare08" 12 "CameraStatus_Spare07" 11 "CameraStatus_Spare06" 10 "CameraStatus_Spare05" 9 "CameraStatus_Spare04" 8 "CameraStatus_Failure" 7 "CameraStatus_ShutDownCompleted" 6 "CameraStatus_ShutDownInitiated" 5 "CameraStatus_CalibrationOngoing" 4 "CameraStatus_NotCalibrated" 3 "CameraStatus_Misaligned" 2 "CameraStatus_Blocked" 1 "CameraStatus_WarmingUp" 0 "CameraStatus_FullyOperational" ;
VAL_ 2466246992 XARDACU_ControlMode 3 "XARControlMode_NotDefined" 2 "XARControlMode_CoastingModeRequest" 1 "XARControlMode_AccelerationControlWithMaximumMode" 0 "XARControlMode_OverrideDisabled" ;
VAL_ 2466246992 ACCiRollInhibit 3 "Inhibit_NotAvailable" 2 "Inhibit_Error" 1 "Inhibit_InhibitActive" 0 "Inhibit_NoInhibit" ;
VAL_ 2466246992 CMReducedAbilityStatus 7 "ReducedAbilityStatus_NotAvailable" 6 "ReducedAbilityStatus_Error" 5 "ReducedAbilityStatus_Spare4" 4 "ReducedAbilityStatus_Spare3" 3 "ReducedAbilityStatus_Spare2" 2 "ReducedAbilityStatus_Spare1" 1 "ReducedAbilityStatus_ReducedAbility" 0 "ReducedAbilityStatus_NoReducedAbility" ;
VAL_ 2466246992 ForwardLookingRadarStatus_ISig_4 15 "RadarStatus_NotAvailable" 14 "RadarStatus_Error" 13 "RadarStatus_Spare05" 12 "RadarStatus_Spare04" 11 "RadarStatus_Spare03" 10 "RadarStatus_Spare02" 9 "RadarStatus_Spare01" 8 "RadarStatus_Failure" 7 "RadarStatus_ShutDownCompleted" 6 "RadarStatus_ShutDownInitiated" 5 "RadarStatus_CalibrationOngoing" 4 "RadarStatus_NotCalibrated" 3 "RadarStatus_Misaligned" 2 "RadarStatus_Blocked" 1 "RadarStatus_WarmingUp" 0 "RadarStatus_FullyOperational" ;
VAL_ 2466246992 LPOSBlocked 3 "FalseTrue_NotAvaiable" 2 "FalseTrue_Error" 1 "FalseTrue_True" 0 "FalseTrue_False" ;
VAL_ 2466246992 CollSituationHazardLightReq 7 "ActivateDeactivateRqst3bit_NotAvailable" 6 "ActivateDeactivateRqst3bit_Error" 5 "ActivateDeactivateRqst3bit_Spare3" 4 "ActivateDeactivateRqst3bit_Spare2" 3 "ActivateDeactivateRqst3bit_Spare1" 2 "ActivateDeactivateRqst3bit_DeactivationRequest" 1 "ActivateDeactivateRqst3bit_ActivationRequest" 0 "ActivateDeactivateRqst3bit_NoRequest" ;
VAL_ 2432690512 PathDeviationDriverAlert 7 "LKSDepartureWarningStatus_NotAvailable" 6 "LKSDepartureWarningStatus_ErrorIndication" 5 "LKSDepartureWarningStatus_MajorDepartureWarning_Right" 4 "LKSDepartureWarningStatus_MajorDepartureWarning_Left" 3 "LKSDepartureWarningStatus_MinorDepartureWarning_Right" 2 "LKSDepartureWarningStatus_MinorDepartureWarning_Left" 1 "LKSDepartureWarningStatus_WarningNotPossible" 0 "LKSDepartureWarningStatus_NoWarning" ;
VAL_ 2432690512 CM_DisengageDrivelineRequest 3 "CM_DisengageDrivelineRequest_TakeNoAction" 2 "CM_DisengageDrivelineRequest_Reserved" 1 "CM_DisengageDrivelineRequest_DisengageDriveline" 0 "CM_DisengageDrivelineRequest_AllowDrivelineEngagement" ;
VAL_ 2432690512 ACCBrakeRequestStatus 3 "InactiveActive_NotAvailable" 2 "InactiveActive_Error" 1 "InactiveActive_Active" 0 "InactiveActive_Inactive" ;
VAL_ 2432690512 FrontalCollisionDriverAlert_ISig 7 "FCW_Warning_NotAvailable" 6 "FCW_Warning_ErrorIndicator" 5 "FCW_Warning_SpareValue_01" 4 "FCW_Warning_SpareValue" 3 "FCW_Warning_CMbBActiveWarning" 2 "FCW_Warning_CollisionWarning" 1 "FCW_Warning_PreliminaryCollisionWarning" 0 "FCW_Warning_NoWarning" ;
VAL_ 2432690512 ACC_SGOFaultCondStat_SeatBelt 1 "SeatBeltIndicationRqst_IndicationRequested" 0 "SeatBeltIndicationRqst_NoIndicationRequested" ;
VAL_ 2432690512 CM_Status_ISig_4 7 "CM_Status_NotAvailable" 6 "CM_Status_ErrorIndicator" 5 "CM_Status_CM_DisabledBySystem" 4 "CM_Status_CM_MitigationBrakingFinished" 3 "CM_Status_CM_MitigationBraking" 2 "CM_Status_CM_PreMitigationBraking" 1 "CM_Status_CM_Enabled" 0 "CM_Status_CM_Disabled" ;
VAL_ 2432690512 DASApplicationStatus 7 "DASSystemStatus_NA" 6 "DASSystemStatus_Error" 5 "DASSystemStatus_SpareValue_01" 4 "DASSystemStatus_SpareValue" 3 "DASSystemStatus_Limited_func" 2 "DASSystemStatus_INACTIVE" 1 "DASSystemStatus_ACTIVE" 0 "DASSystemStatus_OFF" ;
VAL_ 2432690512 ACC_Status 7 "ACC_Status_NotAvailable" 6 "ACC_Status_Error" 5 "ACC_Status_ACCFailureAndInactive" 4 "ACC_Status_Reserved" 3 "ACC_Status_ActiveWithLimitedBrakeCapacity" 2 "ACC_Status_ActiveECONOMYMODE" 1 "ACC_Status_ActiveSTANDARDMODE" 0 "ACC_Status_Inactive" ;
VAL_ 2432690512 LKSApplicationStatus 7 "LKSStatus_NotAvailable" 6 "LKSStatus_Error" 5 "LKSStatus_Spare_02" 4 "LKSStatus_Spare_01" 3 "LKSStatus_Spare" 2 "LKSStatus_ACTIVE" 1 "LKSStatus_INACTIVE" 0 "LKSStatus_OFF" ;
VAL_ 2432690512 LCSSystemStatus 7 "LCSSystemStatus_NotAvailable" 6 "LCSSystemStatus_Error" 5 "LCSSystemStatus_NotUsed" 4 "LCSSystemStatus_WarningRight" 3 "LCSSystemStatus_WarningLeft" 2 "LCSSystemStatus_EnabledAndActive" 1 "LCSSystemStatus_EnabledAndInactive" 0 "LCSSystemStatus_Disabled" ;
VAL_ 2432690512 ACC_SGOFaultCondStat_SigStat 1 "SigStat_SignalNotAvailable" 0 "SigStat_SignalOK" ;
VAL_ 2432690512 ACC_SGOFaultCondStat_Target 1 "TargetIndicationRqst_IndicationRequested" 0 "TargetIndicationRqst_NoIndicationRequested" ;
VAL_ 2432690512 FCW_Status 3 "DisableEnable_NotAvailable" 2 "DisableEnable_Error" 1 "DisableEnable_Enable" 0 "DisableEnable_Disable" ;
VAL_ 2432690512 DriverImpairedDriverAlert 7 "DASImpairmentWarningStatus_NotAvailable" 6 "DASImpairmentWarningStatus_ErrorIndicator" 5 "DASImpairmentWarningStatus_SPAREValue_02" 4 "DASImpairmentWarningStatus_SPAREValue_01" 3 "DASImpairmentWarningStatus_SPAREValue" 2 "DASImpairmentWarningStatus_MajorImpairmentWarning" 1 "DASImpairmentWarningStatus_MinorImpairmentWarning" 0 "DASImpairmentWarningStatus_NoWarning" ;
VAL_ 2432690512 DriverVigilanceLevel 7 "DASVigilanceLevelStatus_NotAvailable" 6 "DASVigilanceLevelStatus_Error" 5 "DASVigilanceLevelStatus_VigilanceLevel5" 4 "DASVigilanceLevelStatus_VigilanceLevel4" 3 "DASVigilanceLevelStatus_VigilanceLevel3" 2 "DASVigilanceLevelStatus_VigilanceLevel2" 1 "DASVigilanceLevelStatus_VigilanceLevel1" 0 "DASVigilanceLevelStatus_DASUnavailable" ;
VAL_ 2432690512 ACC_SGOFaultCondStat_Door 1 "DoorIndicationRqst_IndicationRequested" 0 "DoorIndicationRqst_NoIndicationRequested" ;
VAL_ 2432690512 ACCTargetDetected 3 "ACCTargetDetected_TakeNoAction" 2 "ACCTargetDetected_Reserved" 1 "ACCTargetDetected_TargetDetected" 0 "ACCTargetDetected_NoTargetsDetected" ;
VAL_ 2432690512 LKSCorrectiveSteeringStatus 7 "LKSCorrectiveSteeringStatus_NotAvailable" 6 "LKSCorrectiveSteeringStatus_Error" 5 "LKSCorrectiveSteeringStatus_Spare2" 4 "LKSCorrectiveSteeringStatus_Spare1" 3 "LKSCorrectiveSteeringStatus_DriverTakeOverRqst" 2 "LKSCorrectiveSteeringStatus_Active" 1 "LKSCorrectiveSteeringStatus_Inactive" 0 "LKSCorrectiveSteeringStatus_Off" ;
VAL_ 2432690512 ACC_SGOFaultCondStat_Other 1 "IndicationRqst_IndicationRequested" 0 "IndicationRqst_NoIndicationRequested" ;
VAL_ 2432690512 LCSSoundSettingStatus 3 "LCSSoundSettingStatus_NotAvailable" 2 "LCSSoundSettingStatus_Error" 1 "LCSSoundSettingStatus_LCSSoundAnabled" 0 "LCSSoundSettingStatus_LCSSoundDisabled" ;
VAL_ 2432690512 ACC_SGOFaultCondStat_Speed 1 "SpeedIndicationRqst_IndicationRequested" 0 "SpeedIndicationRqst_NoIndicationRequested" ;
VAL_ 1369 ParkClimTimerStat_Tue_ISig_4 1 "NotSelectedSelected_Selected" 0 "NotSelectedSelected_NotSelected" ;
VAL_ 1369 ParkClimTimerStat_Mon_ISig_4 1 "NotSelectedSelected_Selected" 0 "NotSelectedSelected_NotSelected" ;
VAL_ 1369 ParkClimTimerStat_Thu_ISig_4 1 "NotSelectedSelected_Selected" 0 "NotSelectedSelected_NotSelected" ;
VAL_ 1369 ParkClimTimerStat_MinRes_ISig_4 7 "MinRes_NotAvailable" 6 "MinRes_Error" 5 "MinRes_NoMinutesResolution" 4 "MinRes_30Minutes" 3 "MinRes_15Minutes" 2 "MinRes_10Minutes" 1 "MinRes_5Minutes" 0 "MinRes_1Minutes" ;
VAL_ 1369 ParkClimTimerStat_Status_ISig_4 3 "ParkHeaterTimer_Status_NotAvailable" 2 "ParkHeaterTimer_Status_TimerDeleted" 1 "ParkHeaterTimer_Status_TimerNotActivated" 0 "ParkHeaterTimer_Status_TimerActivated" ;
VAL_ 1369 ParkClimTimerStat_Sun_ISig_4 1 "NotSelectedSelected_Selected" 0 "NotSelectedSelected_NotSelected" ;
VAL_ 1369 ParkClimTimerStat_Rec_ISig_4 1 "Rec_Recurrent" 0 "Rec_Once" ;
VAL_ 1369 ParkClimTimerStat_Wed_ISig_4 1 "NotSelectedSelected_Selected" 0 "NotSelectedSelected_NotSelected" ;
VAL_ 1369 ParkClimTimerStat_Type_ISig_4 7 "TimerType_NotAvailable" 6 "TimerType_Error" 5 "TimerType_Spare3" 4 "TimerType_Spare2" 3 "TimerType_Spare1" 2 "TimerType_CabClimateTimerWithStartTime" 1 "TimerType_EngineTimerWithReadyTime" 0 "TimerType_CabClimateTimerWithReadyTime" ;
VAL_ 1369 ParkClimTimerStat_Sat_ISig_4 1 "NotSelectedSelected_Selected" 0 "NotSelectedSelected_NotSelected" ;
VAL_ 1369 ParkClimTimerStat_Fri_ISig_4 1 "NotSelectedSelected_Selected" 0 "NotSelectedSelected_NotSelected" ;
VAL_ 551 AutoBlowerLevel_Status_ISig_4 7 "AutoBlowerLevel_NotAvailable" 6 "AutoBlowerLevel_Error" 5 "AutoBlowerLevel_Spare_02" 4 "AutoBlowerLevel_Spare_01" 3 "AutoBlowerLevel_Spare" 2 "AutoBlowerLevel_Low" 1 "AutoBlowerLevel_Normal" 0 "AutoBlowerLevel_High" ;
VAL_ 551 AutoDefogmode_Status_ISig_4 7 "AutoDefogmode_NotAvailable" 6 "AutoDefogmode_Error" 5 "AutoDefogmode_Spare_01" 4 "AutoDefogmode_Spare" 3 "AutoDefogmode_Moderate" 2 "AutoDefogmode_Normal" 1 "AutoDefogmode_Sensitive" 0 "AutoDefogmode_OFF" ;
VAL_ 551 AQSmode_Status_ISig_4 3 "AQSMode_NotAvailable" 2 "AQSMode_Error" 1 "AQSMode_Auto" 0 "AQSMode_OFF" ;
VAL_ 551 ACmode_Status_ISig_4 7 "ACMode_NotAvailable" 6 "ACMode_Error" 5 "ACMode_Spare_01" 4 "ACMode_Spare" 3 "ACMode_ExtraDryCabAir" 2 "ACMode_HumidCabAir" 1 "ACMode_Standard" 0 "ACMode_Economy" ;
VAL_ 2432685120 LKSCSEnableSwitch_rqst 3 "OffOn_NotAvailable" 2 "OffOn_Error" 1 "OffOn_On" 0 "OffOn_Off" ;
VAL_ 2566078272 TrafficAccidentHazardLightRqst_I 3 "Request_NotAvailable" 2 "Request_Error" 1 "Request_RequestActive" 0 "Request_NotRequested" ;
VAL_ 2566078272 GearboxUnlockAuth_stat 7 "GearboxUnlockAuth_stat_NotAvaiable" 6 "GearboxUnlockAuth_stat_Error" 5 "GearboxUnlockAuth_stat_Spare3" 4 "GearboxUnlockAuth_stat_Spare2" 3 "GearboxUnlockAuth_stat_Spare1" 2 "GearboxUnlockAuth_stat_GearEngagementRefused" 1 "GearboxUnlockAuth_stat_GearEngagementAllowed" 0 "GearboxUnlockAuth_stat_Idle" ;
VAL_ 2490646336 MediaSourcesListReq_SInfo_ISig_4 3 "SignalInfo2bitType_NotAvailable" 2 "SignalInfo2bitType_ErrorIndication" 1 "SignalInfo2bitType_Spare" 0 "SignalInfo2bitType_Valid" ;
VAL_ 2499780850 AlmClkSetAlm_LECM_rq_Type_ISig_4 7 "AlarmClkType_NotAvailable" 6 "AlarmClkType_Error" 5 "AlarmClkType_Reserved_02" 4 "AlarmClkType_Reserved_01" 3 "AlarmClkType_Reserved" 2 "AlarmClkType_Radio" 1 "AlarmClkType_Buzzer" 0 "AlarmClkType_NoAudibleNotification" ;
VAL_ 2499780850 AlmClkSetAlm_LECM_rq_ID_ISig_4 127 "AlarmClkID_NotAvailable" 126 "AlarmClkID_Error" 10 "AlarmClkID_Alarm10" 9 "AlarmClkID_Alarm9" 8 "AlarmClkID_Alarm8" 7 "AlarmClkID_Alarm7" 6 "AlarmClkID_Alarm6" 5 "AlarmClkID_Alarm5" 4 "AlarmClkID_Alarm4" 3 "AlarmClkID_Alarm3" 2 "AlarmClkID_Alarm2" 1 "AlarmClkID_Alarm1" 0 "AlarmClkID_NotUsed" ;
VAL_ 2499780850 AlmClkSetAlm_LECM_rq_Stat_ISig_4 3 "AlarmClkStat2_Snoozed" 2 "AlarmClkStat2_Ringing" 1 "AlarmClkStat2_Active" 0 "AlarmClkStat2_Inactive" ;
VAL_ 2499780850 AlmClkSetAlm_LECM_rq_Mode_ISig_4 3 "AlarmClkMode_Spare" 2 "AlarmClkMode_Timer" 1 "AlarmClkMode_Recurrent" 0 "AlarmClkMode_OneTime" ;
VAL_ 2482978624 ExtraHeating_status_ISig_4 3 "OffAuto_NotAvailable" 2 "OffAuto_Error" 1 "OffAuto_AutoStart" 0 "OffAuto_Off" ;
VAL_ 2482978624 FrontalCollisionAccidentStatus_I 3 "NotDetected_NotAvaliable" 2 "NotDetected_Error" 1 "NotDetected_Detected" 0 "NotDetected_NotDetected" ;
VAL_ 2482978624 TipperUpDownRequest_ISig_4 7 "UpDown_NotAvailable" 6 "UpDown_Error" 5 "UpDown_Spare2" 4 "UpDown_Spare1" 3 "UpDown_RequestDownAuto" 2 "UpDown_RequestDown" 1 "UpDown_RequestUp" 0 "UpDown_NoRequest" ;
VAL_ 2482978624 LoadDistributionRequested_ISig_4 15 "LoadDistributionRequested_NotAvailable" 14 "LoadDistributionRequested_Error" 13 "LoadDistributionRequested_Reserved5" 12 "LoadDistributionRequested_Reserved4" 11 "LoadDistributionRequested_Reserved3" 10 "LoadDistributionRequested_Reserved2" 9 "LoadDistributionRequested_Reserved1" 8 "LoadDistributionRequested_DelpressLoadDistribution" 7 "LoadDistributionRequested_VariableLoadDistribution" 6 "LoadDistributionRequested_AlternativeLoadDistribution" 5 "LoadDistributionRequested_MaximumTraction2" 4 "LoadDistributionRequested_MaximumTraction1" 3 "LoadDistributionRequested_OptimizedTraction" 2 "LoadDistributionRequested_NormalLoadDistribution" 1 "LoadDistributionRequested_DefaultLoadDistribution" 0 "LoadDistributionRequested_NoAction" ;
VAL_ 2482978624 TipperTailGateRequest_ISig_4 7 "OpenCloseRqst_NotAvailable" 6 "OpenCloseRqst_Error" 5 "OpenCloseRqst_Spare3" 4 "OpenCloseRqst_Spare2" 3 "OpenCloseRqst_Spare1" 2 "OpenCloseRqst_Close" 1 "OpenCloseRqst_Open" 0 "OpenCloseRqst_NoRequest" ;
VAL_ 2482978624 TipperTippingBodySelection_ISig_ 3 "PrimarySecondary_NotAvailable" 2 "PrimarySecondary_Error" 1 "PrimarySecondary_Secondary" 0 "PrimarySecondary_Primary" ;
VAL_ 2482978624 TipperEmergencyStop_ISig_4 3 "StopRqst_NotAvailable" 2 "StopRqst_Error" 1 "StopRqst_Stop" 0 "StopRqst_NoRequest" ;
VAL_ 2482978624 ExtraBbWrcWatchdog_ISig_4 3 "LowHigh_NotAvailable" 2 "LowHigh_Error" 1 "LowHigh_High" 0 "LowHigh_Low" ;
VAL_ 2482978624 AutoFrontWheelDriveDrvReq 3 "DisengageEngage_NotAvailable" 2 "DisengageEngage_Error" 1 "DisengageEngage_Engage" 0 "DisengageEngage_Disengage" ;
VAL_ 2482978624 ShortStopHeater_cmd_ISig_4 3 "Request_NotAvailable" 2 "Request_Error" 1 "Request_RequestActive" 0 "Request_NotRequested" ;
VAL_ 2482978624 TailLiftMotionRequest_ISig_4 7 "RqstTiltUpDown_NotAvailable" 6 "RqstTiltUpDown_Error" 5 "RqstTiltUpDown_Spare" 4 "RqstTiltUpDown_TiltDown" 3 "RqstTiltUpDown_TiltUp" 2 "RqstTiltUpDown_RequestDown" 1 "RqstTiltUpDown_RequestUp" 0 "RqstTiltUpDown_NoRequest" ;
VAL_ 2482978624 TipperShakerRequest_ISig_4 3 "ShakeRqst_NotAvailable" 2 "ShakeRqst_Error" 1 "ShakeRqst_Shake" 0 "ShakeRqst_NoRequest" ;
VAL_ 2482978624 TipperTarpaulinRequest_ISig_4 7 "CoverUncoverRqst_NotAvailable" 6 "CoverUncoverRqst_Error" 5 "CoverUncoverRqst_Spare3" 4 "CoverUncoverRqst_Spare2" 3 "CoverUncoverRqst_Spare1" 2 "CoverUncoverRqst_Uncover" 1 "CoverUncoverRqst_Cover" 0 "CoverUncoverRqst_NoRequest" ;
VAL_ 2482978624 ABSInhibitRqstDenied 3 "InactiveActive_NotAvailable" 2 "InactiveActive_Error" 1 "InactiveActive_Active" 0 "InactiveActive_Inactive" ;
VAL_ 2499801330 PHTimer_rqst_SetAlarmOper_ISig_4 7 "SetAlarmOperation_NotAvailable" 6 "SetAlarmOperation_Error" 5 "SetAlarmOperation_Spare_02" 4 "SetAlarmOperation_Spare_01" 3 "SetAlarmOperation_Reset" 2 "SetAlarmOperation_Continue" 1 "SetAlarmOperation_Stop" 0 "SetAlarmOperation_Start" ;
VAL_ 2499801330 PHTimer_rqst_DayOfWeekRq_ISig_4 15 "DayOfWeekRq_NotAvailable" 14 "DayOfWeekRq_Error" 13 "DayOfWeekRq_Spare_7" 12 "DayOfWeekRq_Spare_6" 11 "DayOfWeekRq_Spare_5" 10 "DayOfWeekRq_Spare_4" 9 "DayOfWeekRq_Spare_3" 8 "DayOfWeekRq_Spare_2" 7 "DayOfWeekRq_NoDay" 6 "DayOfWeekRq_Sunday" 5 "DayOfWeekRq_Saturday" 4 "DayOfWeekRq_Friday" 3 "DayOfWeekRq_Thursday" 2 "DayOfWeekRq_Wednesday" 1 "DayOfWeekRq_Tuesday" 0 "DayOfWeekRq_Monday" ;
VAL_ 2498741568 CabTilt_rqst 3 "InactiveActive_NotAvailable" 2 "InactiveActive_Error" 1 "InactiveActive_Active" 0 "InactiveActive_Inactive" ;
VAL_ 2498741568 Pto3CabRequest 3 "OffOn_NotAvailable" 2 "OffOn_Error" 1 "OffOn_On" 0 "OffOn_Off" ;
VAL_ 2498741568 Pto4CabRequest 3 "OffOn_NotAvailable" 2 "OffOn_Error" 1 "OffOn_On" 0 "OffOn_Off" ;
VAL_ 2498741568 WindscreenDefrostInd_cmd_ISig_4 1 "IndicationCmd_ONLEDActivated" 0 "IndicationCmd_OFFLEDNotActivated" ;
VAL_ 2498741568 SRSAirbagStatus_ISig_4 3 "SRSAirbagStatus_NotAvailable" 2 "SRSAirbagStatus_ErrorIndicator" 1 "SRSAirbagStatus_DriverAirbagDeployed" 0 "SRSAirbagStatus_NoAirbagDeployed" ;
VAL_ 2498741568 FrontLidAjar_Stat 3 "ClosedOpen_NotAvailable" 2 "ClosedOpen_Error" 1 "ClosedOpen_Open" 0 "ClosedOpen_Closed" ;
VAL_ 2498741568 ParkingHeaterCleaning_Rqst_ISig_ 3 "Request_NotAvailable" 2 "Request_Error" 1 "Request_RequestActive" 0 "Request_NotRequested" ;
VAL_ 2498741568 Pto2CabRequest 3 "OffOn_NotAvailable" 2 "OffOn_Error" 1 "OffOn_On" 0 "OffOn_Off" ;
VAL_ 2498741568 SeatSwivelWarning_rqst 3 "InactiveActive_NotAvailable" 2 "InactiveActive_Error" 1 "InactiveActive_Active" 0 "InactiveActive_Inactive" ;
VAL_ 2498741568 TemporaryRSLDriverRequest 3 "OffOn_NotAvailable" 2 "OffOn_Error" 1 "OffOn_On" 0 "OffOn_Off" ;
VAL_ 2498741568 Pto1CabRequest 3 "OffOn_NotAvailable" 2 "OffOn_Error" 1 "OffOn_On" 0 "OffOn_Off" ;
VAL_ 2483023936 LCS_EnableSwitch_rqst 3 "OffOn_NotAvailable" 2 "OffOn_Error" 1 "OffOn_On" 0 "OffOn_Off" ;
VAL_ 2483023936 EscCrossCountryActivation_rqst 3 "DisableEnable_NotAvailable" 2 "DisableEnable_Error" 1 "DisableEnable_Enable" 0 "DisableEnable_Disable" ;
VAL_ 2483023936 StaticCornerLightMode 3 "DisableEnable_NotAvailable" 2 "DisableEnable_Error" 1 "DisableEnable_Enable" 0 "DisableEnable_Disable" ;
VAL_ 2483023936 SplitBoxDifflockActvnDrvrRqst_IS 3 "DisengageEngage_NotAvailable" 2 "DisengageEngage_Error" 1 "DisengageEngage_Engage" 0 "DisengageEngage_Disengage" ;
VAL_ 2483023936 ATCFrontWheelDriveRequest 3 "AutomaticOffOn_NotAvailable" 2 "AutomaticOffOn_Error" 1 "AutomaticOffOn_AutomaticOn" 0 "AutomaticOffOn_AutomaticOff" ;
VAL_ 2483023936 ConstructionSwitch_stat 3 "OffOn_NotAvailable" 2 "OffOn_Error" 1 "OffOn_On" 0 "OffOn_Off" ;
VAL_ 2483023936 EscCabActionRequest 7 "EscActionRequest_NotAvailable" 6 "EscActionRequest_Error" 5 "EscActionRequest_Spare" 4 "EscActionRequest_Set" 3 "EscActionRequest_Decrease" 2 "EscActionRequest_Increase" 1 "EscActionRequest_Resume" 0 "EscActionRequest_NoRequest" ;
VAL_ 2483023936 AdjustRequestForIdle 7 "EngineSpeedRequest_NotAvailable" 6 "EngineSpeedRequest_Error" 5 "EngineSpeedRequest_Spare" 4 "EngineSpeedRequest_Decrease" 3 "EngineSpeedRequest_Increase" 2 "EngineSpeedRequest_Activate" 1 "EngineSpeedRequest_Off" 0 "EngineSpeedRequest_NoRequest" ;
VAL_ 2483023936 SCL_LogicPowerOutput_stat 3 "SCL_PowerOutput_stat_NotAvailable" 2 "SCL_PowerOutput_stat_Error" 1 "SCL_PowerOutput_stat_FaultDetected" 0 "SCL_PowerOutput_stat_NoFaultDetected" ;
VAL_ 2483023936 StatTrailerBrakeSwitchStatus 3 "PushButtonStatus_NotAvailable" 2 "PushButtonStatus_Error" 1 "PushButtonStatus_Pushed" 0 "PushButtonStatus_Neutral" ;
VAL_ 2483023936 RoofHatch_HMI_rqst 7 "RoofHatch_HMI_rqst_NotAvailable" 6 "RoofHatch_HMI_rqst_ErrorIndicator" 5 "RoofHatch_HMI_rqst_SpareValue_02" 4 "RoofHatch_HMI_rqst_SpareValue_01" 3 "RoofHatch_HMI_rqst_SpareValue" 2 "RoofHatch_HMI_rqst_Open" 1 "RoofHatch_HMI_rqst_Close" 0 "RoofHatch_HMI_rqst_NoAction" ;
VAL_ 2483023936 EscCabEnable 3 "DisableEnable_NotAvailable" 2 "DisableEnable_Error" 1 "DisableEnable_Enable" 0 "DisableEnable_Disable" ;
VAL_ 2483023936 ExtraSideMarkers_Rqst 3 "NeutralPushed_NotAvailable" 2 "NeutralPushed_Error" 1 "NeutralPushed_Pushed" 0 "NeutralPushed_Neutral" ;
VAL_ 2483023936 LevelingThumbwheel_stat 31 "Thumbwheel_stat_NotAvaliable" 30 "Thumbwheel_stat_Error" 29 "Thumbwheel_stat_Spare_12" 28 "Thumbwheel_stat_Spare_11" 27 "Thumbwheel_stat_Spare_10" 26 "Thumbwheel_stat_Spare_09" 25 "Thumbwheel_stat_Spare_08" 24 "Thumbwheel_stat_Spare_07" 23 "Thumbwheel_stat_Spare_06" 22 "Thumbwheel_stat_Spare_05" 21 "Thumbwheel_stat_Spare_04" 20 "Thumbwheel_stat_Spare_03" 19 "Thumbwheel_stat_Spare_02" 18 "Thumbwheel_stat_Spare_01" 17 "Thumbwheel_stat_Spare" 16 "Thumbwheel_stat_ThumbWheelPos16" 15 "Thumbwheel_stat_ThumbWheelPos15" 14 "Thumbwheel_stat_ThumbWheelPos14" 13 "Thumbwheel_stat_ThumbWheelPos13" 12 "Thumbwheel_stat_ThumbWheelPos12" 11 "Thumbwheel_stat_ThumbWheelPos11" 10 "Thumbwheel_stat_ThumbWheelPos10" 9 "Thumbwheel_stat_ThumbWheelPos9" 8 "Thumbwheel_stat_ThumbWheelPos8" 7 "Thumbwheel_stat_ThumbWheelPos7" 6 "Thumbwheel_stat_ThumbWheelPos6" 5 "Thumbwheel_stat_ThumbWheelPos5" 4 "Thumbwheel_stat_ThumbWheelPos4" 3 "Thumbwheel_stat_ThumbWheelPos3" 2 "Thumbwheel_stat_ThumbWheelPos2" 1 "Thumbwheel_stat_ThumbWheelPos1" 0 "Thumbwheel_stat_ThumbWheelPos0" ;
VAL_ 2483023936 DASActivation_rqst 3 "OffOn_NotAvailable" 2 "OffOn_Error" 1 "OffOn_On" 0 "OffOn_Off" ;
VAL_ 2483023936 DriverSeatBeltSwitch_ISig_4 3 "DriverSeatBeltSwitch_NotAvailable" 2 "DriverSeatBeltSwitch_Error" 1 "DriverSeatBeltSwitch_SeatBeltBuckledFastened" 0 "DriverSeatBeltSwitch_SeatBeltUnbuckledUnfastened" ;
VAL_ 2483023936 PinCode_stat 7 "PinCode_stat_NotAvailable" 6 "PinCode_stat_Error" 3 "PinCode_stat_GoodPinCode" 2 "PinCode_stat_WrongPinCode" 1 "PinCode_stat_NoPinCodeEntered" 0 "PinCode_stat_Idle" ;
VAL_ 2483023936 WarmUp_Request 3 "DisableEnable_NotAvailable" 2 "DisableEnable_Error" 1 "DisableEnable_Enable" 0 "DisableEnable_Disable" ;
VAL_ 2483023936 LKSEnableSwitch_rqst 3 "OffOn_NotAvailable" 2 "OffOn_Error" 1 "OffOn_On" 0 "OffOn_Off" ;
VAL_ 2515579712 AlmClkSnze_LECM_rqst_ID_ISig_4 127 "AlarmClkID_NotAvailable" 126 "AlarmClkID_Error" 10 "AlarmClkID_Alarm10" 9 "AlarmClkID_Alarm9" 8 "AlarmClkID_Alarm8" 7 "AlarmClkID_Alarm7" 6 "AlarmClkID_Alarm6" 5 "AlarmClkID_Alarm5" 4 "AlarmClkID_Alarm4" 3 "AlarmClkID_Alarm3" 2 "AlarmClkID_Alarm2" 1 "AlarmClkID_Alarm1" 0 "AlarmClkID_NotUsed" ;
VAL_ 2515579712 AlmClkSetCurAlm_rqst_ID 127 "AlarmClkID_NotAvailable" 126 "AlarmClkID_Error" 10 "AlarmClkID_Alarm10" 9 "AlarmClkID_Alarm9" 8 "AlarmClkID_Alarm8" 7 "AlarmClkID_Alarm7" 6 "AlarmClkID_Alarm6" 5 "AlarmClkID_Alarm5" 4 "AlarmClkID_Alarm4" 3 "AlarmClkID_Alarm3" 2 "AlarmClkID_Alarm2" 1 "AlarmClkID_Alarm1" 0 "AlarmClkID_NotUsed" ;
VAL_ 2515579712 AlmClkSnze_LECM_rqst_Action_ISig 7 "AlmClkSnzeAction_NotAvailable" 6 "AlmClkSnzeAction_Error" 5 "AlmClkSnzeAction_Spare02" 4 "AlmClkSnzeAction_Spare01" 3 "AlmClkSnzeAction_Spare" 2 "AlmClkSnzeAction_RequestToTurnAlarmOff" 1 "AlmClkSnzeAction_RequestToSnoozeAlarm" 0 "AlmClkSnzeAction_NoRequest" ;
VAL_ 2515579712 AlmClkSetCurAlm_rqst_Stat 3 "AlarmClkStat_Spare" 2 "AlarmClkStat_NoUsed" 1 "AlarmClkStat_Active" 0 "AlarmClkStat_Inactive" ;
VAL_ 2515579712 CollSituationHMICtrlRequestVM 7 "CollSituationHMICtrlRequestVM_NotAvailable" 6 "CollSituationHMICtrlRequestVM_Spare4" 5 "CollSituationHMICtrlRequestVM_Spare3" 4 "CollSituationHMICtrlRequestVM_Spare2" 3 "CollSituationHMICtrlRequestVM_Spare1" 2 "CollSituationHMICtrlRequestVM_FCWdisabledOnAftermarket" 1 "CollSituationHMICtrlRequestVM_CM_FCWdisabledOnAftermarket" 0 "CollSituationHMICtrlRequestVM_NoIndication" ;
VAL_ 2515579712 AlmClkSetCurAlm_rqst_Type 7 "AlarmClkType_NotAvailable" 6 "AlarmClkType_Error" 5 "AlarmClkType_Reserved_02" 4 "AlarmClkType_Reserved_01" 3 "AlarmClkType_Reserved" 2 "AlarmClkType_Radio" 1 "AlarmClkType_Buzzer" 0 "AlarmClkType_NoAudibleNotification" ;
VAL_ 2515579712 WRC_Docking_stat_ISig_4 3 "Docking_stat_NotAvailable" 2 "Docking_stat_Error" 1 "Docking_stat_Docked" 0 "Docking_stat_Undocked" ;
VAL_ 2482995008 MirrorSelectRightMainBtn_stat_IS 3 "PushButtonStatus_NotAvailable" 2 "PushButtonStatus_Error" 1 "PushButtonStatus_Pushed" 0 "PushButtonStatus_Neutral" ;
VAL_ 2482995008 WRCEngineStopRequest_ISig_4 3 "PushButtonStatus_NotAvailable" 2 "PushButtonStatus_Error" 1 "PushButtonStatus_Pushed" 0 "PushButtonStatus_Neutral" ;
VAL_ 2482995008 LiftAxle1DirectControl_ISig_4 7 "LiftAxleLiftPositionRequest_NotAvailable" 6 "LiftAxleLiftPositionRequest_Error" 5 "LiftAxleLiftPositionRequest_Reserved_02" 4 "LiftAxleLiftPositionRequest_Reserved_01" 3 "LiftAxleLiftPositionRequest_Reserved" 2 "LiftAxleLiftPositionRequest_Up" 1 "LiftAxleLiftPositionRequest_Down" 0 "LiftAxleLiftPositionRequest_Idle" ;
VAL_ 2482995008 MirrorSelectRightWideBtn_stat_IS 3 "PushButtonStatus_NotAvailable" 2 "PushButtonStatus_Error" 1 "PushButtonStatus_Pushed" 0 "PushButtonStatus_Neutral" ;
VAL_ 2482995008 PanicAlarmFromKeyfob_rqst 3 "Request_NotAvailable" 2 "Request_Error" 1 "Request_RequestActive" 0 "Request_NotRequested" ;
VAL_ 2482995008 ParkingClimate_IndicationCmd_ISi 7 "ParkingClimate_IndicationCmd_NotAvailable" 6 "ParkingClimate_IndicationCmd_Error" 5 "ParkingClimate_IndicationCmd_Spare_01" 4 "ParkingClimate_IndicationCmd_ShortStopHeaterActivated" 3 "ParkingClimate_IndicationCmd_ParkCoolWithoutCompActivReducedMode" 2 "ParkingClimate_IndicationCmd_ParkCoolWithCompActivFullMode" 1 "ParkingClimate_IndicationCmd_ParkingHeaterActivated" 0 "ParkingClimate_IndicationCmd_NoSystemActivated" ;
VAL_ 2482995008 MirrorSelectLeftWideBtn_stat_ISi 3 "PushButtonStatus_NotAvailable" 2 "PushButtonStatus_Error" 1 "PushButtonStatus_Pushed" 0 "PushButtonStatus_Neutral" ;
VAL_ 2482995008 WRCEngineStartRequest_ISig_4 3 "PushButtonStatus_NotAvailable" 2 "PushButtonStatus_Error" 1 "PushButtonStatus_Pushed" 0 "PushButtonStatus_Neutral" ;
VAL_ 2482995008 PW_Left_DS_SwStatus_ISig_4 7 "A5PosSwitchStatus_NotAvailable" 6 "A5PosSwitchStatus_Error" 5 "A5PosSwitchStatus_Spare" 4 "A5PosSwitchStatus_2StepLower" 3 "A5PosSwitchStatus_Lower" 2 "A5PosSwitchStatus_2StepUpper" 1 "A5PosSwitchStatus_Upper" 0 "A5PosSwitchStatus_Neutral" ;
VAL_ 2482995008 RegenerationSwitchStatus 7 "A3PosSwitchStatus_NotAvailable" 6 "A3PosSwitchStatus_Error" 5 "A3PosSwitchStatus_Spare_02" 4 "A3PosSwitchStatus_Spare_01" 3 "A3PosSwitchStatus_Spare" 2 "A3PosSwitchStatus_Upper" 1 "A3PosSwitchStatus_Lower" 0 "A3PosSwitchStatus_Middle" ;
VAL_ 2482995008 PW_Right_DS_SwStatus_ISig_4 7 "A5PosSwitchStatus_NotAvailable" 6 "A5PosSwitchStatus_Error" 5 "A5PosSwitchStatus_Spare" 4 "A5PosSwitchStatus_2StepLower" 3 "A5PosSwitchStatus_Lower" 2 "A5PosSwitchStatus_2StepUpper" 1 "A5PosSwitchStatus_Upper" 0 "A5PosSwitchStatus_Neutral" ;
VAL_ 2482995008 DoorLock_stat_ISig_4 15 "DoorLock_stat_NotAvailable" 14 "DoorLock_stat_Error" 4 "DoorLock_stat_BothDoorsAreLocked" 3 "DoorLock_stat_PassengerDoorIsUnlocked" 2 "DoorLock_stat_DriverDoorIsUnlocked" 1 "DoorLock_stat_BothDoorsAreUnlocked" 0 "DoorLock_stat_Idle" ;
VAL_ 2482995008 LuggageAjar_stat 7 "DoorAjar_stat_NotAvailable" 6 "DoorAjar_stat_Error" 2 "DoorAjar_stat_DoorOpen" 1 "DoorAjar_stat_DoorClosed" 0 "DoorAjar_stat_Idle" ;
VAL_ 2482995008 AlarmStatus_stat_ISig_4 15 "AlarmStatus_stat_NotAvailable" 14 "AlarmStatus_stat_Error" 13 "AlarmStatus_stat_Spare_06" 12 "AlarmStatus_stat_Spare_05" 11 "AlarmStatus_stat_Spare_04" 10 "AlarmStatus_stat_Spare_03" 9 "AlarmStatus_stat_Spare_02" 8 "AlarmStatus_stat_Spare_01" 7 "AlarmStatus_stat_TamperMode" 6 "AlarmStatus_stat_ServiceMode" 5 "AlarmStatus_stat_AlarmMode" 4 "AlarmStatus_stat_PanicMode" 3 "AlarmStatus_stat_UnsetMode" 2 "AlarmStatus_stat_ReduceSetMode" 1 "AlarmStatus_stat_SetMode" 0 "AlarmStatus_stat_Idle" ;
VAL_ 2482995008 AlarmTriggeringCause_stat_ISig_4 15 "AlarmTriggeringCause_stat_NotAvailable" 14 "AlarmTriggeringCause_stat_Error" 10 "AlarmTriggeringCause_stat_OtherTamperIssues" 9 "AlarmTriggeringCause_stat_DoorsConnectionTampered" 8 "AlarmTriggeringCause_stat_SirenConnectionTampered" 7 "AlarmTriggeringCause_stat_TrailerAlarmTriggered" 6 "AlarmTriggeringCause_stat_FrontHatchOpened" 5 "AlarmTriggeringCause_stat_LuggageCompartementOpened" 4 "AlarmTriggeringCause_stat_CabTilted" 3 "AlarmTriggeringCause_stat_MotionSensorTriggered" 2 "AlarmTriggeringCause_stat_PassengerDoorOpened" 1 "AlarmTriggeringCause_stat_DriverDoorOpened" 0 "AlarmTriggeringCause_stat_Idle" ;
VAL_ 2482995008 DoorsAjar_stat_ISig_4 7 "DoorsAjar_stat_NotAvailable" 6 "DoorsAjar_stat_Error" 5 "DoorsAjar_stat_Spare" 4 "DoorsAjar_stat_BothDoorsAreOpen" 3 "DoorsAjar_stat_PassengerDoorIsOpen" 2 "DoorsAjar_stat_DriverDoorIsOpen" 1 "DoorsAjar_stat_BothDoorsAreClosed" 0 "DoorsAjar_stat_Idle" ;
VAL_ 2482995008 DoorAutoFunction_rqst 3 "OffOn_NotAvailable" 2 "OffOn_Error" 1 "OffOn_On" 0 "OffOn_Off" ;
VAL_ 2482995008 MirrorSelectLeftMainBtn_stat_ISi 3 "PushButtonStatus_NotAvailable" 2 "PushButtonStatus_Error" 1 "PushButtonStatus_Pushed" 0 "PushButtonStatus_Neutral" ;
SIG_GROUP_ 2147485152 DiagFaultStat_Alarm_sg_ISig_4 1 : DiagFaultStat_Alarm_DtcIdA_ISig_ DiagFaultStat_Alarm_EcuAdr_ISig_ DiagFaultStat_Alarm_FailTB_ISig_ DiagFaultStat_Alarm_FailTA_ISig_ DiagFaultStat_Alarm_DtcIdB_ISig_;
SIG_GROUP_ 2147485137 DiagFaultStat_APM_sg_ISig_4 1 : DiagFaultStat_APM_DtcIdA_ISig_4 DiagFaultStat_APM_EcuAdr_ISig_4 DiagFaultStat_APM_FailTB_ISig_4 DiagFaultStat_APM_DtcIdB_ISig_4 DiagFaultStat_APM_FailTA_ISig_4;
SIG_GROUP_ 2432640336 GlareFreeArea02_sg_ISig_4 1 : GlareFreeArea02_LeftAngle_ISig_4 GlareFreeArea02_RightAngle_ISig_ GlareFreeArea02_Distance_ISig_4;
SIG_GROUP_ 2432639568 GlareFreeArea03_sg_ISig_4 1 : GlareFreeArea03_Distance_ISig_4 GlareFreeArea03_LeftAngle_ISig_4 GlareFreeArea03_RightAngle_ISig_;
SIG_GROUP_ 2432639568 GlareFreeArea01_sg_ISig_4 1 : GlareFreeArea01_LeftAngle_ISig_4 GlareFreeArea01_Distance_ISig_4 GlareFreeArea01_RightAngle_ISig_;
SIG_GROUP_ 2466246992 XARDACU_sg 1 : XARDACU_ControlMode XARDACU_AccelDemand;
SIG_GROUP_ 2432690512 ACC_SGOFaultCondStat_sg 1 : ACC_SGOFaultCondStat_SeatBelt ACC_SGOFaultCondStat_SigStat ACC_SGOFaultCondStat_Target ACC_SGOFaultCondStat_Door ACC_SGOFaultCondStat_Other ACC_SGOFaultCondStat_Speed;
SIG_GROUP_ 1369 ParkClimTimerStat_sg_ISig_4 1 : ParkClimTimerStat_Tue_ISig_4 ParkClimTimerStat_Mon_ISig_4 ParkClimTimerStat_Hrs_ISig_4 ParkClimTimerStat_TotalNoTimers_ ParkClimTimerStat_Thu_ISig_4 ParkClimTimerStat_MinRes_ISig_4 ParkClimTimerStat_Status_ISig_4 ParkClimTimerStat_Sun_ISig_4 ParkClimTimerStat_TimerNr_ISig_4 ParkClimTimerStat_Rec_ISig_4 ParkClimTimerStat_Wed_ISig_4 ParkClimTimerStat_Min_ISig_4 ParkClimTimerStat_Type_ISig_4 ParkClimTimerStat_Sat_ISig_4 ParkClimTimerStat_Temp_ISig_4 ParkClimTimerStat_Dur_ISig_4 ParkClimTimerStat_Fri_ISig_4;
SIG_GROUP_ 2490646336 MediaSourcesListReq_sg_ISig_4 1 : MediaSourcesListReq_SInfo_ISig_4 MediaSourcesListReq_Items_ISig_4 MediaSourcesListReq_ItemID_ISig_;
SIG_GROUP_ 2499780850 AlmClkSetAlm_LECM_rq_sg_ISig_4 1 : AlmClkSetAlm_LECM_rq_Type_ISig_4 AlmClkSetAlm_LECM_rq_ID_ISig_4 AlmClkSetAlm_LECM_rq_SetHr_ISig_ AlmClkSetAlm_LECM_rq_Stat_ISig_4 AlmClkSetAlm_LECM_rq_SetMin_ISig AlmClkSetAlm_LECM_rq_DaySet_ISig AlmClkSetAlm_LECM_rq_Mode_ISig_4;
SIG_GROUP_ 2499801330 PHTimer_rqst_sg_ISig_4 1 : PHTimer_rqst_Hours_ISig_4 PHTimer_rqst_Minutes_ISig_4 PHTimer_rqst_SetAlarmOper_ISig_4 PHTimer_rqst_DayOfWeekRq_ISig_4;
SIG_GROUP_ 2515579712 AlmClkSnze_LECM_rqst_sg_ISig_4 1 : AlmClkSnze_LECM_rqst_ID_ISig_4 AlmClkSnze_LECM_rqst_Action_ISig;
SIG_GROUP_ 2515579712 AlmClkSetCurAlm_rqst_sg 1 : AlmClkSetCurAlm_rqst_ID AlmClkSetCurAlm_rqst_Stat AlmClkSetCurAlm_rqst_SetMin AlmClkSetCurAlm_rqst_SetHr AlmClkSetCurAlm_rqst_Type;
